VERSION ""

NS_ :

BS_:

BU_: EMS EAS

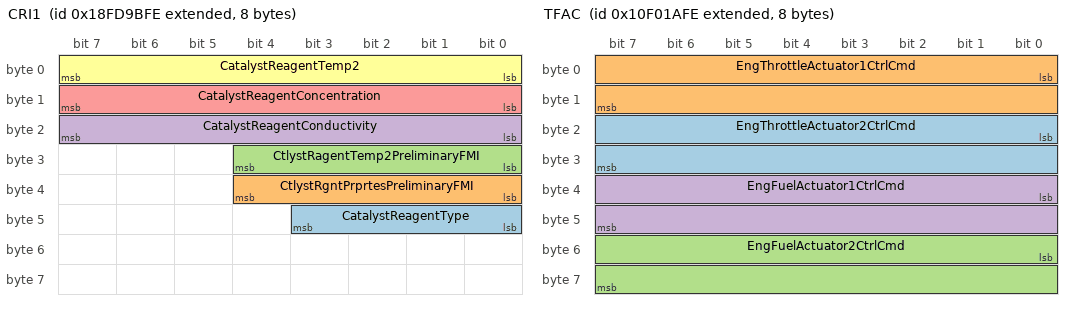
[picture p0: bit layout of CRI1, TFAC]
BO_ 2566757374 CRI1: 8 Vector__XXX
 SG_ CatalystReagentType : 40|4@1+ (1,0) [0|15] "" Vector__XXX
 SG_ CtlystRgntPrprtesPreliminaryFMI : 32|5@1+ (1,0) [0|31] "" Vector__XXX
 SG_ CtlystRagentTemp2PreliminaryFMI : 24|5@1+ (1,0) [0|31] "" Vector__XXX
 SG_ CatalystReagentConductivity : 16|8@1+ (5,0) [0|1250] "microSiemens/mm" Vector__XXX
 SG_ CatalystReagentConcentration : 8|8@1+ (0.25,0) [0|62.5] "%" Vector__XXX
 SG_ CatalystReagentTemp2 : 0|8@1+ (1,-40) [-40|210] "deg" Vector__XXX

BO_ 2566756862 AHI2: 16 Vector__XXX
 SG_ AftrTrtmnt2TtlNmbrOfActvRgnrtns : 96|32@1+ (1,0) [0|4294967295] "counts" Vector__XXX
 SG_ AftrTreatment2TotalDisabledTime : 64|32@1+ (1,0) [0|4211081215] "s" Vector__XXX
 SG_ AftrTrtmnt2TtalRegenerationTime : 32|32@1+ (1,0) [0|4211081215] "s" Vector__XXX
 SG_ AfterTreatment2TotalFuelUsed : 0|32@1+ (0.5,0) [0|2105540607.5] "L" Vector__XXX

BO_ 2566758654 AFC2: 8 Vector__XXX
 SG_ Aftrtratment2FuelEnableActuator : 54|2@1+ (1,0) [0|3] "" Vector__XXX
 SG_ Aftrtratment2RegenerationStatus : 52|2@1+ (1,0) [0|3] "" Vector__XXX
 SG_ Aftertreatment2Ignt : 50|2@1+ (1,0) [0|3] "" Vector__XXX
 SG_ Aftertreatment2FuelPressCtrl : 32|16@1+ (0.0025,0) [0|160.6375] "%" Vector__XXX
 SG_ Aftertreatment2FuelRate : 16|16@1+ (0.05,0) [0|3212.75] "L/h" Vector__XXX
 SG_ Aftertreatment2FuelPress : 0|16@1+ (0.1,0) [0|6425.5] "kPa" Vector__XXX

BO_ 2566758910 AFC1: 8 Vector__XXX
 SG_ Aftrtratment1FuelEnableActuator : 54|2@1+ (1,0) [0|3] "" Vector__XXX
 SG_ Aftrtratment1RegenerationStatus : 52|2@1+ (1,0) [0|3] "" Vector__XXX
 SG_ Aftertreatment1Ignt : 50|2@1+ (1,0) [0|3] "" Vector__XXX
 SG_ Aftertreatment1FuelPressCtrl : 32|16@1+ (0.0025,0) [0|160.6375] "%" Vector__XXX
 SG_ Aftertreatment1FuelRate : 16|16@1+ (0.05,0) [0|3212.75] "L/h" Vector__XXX
 SG_ Aftertreatment1FuelPress : 0|16@1+ (0.1,0) [0|6425.5] "kPa" Vector__XXX

BO_ 2566758142 AAC2: 8 Vector__XXX
 SG_ Aftrtreatment2AirEnableActuator : 62|2@1+ (1,0) [0|3] "" Vector__XXX
 SG_ Aftertreatment2PurgeAirActuator : 60|2@1+ (1,0) [0|3] "" Vector__XXX
 SG_ Aftrtrtmnt2AtmzationAirActuator : 58|2@1+ (1,0) [0|3] "" Vector__XXX
 SG_ Aftertreatment2AirSystemRelay : 56|2@1+ (1,0) [0|3] "" Vector__XXX
 SG_ Aftrtrtment2AirPressActuatorPos : 48|8@1+ (0.4,0) [0|100] "%" Vector__XXX
 SG_ Aftertreatment2AirPressCtrl : 32|16@1+ (0.0025,0) [0|160.6375] "%" Vector__XXX
 SG_ Aftertreatment2PurgeAirPress : 16|16@1+ (0.1,0) [0|6425.5] "kPa" Vector__XXX
 SG_ Aftertreatment2SupplyAirPress : 0|16@1+ (0.1,0) [0|6425.5] "kPa" Vector__XXX

BO_ 2566758398 AAC1: 8 Vector__XXX
 SG_ Aftrtreatment1AirEnableActuator : 62|2@1+ (1,0) [0|3] "" Vector__XXX
 SG_ Aftertreatment1PurgeAirActuator : 60|2@1+ (1,0) [0|3] "" Vector__XXX
 SG_ Aftrtrtmnt1AtmzationAirActuator : 58|2@1+ (1,0) [0|3] "" Vector__XXX
 SG_ Aftertreatment1AirSystemRelay : 56|2@1+ (1,0) [0|3] "" Vector__XXX
 SG_ Aftrtrtment1AirPressActuatorPos : 48|8@1+ (0.4,0) [0|100] "%" Vector__XXX
 SG_ Aftertreatment1AirPressCtrl : 32|16@1+ (0.0025,0) [0|160.6375] "%" Vector__XXX
 SG_ Aftertreatment1PurgeAirPress : 16|16@1+ (0.1,0) [0|6425.5] "kPa" Vector__XXX
 SG_ Aftertreatment1SupplyAirPress : 0|16@1+ (0.1,0) [0|6425.5] "kPa" Vector__XXX

BO_ 2566756606 AHI1: 16 Vector__XXX
 SG_ AftrTrtmnt1TtlNmbrOfActvRgnrtns : 96|32@1+ (1,0) [0|4294967295] "counts" Vector__XXX
 SG_ AftrTrtmnt1TtalRegenerationTime : 32|32@1+ (1,0) [0|4211081215] "s" Vector__XXX
 SG_ AftrTreatment1TotalDisabledTime : 64|32@1+ (1,0) [0|4211081215] "s" Vector__XXX
 SG_ AfterTreatment1TotalFuelUsed : 0|32@1+ (0.5,0) [0|2105540607.5] "L" Vector__XXX

BO_ 2364546302 RGAAQ: 8 Vector__XXX
 SG_ RqdGnrtrAvrgLneLineACRMSVoltage : 0|32@1+ (0.0078125,0) [0|32899071] "V" Vector__XXX

BO_ 2431654654 TFAC: 8 Vector__XXX
 SG_ EngThrottleActuator2CtrlCmd : 16|16@1+ (0.0025,0) [0|160.6375] "%" Vector__XXX
 SG_ EngThrottleActuator1CtrlCmd : 0|16@1+ (0.0025,0) [0|160.6375] "%" Vector__XXX
 SG_ EngFuelActuator2CtrlCmd : 48|16@1+ (0.0025,0) [0|160.6375] "%" Vector__XXX
 SG_ EngFuelActuator1CtrlCmd : 32|16@1+ (0.0025,0) [0|160.6375] "%" Vector__XXX

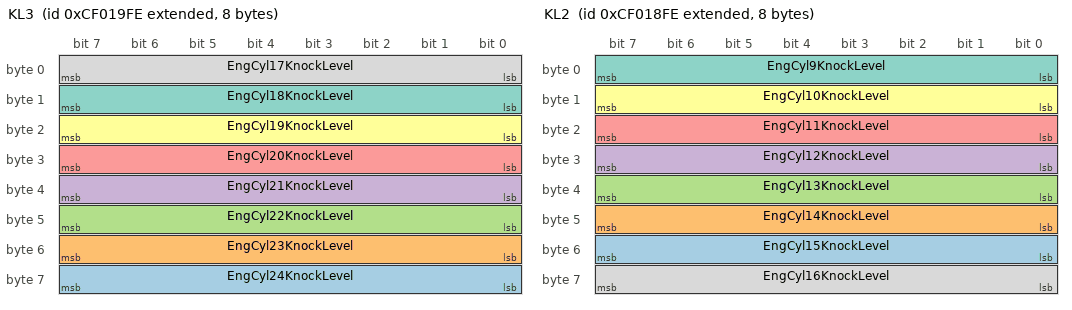
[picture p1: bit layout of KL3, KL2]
BO_ 2364545534 KL3: 8 Vector__XXX
 SG_ EngCyl24KnockLevel : 56|8@1+ (1,0) [0|250] "%" Vector__XXX
 SG_ EngCyl23KnockLevel : 48|8@1+ (1,0) [0|250] "%" Vector__XXX
 SG_ EngCyl22KnockLevel : 40|8@1+ (1,0) [0|250] "%" Vector__XXX
 SG_ EngCyl21KnockLevel : 32|8@1+ (1,0) [0|250] "%" Vector__XXX
 SG_ EngCyl20KnockLevel : 24|8@1+ (1,0) [0|250] "%" Vector__XXX
 SG_ EngCyl19KnockLevel : 16|8@1+ (1,0) [0|250] "%" Vector__XXX
 SG_ EngCyl18KnockLevel : 8|8@1+ (1,0) [0|250] "%" Vector__XXX
 SG_ EngCyl17KnockLevel : 0|8@1+ (1,0) [0|250] "%" Vector__XXX

BO_ 2364545278 KL2: 8 Vector__XXX
 SG_ EngCyl15KnockLevel : 48|8@1+ (1,0) [0|250] "%" Vector__XXX
 SG_ EngCyl14KnockLevel : 40|8@1+ (1,0) [0|250] "%" Vector__XXX
 SG_ EngCyl13KnockLevel : 32|8@1+ (1,0) [0|250] "%" Vector__XXX
 SG_ EngCyl12KnockLevel : 24|8@1+ (1,0) [0|250] "%" Vector__XXX
 SG_ EngCyl11KnockLevel : 16|8@1+ (1,0) [0|250] "%" Vector__XXX
 SG_ EngCyl10KnockLevel : 8|8@1+ (1,0) [0|250] "%" Vector__XXX
 SG_ EngCyl9KnockLevel : 0|8@1+ (1,0) [0|250] "%" Vector__XXX
 SG_ EngCyl16KnockLevel : 56|8@1+ (1,0) [0|250] "%" Vector__XXX

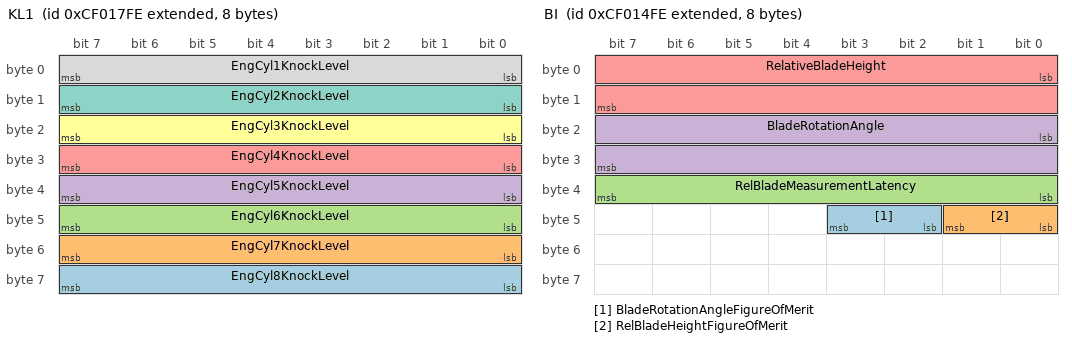
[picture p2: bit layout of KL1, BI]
BO_ 2364545022 KL1: 8 Vector__XXX
 SG_ EngCyl8KnockLevel : 56|8@1+ (1,0) [0|250] "%" Vector__XXX
 SG_ EngCyl7KnockLevel : 48|8@1+ (1,0) [0|250] "%" Vector__XXX
 SG_ EngCyl6KnockLevel : 40|8@1+ (1,0) [0|250] "%" Vector__XXX
 SG_ EngCyl5KnockLevel : 32|8@1+ (1,0) [0|250] "%" Vector__XXX
 SG_ EngCyl4KnockLevel : 24|8@1+ (1,0) [0|250] "%" Vector__XXX
 SG_ EngCyl3KnockLevel : 16|8@1+ (1,0) [0|250] "%" Vector__XXX
 SG_ EngCyl2KnockLevel : 8|8@1+ (1,0) [0|250] "%" Vector__XXX
 SG_ EngCyl1KnockLevel : 0|8@1+ (1,0) [0|250] "%" Vector__XXX

BO_ 2364544766 CCS: 8 Vector__XXX
 SG_ EngCyl9CombustionStatus : 16|2@1+ (1,0) [0|3] "" Vector__XXX
 SG_ EngCyl8CombustionStatus : 14|2@1+ (1,0) [0|3] "" Vector__XXX
 SG_ EngCyl7CombustionStatus : 12|2@1+ (1,0) [0|3] "" Vector__XXX
 SG_ EngCyl6CombustionStatus : 10|2@1+ (1,0) [0|3] "" Vector__XXX
 SG_ EngCyl5CombustionStatus : 8|2@1+ (1,0) [0|3] "" Vector__XXX
 SG_ EngCyl4CombustionStatus : 6|2@1+ (1,0) [0|3] "" Vector__XXX
 SG_ EngCyl3CombustionStatus : 4|2@1+ (1,0) [0|3] "" Vector__XXX
 SG_ EngCyl2CombustionStatus : 2|2@1+ (1,0) [0|3] "" Vector__XXX
 SG_ EngCyl24CombustionStatus : 46|2@1+ (1,0) [0|3] "" Vector__XXX
 SG_ EngCyl23CombustionStatus : 44|2@1+ (1,0) [0|3] "" Vector__XXX
 SG_ EngCyl22CombustionStatus : 42|2@1+ (1,0) [0|3] "" Vector__XXX
 SG_ EngCyl21CombustionStatus : 40|2@1+ (1,0) [0|3] "" Vector__XXX
 SG_ EngCyl20CombustionStatus : 38|2@1+ (1,0) [0|3] "" Vector__XXX
 SG_ EngCyl1CombustionStatus : 0|2@1+ (1,0) [0|3] "" Vector__XXX
 SG_ EngCyl19CombustionStatus : 36|2@1+ (1,0) [0|3] "" Vector__XXX
 SG_ EngCyl18CombustionStatus : 34|2@1+ (1,0) [0|3] "" Vector__XXX
 SG_ EngCyl17CombustionStatus : 32|2@1+ (1,0) [0|3] "" Vector__XXX
 SG_ EngCyl16CombustionStatus : 30|2@1+ (1,0) [0|3] "" Vector__XXX
 SG_ EngCyl15CombustionStatus : 28|2@1+ (1,0) [0|3] "" Vector__XXX
 SG_ EngCyl14CombustionStatus : 26|2@1+ (1,0) [0|3] "" Vector__XXX
 SG_ EngCyl13CombustionStatus : 24|2@1+ (1,0) [0|3] "" Vector__XXX
 SG_ EngCyl12CombustionStatus : 22|2@1+ (1,0) [0|3] "" Vector__XXX
 SG_ EngCyl11CombustionStatus : 20|2@1+ (1,0) [0|3] "" Vector__XXX
 SG_ EngCyl10CombustionStatus : 18|2@1+ (1,0) [0|3] "" Vector__XXX

BO_ 2364544510 RGTARP: 8 Vector__XXX
 SG_ RqGenOverallPowerFactorLagging : 48|2@1+ (1,0) [0|4] "" Vector__XXX
 SG_ RqGeneratorOverallPowerFactor : 32|16@1+ (6.103515625E-005,-1) [-1|2.921814] "" Vector__XXX
 SG_ RqGeneratorTotalACReactivePower : 0|32@1+ (1,-2000000000) [-2000000000|2000000000] "VA" Vector__XXX

BO_ 2364544254 BI: 8 Vector__XXX
 SG_ BladeRotationAngleFigureOfMerit : 42|2@1+ (1,0) [0|3] "" Vector__XXX
 SG_ RelBladeHeightFigureOfMerit : 40|2@1+ (1,0) [0|4] "" Vector__XXX
 SG_ RelBladeMeasurementLatency : 32|8@1+ (0.5,0) [0|125] "ms" Vector__XXX
 SG_ BladeRotationAngle : 16|16@1+ (0.0078125,-200) [-200|301.99] "deg" Vector__XXX
 SG_ RelativeBladeHeight : 0|16@1+ (0.1,-3200) [-3200|3225.5] "mm" Vector__XXX

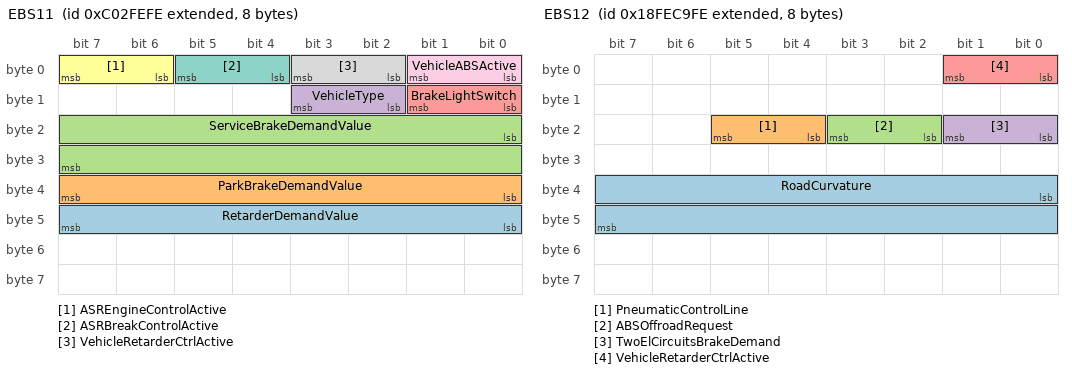
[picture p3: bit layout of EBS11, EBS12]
BO_ 2349006590 EBS11: 8 Vector__XXX
 SG_ RetarderDemandValue : 40|8@1+ (1,-125) [-125|125] "%" Vector__XXX
 SG_ ParkBrakeDemandValue : 32|8@1+ (0.4,0) [0|100] "%" Vector__XXX
 SG_ ServiceBrakeDemandValue : 16|16@1+ (0.01953125,0) [0|1255] "kPa" Vector__XXX
 SG_ VehicleType : 10|2@1+ (1,0) [0|3] "" Vector__XXX
 SG_ BrakeLightSwitch : 8|2@1+ (1,0) [0|3] "" Vector__XXX
 SG_ ASREngineControlActive : 6|2@1+ (1,0) [0|3] "" Vector__XXX
 SG_ ASRBreakControlActive : 4|2@1+ (1,0) [0|3] "" Vector__XXX
 SG_ VehicleRetarderCtrlActive : 2|2@1+ (1,0) [0|3] "" Vector__XXX
 SG_ VehicleABSActive : 0|2@1+ (1,0) [0|1] "" Vector__XXX

BO_ 2566834686 EBS12: 8 Vector__XXX
 SG_ RoadCurvature : 32|16@1+ (0.0078125,-250) [-250|251.992] "1/km" Vector__XXX
 SG_ PneumaticControlLine : 20|2@1+ (1,0) [0|1] "" Vector__XXX
 SG_ ABSOffroadRequest : 18|2@1+ (1,0) [0|1] "" Vector__XXX
 SG_ TwoElCircuitsBrakeDemand : 16|2@1+ (1,0) [0|1] "" Vector__XXX
 SG_ VehicleRetarderCtrlActive : 0|2@1+ (1,0) [0|3] "" Vector__XXX

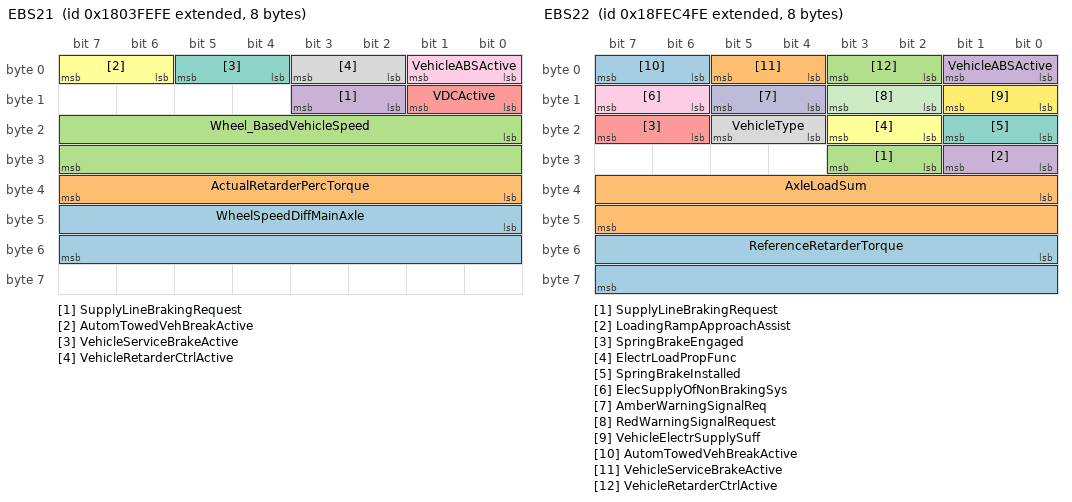
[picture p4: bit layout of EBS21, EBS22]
BO_ 2550398718 EBS21: 8 Vector__XXX
 SG_ WheelSpeedDiffMainAxle : 40|16@1+ (0.00390625,-125) [-125|125] "km/h" Vector__XXX
 SG_ ActualRetarderPercTorque : 32|8@1+ (1,-125) [-125|125] "%" Vector__XXX
 SG_ Wheel_BasedVehicleSpeed : 16|16@1+ (0.00390625,0) [0|251] "km/" Vector__XXX
 SG_ SupplyLineBrakingRequest : 10|2@1+ (1,0) [0|1] "" Vector__XXX
 SG_ VDCActive : 8|2@1+ (1,0) [0|1] "" Vector__XXX
 SG_ AutomTowedVehBreakActive : 6|2@1+ (1,0) [0|1] "" Vector__XXX
 SG_ VehicleServiceBrakeActive : 4|2@1+ (1,0) [0|1] "" Vector__XXX
 SG_ VehicleRetarderCtrlActive : 2|2@1+ (1,0) [0|3] "" Vector__XXX
 SG_ VehicleABSActive : 0|2@1+ (1,0) [0|1] "" Vector__XXX

BO_ 2566833406 EBS22: 8 Vector__XXX
 SG_ ReferenceRetarderTorque : 48|16@1+ (1,0) [0|64255] "Nm" Vector__XXX
 SG_ AxleLoadSum : 32|16@1+ (2,0) [0|128510] "kg" Vector__XXX
 SG_ SupplyLineBrakingRequest : 26|2@1+ (1,0) [0|1] "" Vector__XXX
 SG_ LoadingRampApproachAssist : 24|2@1+ (1,0) [0|1] "" Vector__XXX
 SG_ SpringBrakeEngaged : 22|2@1+ (1,0) [0|1] "" Vector__XXX
 SG_ ElectrLoadPropFunc : 18|2@1+ (1,0) [0|1] "" Vector__XXX
 SG_ SpringBrakeInstalled : 16|2@1+ (1,0) [0|1] "" Vector__XXX
 SG_ VehicleType : 20|2@1+ (1,0) [0|3] "" Vector__XXX
 SG_ ElecSupplyOfNonBrakingSys : 14|2@1+ (1,0) [0|1] "" Vector__XXX
 SG_ AmberWarningSignalReq : 12|2@1+ (1,0) [0|1] "" Vector__XXX
 SG_ RedWarningSignalRequest : 10|2@1+ (1,0) [0|1] "" Vector__XXX
 SG_ VehicleElectrSupplySuff : 8|2@1+ (1,0) [0|1] "" Vector__XXX
 SG_ AutomTowedVehBreakActive : 6|2@1+ (1,0) [0|1] "" Vector__XXX
 SG_ VehicleServiceBrakeActive : 4|2@1+ (1,0) [0|1] "" Vector__XXX
 SG_ VehicleRetarderCtrlActive : 2|2@1+ (1,0) [0|3] "" Vector__XXX
 SG_ VehicleABSActive : 0|2@1+ (1,0) [0|1] "" Vector__XXX

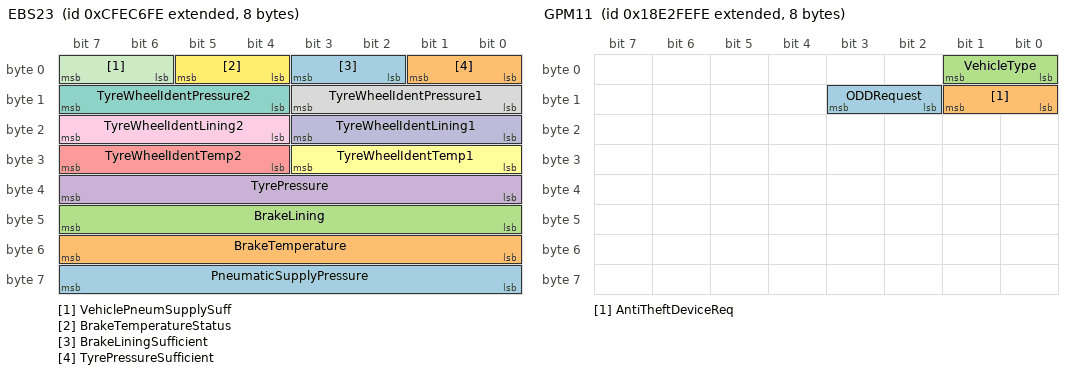
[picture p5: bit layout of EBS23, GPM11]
BO_ 2365507326 EBS23: 8 Vector__XXX
 SG_ PneumaticSupplyPressure : 56|8@1+ (5,0) [0|1250] "kPa" Vector__XXX
 SG_ BrakeTemperature : 48|8@1+ (10,0) [0|2500] "°C" Vector__XXX
 SG_ BrakeLining : 40|8@1+ (0.4,0) [0|100] "%" Vector__XXX
 SG_ TyrePressure : 32|8@1+ (10,0) [0|2500] "kPa" Vector__XXX
 SG_ TyreWheelIdentTemp2 : 28|4@1+ (1,0) [0|15] "" Vector__XXX
 SG_ TyreWheelIdentTemp1 : 24|4@1+ (1,0) [0|15] "" Vector__XXX
 SG_ TyreWheelIdentPressure2 : 12|4@1+ (1,0) [0|15] "" Vector__XXX
 SG_ TyreWheelIdentPressure1 : 8|4@1+ (1,0) [0|15] "" Vector__XXX
 SG_ TyreWheelIdentLining2 : 20|4@1+ (1,0) [0|15] "" Vector__XXX
 SG_ TyreWheelIdentLining1 : 16|4@1+ (1,0) [0|15] "" Vector__XXX
 SG_ VehiclePneumSupplySuff : 6|2@1+ (1,0) [0|1] "" Vector__XXX
 SG_ BrakeTemperatureStatus : 4|2@1+ (1,0) [0|1] "" Vector__XXX
 SG_ BrakeLiningSufficient : 2|2@1+ (1,0) [0|1] "" Vector__XXX
 SG_ TyrePressureSufficient : 0|2@1+ (1,0) [0|1] "" Vector__XXX

BO_ 2565013246 GPM11: 8 Vector__XXX
 SG_ ODDRequest : 10|2@1+ (1,0) [0|3] "" Vector__XXX
 SG_ AntiTheftDeviceReq : 8|2@1+ (1,0) [0|3] "" Vector__XXX
 SG_ VehicleType : 0|2@1+ (1,0) [0|3] "" Vector__XXX

BO_ 2566807038 GPM12: 8 Vector__XXX
 SG_ MaxVehicleSpeedLimit : 32|8@1+ (1,0) [0|250] "km/h" Vector__XXX
 SG_ EngineSpeedUpperLimit : 0|16@1+ (0.125,0) [0|8031.875] "rpm" Vector__XXX
 SG_ EngineSpeedLowerLimit : 16|16@1+ (0.125,0) [0|8191.875] "rpm" Vector__XXX

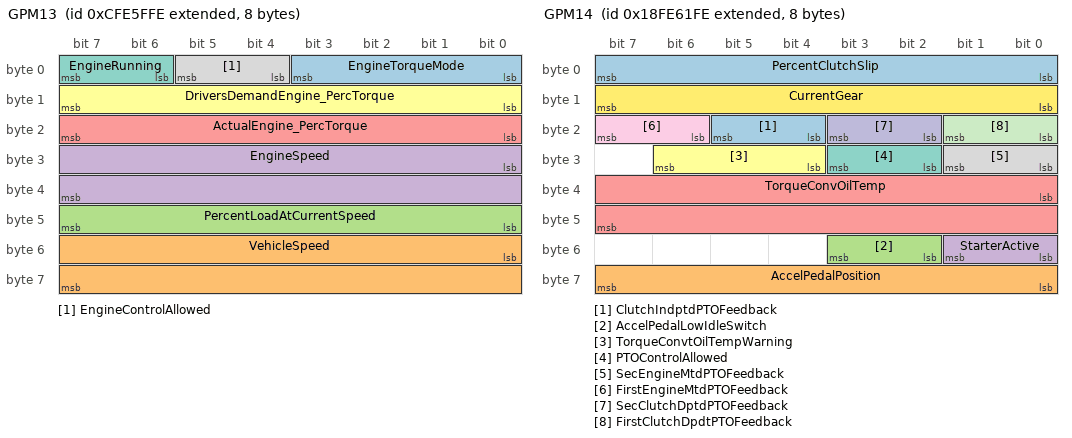
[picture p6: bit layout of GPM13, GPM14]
BO_ 2365480958 GPM13: 8 Vector__XXX
 SG_ EngineTorqueMode : 0|4@1+ (1,0) [0|15] "" Vector__XXX
 SG_ VehicleSpeed : 48|16@1+ (0.00390625,0) [0|250.996] "km/h" Vector__XXX
 SG_ PercentLoadAtCurrentSpeed : 40|8@1+ (1,0) [0|125] "%" Vector__XXX
 SG_ EngineSpeed : 24|16@1+ (0.125,0) [0|8031.88] "rpm" Vector__XXX
 SG_ ActualEngine_PercTorque : 16|8@1+ (1,-125) [-125|125] "%" Vector__XXX
 SG_ DriversDemandEngine_PercTorque : 8|8@1+ (1,-125) [-125|125] "%" Vector__XXX
 SG_ EngineRunning : 6|2@1+ (1,0) [0|1] "" Vector__XXX
 SG_ EngineControlAllowed : 4|2@1+ (1,0) [0|1] "" Vector__XXX

BO_ 2566808062 GPM14: 8 Vector__XXX
 SG_ ClutchIndptdPTOFeedback : 20|2@1+ (1,0) [0|1] "" Vector__XXX
 SG_ AccelPedalPosition : 56|8@1+ (0.4,0) [0|100] "%" Vector__XXX
 SG_ AccelPedalLowIdleSwitch : 50|2@1+ (1,0) [0|1] "" Vector__XXX
 SG_ StarterActive : 48|2@1+ (1,0) [0|1] "" Vector__XXX
 SG_ TorqueConvOilTemp : 32|16@1+ (0.03125,-273) [-273|1735] "°C" Vector__XXX
 SG_ TorqueConvtOilTempWarning : 28|3@1+ (1,0) [0|2] "" Vector__XXX
 SG_ PTOControlAllowed : 26|2@1+ (1,0) [0|1] "" Vector__XXX
 SG_ SecEngineMtdPTOFeedback : 24|2@1+ (1,0) [0|1] "" Vector__XXX
 SG_ FirstEngineMtdPTOFeedback : 22|2@1+ (1,0) [0|1] "" Vector__XXX
 SG_ SecClutchDptdPTOFeedback : 18|2@1+ (1,0) [0|1] "" Vector__XXX
 SG_ FirstClutchDpdtPTOFeedback : 16|2@1+ (1,0) [0|1] "" Vector__XXX
 SG_ CurrentGear : 8|8@1+ (1,-125) [-125|125] "" Vector__XXX
 SG_ PercentClutchSlip : 0|8@1+ (0.4,0) [0|100] "%" Vector__XXX

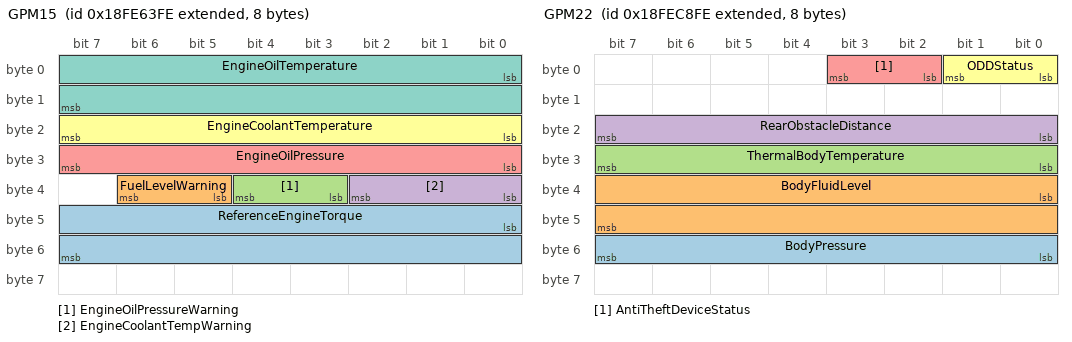
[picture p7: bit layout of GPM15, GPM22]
BO_ 2566808574 GPM15: 8 Vector__XXX
 SG_ ReferenceEngineTorque : 40|16@1+ (1,0) [0|64255] "Nm" Vector__XXX
 SG_ FuelLevelWarning : 37|2@1+ (1,0) [0|1] "" Vector__XXX
 SG_ EngineOilPressureWarning : 35|2@1+ (1,0) [0|1] "" Vector__XXX
 SG_ EngineCoolantTempWarning : 32|3@1+ (1,0) [0|2] "" Vector__XXX
 SG_ EngineOilPressure : 24|8@1+ (4,0) [0|1000] "kPa" Vector__XXX
 SG_ EngineCoolantTemperature : 16|8@1+ (1,-40) [-40|210] "°C" Vector__XXX
 SG_ EngineOilTemperature : 0|16@1+ (0.03125,-273) [-273|1735] "°C" Vector__XXX

BO_ 2566809086 GPM16: 8 Vector__XXX
 SG_ AmbientAirTemperature : 0|16@1+ (0.03125,-273) [-273|1735] "°C" Vector__XXX

BO_ 2564947710 GPM21: 8 Vector__XXX
 SG_ VehicleType : 0|2@1+ (1,0) [0|3] "" Vector__XXX

BO_ 2566834430 GPM22: 8 Vector__XXX
 SG_ BodyPressure : 48|8@1+ (0.1,0) [0|25] "bar" Vector__XXX
 SG_ BodyFluidLevel : 32|16@1+ (2,0) [0|128510] "l" Vector__XXX
 SG_ ThermalBodyTemperature : 24|8@1+ (1,-125) [-125|125] "°C" Vector__XXX
 SG_ RearObstacleDistance : 16|8@1+ (2,0) [0|500] "cm" Vector__XXX
 SG_ AntiTheftDeviceStatus : 2|2@1+ (1,0) [0|1] "" Vector__XXX
 SG_ ODDStatus : 0|2@1+ (1,0) [0|1] "" Vector__XXX

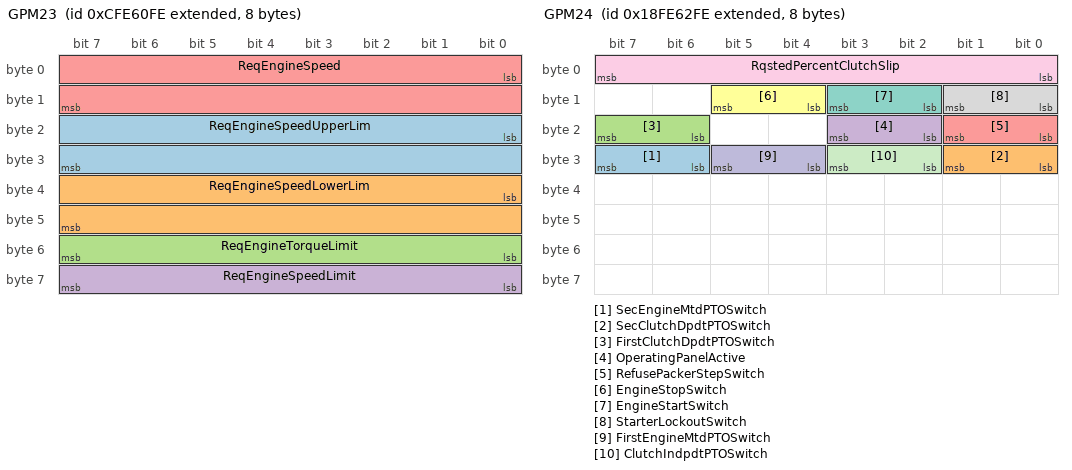
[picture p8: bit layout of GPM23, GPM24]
BO_ 2365481214 GPM23: 8 Vector__XXX
 SG_ ReqEngineSpeedUpperLim : 16|16@1+ (0.125,0) [0|8031.875] "rpm" Vector__XXX
 SG_ ReqEngineSpeedLowerLim : 32|16@1+ (0.125,0) [0|8031.875] "rpm" Vector__XXX
 SG_ ReqEngineTorqueLimit : 48|8@1+ (1,-125) [-125|125] "%" Vector__XXX
 SG_ ReqEngineSpeedLimit : 56|8@1+ (1,0) [0|250] "km/h" Vector__XXX
 SG_ ReqEngineSpeed : 0|16@1+ (0.125,0) [0|8031.875] "rpm" Vector__XXX

BO_ 2566808318 GPM24: 8 Vector__XXX
 SG_ SecEngineMtdPTOSwitch : 30|2@1+ (1,0) [0|1] "" Vector__XXX
 SG_ SecClutchDpdtPTOSwitch : 24|2@1+ (1,0) [0|1] "" Vector__XXX
 SG_ FirstClutchDpdtPTOSwitch : 22|2@1+ (1,0) [0|1] "" Vector__XXX
 SG_ OperatingPanelActive : 18|2@1+ (1,0) [0|1] "" Vector__XXX
 SG_ RefusePackerStepSwitch : 16|2@1+ (1,0) [0|1] "" Vector__XXX
 SG_ EngineStopSwitch : 12|2@1+ (1,0) [0|1] "" Vector__XXX
 SG_ EngineStartSwitch : 10|2@1+ (1,0) [0|3] "" Vector__XXX
 SG_ StarterLockoutSwitch : 8|2@1+ (1,0) [0|1] "" Vector__XXX
 SG_ RqstedPercentClutchSlip : 0|8@1+ (0.4,0) [0|100] "%" Vector__XXX
 SG_ FirstEngineMtdPTOSwitch : 28|2@1+ (1,0) [0|1] "" Vector__XXX
 SG_ ClutchIndpdtPTOSwitch : 26|2@1+ (1,0) [0|1] "" Vector__XXX

BO_ 2566808830 GPM25: 8 Vector__XXX
 SG_ TrailerLeftSideMarkerLight : 20|2@1+ (1,0) [0|3] "" Vector__XXX
 SG_ TrailerLeftReversingLight : 16|2@1+ (1,0) [0|3] "" Vector__XXX
 SG_ TrailerLeftRearWidIndLight : 24|2@1+ (1,0) [0|3] "" Vector__XXX
 SG_ TrailerLeftRearRegPltLight : 32|2@1+ (1,0) [0|3] "" Vector__XXX
 SG_ TrailerLeftRearLight : 8|2@1+ (1,0) [0|3] "" Vector__XXX
 SG_ TrailerLeftRearFogLight : 12|2@1+ (1,0) [0|3] "" Vector__XXX
 SG_ TrailerLeftDirIndLight : 4|2@1+ (1,0) [0|3] "" Vector__XXX
 SG_ TrailerLeftCrnMarkerLight : 28|2@1+ (1,0) [0|3] "" Vector__XXX
 SG_ TrailerInteriorLight : 40|2@1+ (1,0) [0|3] "" Vector__XXX
 SG_ TrailerWorkLamp : 42|2@1+ (1,0) [0|3] "" Vector__XXX
 SG_ TrailerRotatingIdentLight : 38|2@1+ (1,0) [0|3] "" Vector__XXX
 SG_ TrailerRightStopLight : 2|2@1+ (1,0) [0|3] "" Vector__XXX
 SG_ TrailerRightSideMrkLight : 22|2@1+ (1,0) [0|3] "" Vector__XXX
 SG_ TrailerRightReversingLight : 18|2@1+ (1,0) [0|3] "" Vector__XXX
 SG_ TrailRightRearWidIndLight : 26|2@1+ (1,0) [0|3] "" Vector__XXX
 SG_ TrailerRightRearRegPltLight : 34|2@1+ (1,0) [0|3] "" Vector__XXX
 SG_ TrailerRightRearLight : 10|2@1+ (1,0) [0|3] "" Vector__XXX
 SG_ TrailerRightRearFogLight : 14|2@1+ (1,0) [0|3] "" Vector__XXX
 SG_ TrailerRightDirIndLight : 6|2@1+ (1,0) [0|3] "" Vector__XXX
 SG_ TrailerRightCrnMarkerLight : 30|2@1+ (1,0) [0|3] "" Vector__XXX
 SG_ TrailerRearWarningLight : 36|2@1+ (1,0) [0|3] "" Vector__XXX
 SG_ TrailerLeftStopLight : 0|2@1+ (1,0) [0|3] "" Vector__XXX

BO_ 2564554494 ISO15765_Funct: 8 Vector__XXX
 SG_ SN m2 : 0|4@1+ (1,0) [0|15] "" Vector__XXX
 SG_ SeparationTime m3 : 16|8@1+ (1,0) [0|255] "ms" Vector__XXX
 SG_ BlockSize m3 : 8|8@1+ (1,0) [0|255] "" Vector__XXX
 SG_ FlowStatus m3 : 0|4@1+ (1,0) [0|3] "" Vector__XXX
 SG_ FirstFrameDataLength m1 : 3|12@0+ (1,0) [0|4095] "Byte" Vector__XXX
 SG_ SingleFrameDataLength m0 : 0|4@1+ (1,0) [0|7] "Byte" Vector__XXX
 SG_ ProtocolCtrlInformation M : 4|4@1+ (1,0) [0|3] "" Vector__XXX

BO_ 2564488958 ISO15765_Phys: 8 Vector__XXX
 SG_ SN m2 : 0|4@1+ (1,0) [0|15] "" Vector__XXX
 SG_ SeparationTime m3 : 16|8@1+ (1,0) [0|255] "ms" Vector__XXX
 SG_ BlockSize m3 : 8|8@1+ (1,0) [0|255] "" Vector__XXX
 SG_ FlowStatus m3 : 0|4@1+ (1,0) [0|3] "" Vector__XXX
 SG_ FirstFrameDataLength m1 : 3|12@0+ (1,0) [0|4095] "Byte" Vector__XXX
 SG_ SingleFrameDataLength m0 : 0|4@1+ (1,0) [0|7] "Byte" Vector__XXX
 SG_ ProtocolCtrlInformation M : 4|4@1+ (1,0) [0|3] "" Vector__XXX

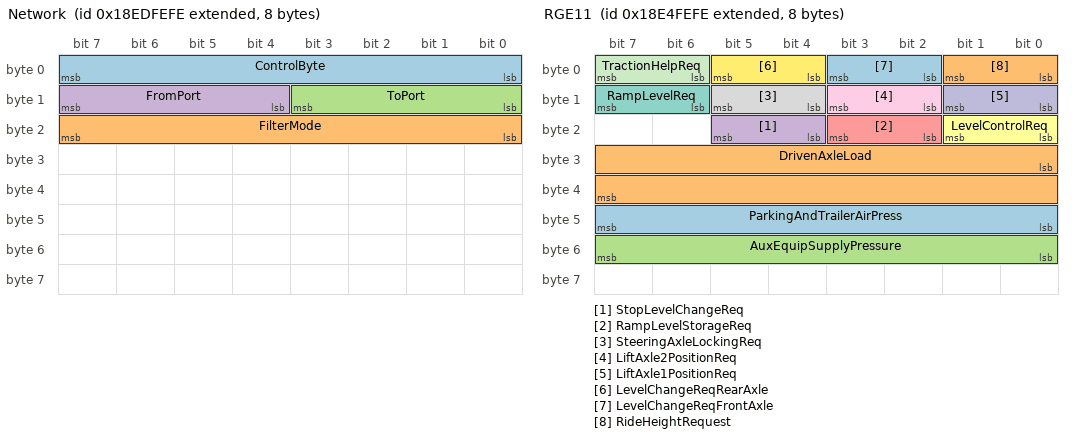
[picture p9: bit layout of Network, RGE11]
BO_ 2565734142 Network: 8 Vector__XXX
 SG_ ControlByte : 0|8@1+ (1,0) [0|255] "" Vector__XXX
 SG_ FilterMode : 16|8@1+ (1,0) [0|255] "" Vector__XXX
 SG_ ToPort : 8|4@1+ (1,0) [0|15] "" Vector__XXX
 SG_ FromPort : 12|4@1+ (1,0) [0|15] "" Vector__XXX

BO_ 2565144318 RGE11: 8 Vector__XXX
 SG_ ParkingAndTrailerAirPress : 40|8@1+ (8,0) [0|2000] "kPa" Vector__XXX
 SG_ DrivenAxleLoad : 24|16@1+ (2,0) [0|128510] "kg" Vector__XXX
 SG_ AuxEquipSupplyPressure : 48|8@1+ (8,0) [0|2000] "kPa" Vector__XXX
 SG_ StopLevelChangeReq : 20|2@1+ (1,0) [0|3] "" Vector__XXX
 SG_ RampLevelStorageReq : 18|2@1+ (1,0) [0|3] "" Vector__XXX
 SG_ LevelControlReq : 16|2@1+ (1,0) [0|3] "" Vector__XXX
 SG_ RampLevelReq : 14|2@1+ (1,0) [0|3] "" Vector__XXX
 SG_ SteeringAxleLockingReq : 12|2@1+ (1,0) [0|3] "" Vector__XXX
 SG_ LiftAxle2PositionReq : 10|2@1+ (1,0) [0|3] "" Vector__XXX
 SG_ LiftAxle1PositionReq : 8|2@1+ (1,0) [0|3] "" Vector__XXX
 SG_ TractionHelpReq : 6|2@1+ (1,0) [0|3] "" Vector__XXX
 SG_ LevelChangeReqRearAxle : 4|2@1+ (1,0) [0|3] "" Vector__XXX
 SG_ LevelChangeReqFrontAxle : 2|2@1+ (1,0) [0|3] "" Vector__XXX
 SG_ RideHeightRequest : 0|2@1+ (1,0) [0|3] "" Vector__XXX

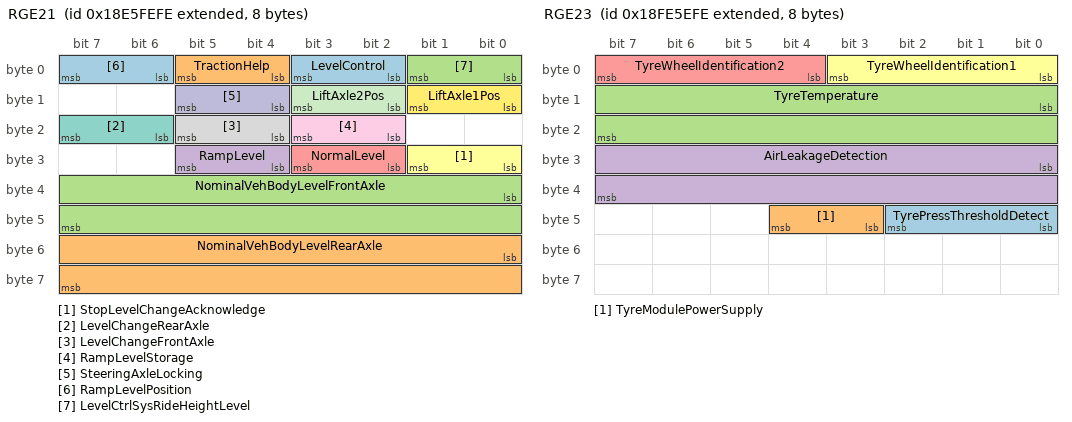
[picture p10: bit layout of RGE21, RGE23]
BO_ 2565209854 RGE21: 8 Vector__XXX
 SG_ LevelControl : 2|2@1+ (1,0) [0|1] "" Vector__XXX
 SG_ NominalVehBodyLevelRearAxle : 48|16@1+ (1,0) [0|64255] "mm" Vector__XXX
 SG_ NominalVehBodyLevelFrontAxle : 32|16@1+ (1,0) [0|64255] "mm" Vector__XXX
 SG_ RampLevel : 28|2@1+ (1,0) [0|1] "" Vector__XXX
 SG_ NormalLevel : 26|2@1+ (1,0) [0|3] "" Vector__XXX
 SG_ StopLevelChangeAcknowledge : 24|2@1+ (1,0) [0|1] "" Vector__XXX
 SG_ LevelChangeRearAxle : 22|2@1+ (1,0) [0|1] "" Vector__XXX
 SG_ LevelChangeFrontAxle : 20|2@1+ (1,0) [0|1] "" Vector__XXX
 SG_ RampLevelStorage : 18|2@1+ (1,0) [0|1] "" Vector__XXX
 SG_ SteeringAxleLocking : 12|2@1+ (1,0) [0|3] "" Vector__XXX
 SG_ LiftAxle2Pos : 10|2@1+ (1,0) [0|3] "" Vector__XXX
 SG_ LiftAxle1Pos : 8|2@1+ (1,0) [0|3] "" Vector__XXX
 SG_ RampLevelPosition : 6|2@1+ (1,0) [0|3] "" Vector__XXX
 SG_ TractionHelp : 4|2@1+ (1,0) [0|1] "" Vector__XXX
 SG_ LevelCtrlSysRideHeightLevel : 0|2@1+ (1,0) [0|1] "" Vector__XXX

BO_ 2566806782 RGE22: 8 Vector__XXX
 SG_ RelVehBodyLevelRearAxle : 16|16@1+ (1,0) [0|64255] "mm" Vector__XXX
 SG_ RelVehBodyLevelFrontAxle : 0|16@1+ (1,-32000) [-32000|32255] "mm" Vector__XXX

BO_ 2566807294 RGE23: 8 Vector__XXX
 SG_ TyrePressThresholdDetect : 40|3@1+ (1,0) [0|7] "" Vector__XXX
 SG_ TyreModulePowerSupply : 43|2@1+ (1,0) [0|1] "" Vector__XXX
 SG_ TyreTemperature : 8|16@1+ (0.03125,-273) [-273|1735] "°C" Vector__XXX
 SG_ AirLeakageDetection : 24|16@1+ (0.1,0) [0|6425.5] "Pa/s" Vector__XXX
 SG_ TyreWheelIdentification2 : 4|4@1+ (1,0) [0|15] "" Vector__XXX
 SG_ TyreWheelIdentification1 : 0|4@1+ (1,0) [0|15] "" Vector__XXX

BO_ 2566764798 DM26: 8 Vector__XXX
 SG_ MisfireMonitoringComplete : 28|1@1+ (1,0) [0|0] "" Vector__XXX
 SG_ MisfireMonitoringEnabled : 24|1@1+ (1,0) [0|0] "" Vector__XXX
 SG_ FuelSystemMonitoringEnabled : 25|1@1+ (1,0) [0|1] "" Vector__XXX
 SG_ ComprehensiveComptMonComplete : 30|1@1+ (1,0) [0|0] "" Vector__XXX
 SG_ ComprehensiveCompMonEnabled : 26|1@1+ (1,0) [0|1] "" Vector__XXX
 SG_ SecondAirSystemMonComplete : 51|1@1+ (1,0) [0|1] "" Vector__XXX
 SG_ SecondAirSystemMonEnabled : 35|1@1+ (1,0) [0|1] "" Vector__XXX
 SG_ OxygenSensorMonComplete : 53|1@1+ (1,0) [0|1] "" Vector__XXX
 SG_ OxygenSensorMonEnabled : 37|1@1+ (1,0) [0|1] "" Vector__XXX
 SG_ OxygenSensorHeaterMonComplete : 54|1@1+ (1,0) [0|1] "" Vector__XXX
 SG_ OxygenSensorHeaterMonEnabled : 38|1@1+ (1,0) [0|1] "" Vector__XXX
 SG_ HeatedCatalystMonComplete : 49|1@1+ (1,0) [0|0] "" Vector__XXX
 SG_ HeatedCatalystMonEnabled : 33|1@1+ (1,0) [0|0] "" Vector__XXX
 SG_ EvaporativeSystemMonComplete : 50|1@1+ (1,0) [0|1] "" Vector__XXX
 SG_ EvaporativeSystemMonEnabled : 34|1@1+ (1,0) [0|1] "" Vector__XXX
 SG_ EGRSystemMonitoringComplete : 55|1@1+ (1,0) [0|1] "" Vector__XXX
 SG_ EGRSystemMonitoringEnabled : 39|1@1+ (1,0) [0|1] "" Vector__XXX
 SG_ ColdStartAidSystemMonComplete : 56|1@1+ (1,0) [0|1] "" Vector__XXX
 SG_ ColdStartAidSystemMonEnabled : 40|1@1+ (1,0) [0|1] "" Vector__XXX
 SG_ CatalystMonComplete : 48|1@1+ (1,0) [0|1] "" Vector__XXX
 SG_ CatalystMonEnabled : 32|1@1+ (1,0) [0|1] "" Vector__XXX
 SG_ ACSystemRefrigerantMonComplete : 52|1@1+ (1,0) [0|1] "" Vector__XXX
 SG_ ACSystemRefrigerantMonEnabled : 36|1@1+ (1,0) [0|1] "" Vector__XXX
 SG_ FuelSystemMonitoringComplete : 29|1@1+ (1,0) [0|1] "" Vector__XXX
 SG_ NumOfWarmUpsSinceDTCsCleared : 16|8@1+ (1,0) [0|250] "" Vector__XXX
 SG_ TimeSinceEngineStart : 0|16@1+ (1,0) [0|64255] "seconds" Vector__XXX

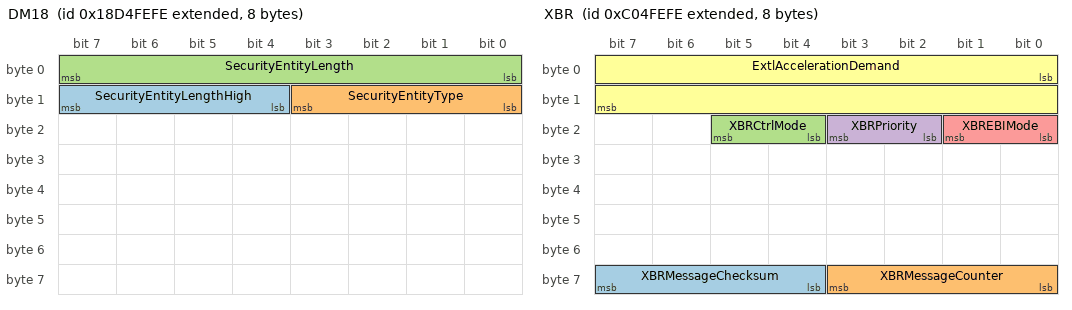
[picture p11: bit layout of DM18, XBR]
BO_ 2564095742 DM18: 8 Vector__XXX
 SG_ SecurityEntityLengthHigh : 12|4@1+ (1,0) [0|255] "Byte" Vector__XXX
 SG_ SecurityEntityType : 8|4@1+ (1,0) [0|15] "" Vector__XXX
 SG_ SecurityEntityLength : 0|8@1+ (1,0) [0|1785] "Byte" Vector__XXX

BO_ 2349137662 XBR: 8 Vector__XXX
 SG_ XBRMessageChecksum : 60|4@1+ (1,0) [0|15] "" Vector__XXX
 SG_ XBRMessageCounter : 56|4@1+ (1,0) [0|15] "" Vector__XXX
 SG_ XBRCtrlMode : 20|2@1+ (1,0) [0|3] "" Vector__XXX
 SG_ XBRPriority : 18|2@1+ (1,0) [0|3] "" Vector__XXX
 SG_ XBREBIMode : 16|2@1+ (1,0) [0|3] "" Vector__XXX
 SG_ ExtlAccelerationDemand : 0|16@1+ (0.000488281,-15.687) [-15.687|15.687] "m/s²" Vector__XXX

BO_ 2566848510 WFI: 8 Vector__XXX
 SG_ WaterInFuelIndicator : 0|2@1+ (1,0) [0|3] "" Vector__XXX

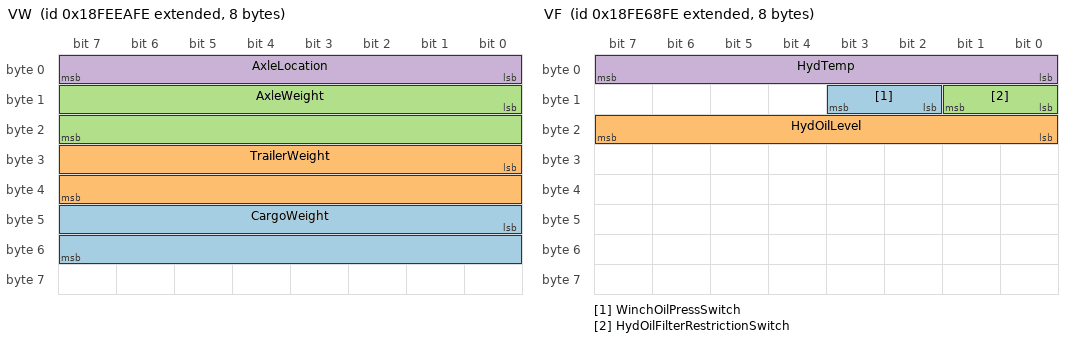
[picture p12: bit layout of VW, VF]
BO_ 2566843134 VW: 8 Vector__XXX
 SG_ CargoWeight : 40|16@1+ (2,0) [0|128510] "kg" Vector__XXX
 SG_ TrailerWeight : 24|16@1+ (2,0) [0|128510] "kg" Vector__XXX
 SG_ AxleWeight : 8|16@1+ (0.5,0) [0|32127.5] "kg" Vector__XXX
 SG_ AxleLocation : 0|8@1+ (1,0) [0|255] "" Vector__XXX

BO_ 2566804222 VP3: 8 Vector__XXX
 SG_ NetBatteryCurrentHiRes : 16|16@1+ (0.05,-1600) [-1600|1676.75] "A" Vector__XXX
 SG_ AltCurrentHiRes : 0|16@1+ (0.05,-1600) [-1600|1676.75] "A" Vector__XXX

BO_ 2633928190 VP2: 8 Vector__XXX
 SG_ Battery2Potential : 0|16@1+ (0.05,0) [0|3212.75] "V" Vector__XXX

BO_ 2566845438 VP: 8 Vector__XXX
 SG_ Longitude : 32|32@1+ (10,-210) [-210|211.1008122] "deg" Vector__XXX
 SG_ Latitude : 0|32@1+ (10,-210) [-210|211.1008122] "deg" Vector__XXX

BO_ 2566843646 VI: 8 Vector__XXX

BO_ 2566842366 VH: 8 Vector__XXX
 SG_ TotalPowerTakeoffHours : 32|32@1+ (0.05,0) [0|210554060.75] "hr" Vector__XXX
 SG_ TotalVehicleHours : 0|32@1+ (0.05,0) [0|210554060.75] "hr" Vector__XXX

BO_ 2566809854 VF: 8 Vector__XXX
 SG_ WinchOilPressSwitch : 10|2@1+ (1,0) [0|3] "" Vector__XXX
 SG_ HydOilLevel : 16|8@1+ (0.4,0) [0|100] "%" Vector__XXX
 SG_ HydOilFilterRestrictionSwitch : 8|2@1+ (1,0) [0|3] "" Vector__XXX
 SG_ HydTemp : 0|8@1+ (1,-40) [-40|210] "deg" Vector__XXX

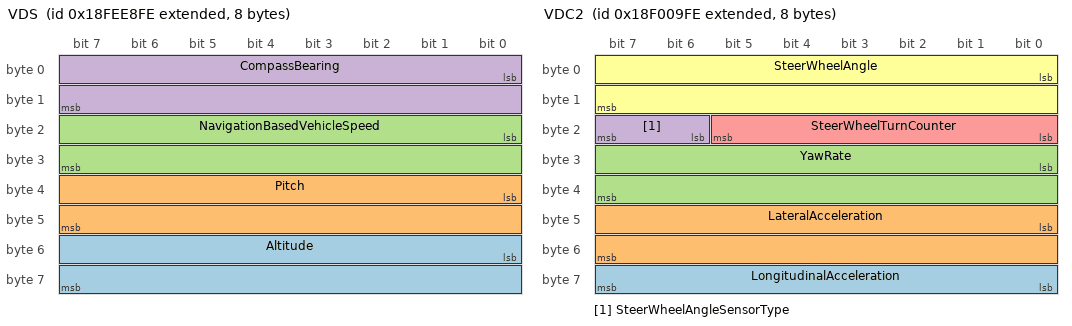
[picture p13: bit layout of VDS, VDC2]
BO_ 2566842622 VDS: 8 Vector__XXX
 SG_ Altitude : 48|16@1+ (0.125,-2500) [-2500|5531.875] "m" Vector__XXX
 SG_ Pitch : 32|16@1+ (0.0078125,-200) [-200|301.99] "deg" Vector__XXX
 SG_ NavigationBasedVehicleSpeed : 16|16@1+ (0.00390625,0) [0|250.996] "km/h" Vector__XXX
 SG_ CompassBearing : 0|16@1+ (0.0078125,0) [0|501.99] "deg" Vector__XXX

BO_ 2566832638 VDHR: 8 Vector__XXX
 SG_ HighResolutionTripDistance : 32|32@1+ (5,0) [0|21055406] "km" Vector__XXX
 SG_ HghRslutionTotalVehicleDistance : 0|32@1+ (5,0) [0|21055406] "km" Vector__XXX

BO_ 2565868030 VDC2: 8 Vector__XXX
 SG_ LongitudinalAcceleration : 56|8@1+ (0.1,-12.5) [-12.5|12.5] "m/s²" Vector__XXX
 SG_ LateralAcceleration : 40|16@1+ (0.000488281,-15.687) [-15.687|15.687] "m/s²" Vector__XXX
 SG_ YawRate : 24|16@1+ (0.00012207,-3.92) [-3.92|3.92] "rad/s" Vector__XXX
 SG_ SteerWheelAngleSensorType : 22|2@1+ (1,0) [0|3] "" Vector__XXX
 SG_ SteerWheelTurnCounter : 16|6@1+ (1,-32) [-32|29] "turns" Vector__XXX
 SG_ SteerWheelAngle : 0|16@1+ (0.000976563,-31.374) [-31.374|31.374] "rad" Vector__XXX

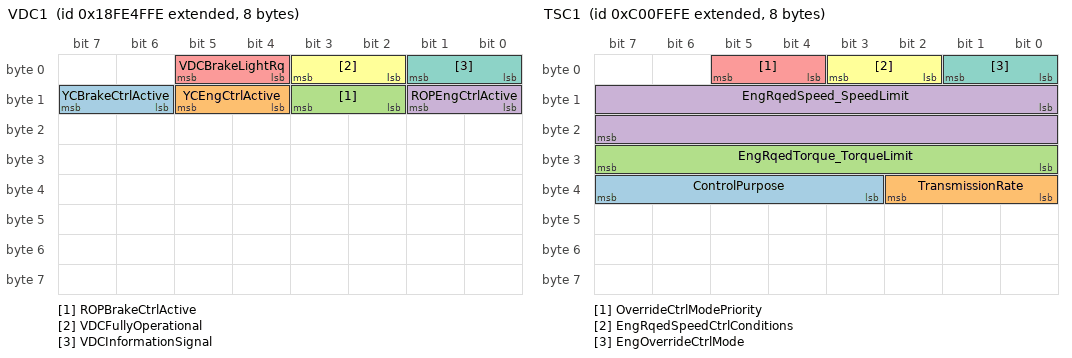
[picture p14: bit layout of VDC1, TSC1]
BO_ 2566803454 VDC1: 8 Vector__XXX
 SG_ YCBrakeCtrlActive : 14|2@1+ (1,0) [0|3] "" Vector__XXX
 SG_ YCEngCtrlActive : 12|2@1+ (1,0) [0|3] "" Vector__XXX
 SG_ ROPBrakeCtrlActive : 10|2@1+ (1,0) [0|3] "" Vector__XXX
 SG_ ROPEngCtrlActive : 8|2@1+ (1,0) [0|3] "" Vector__XXX
 SG_ VDCBrakeLightRq : 4|2@1+ (1,0) [0|3] "" Vector__XXX
 SG_ VDCFullyOperational : 2|2@1+ (1,0) [0|3] "" Vector__XXX
 SG_ VDCInformationSignal : 0|2@1+ (1,0) [0|3] "" Vector__XXX

BO_ 2566840574 VD: 8 Vector__XXX
 SG_ TotalVehicleDistance : 32|32@1+ (0.125,0) [0|526385151.9] "km" Vector__XXX
 SG_ TripDistance : 0|32@1+ (0.125,0) [0|526385151.9] "km" Vector__XXX

BO_ 2633938686 TVI: 8 Vector__XXX
 SG_ TripCruiseDistance : 16|32@1+ (0.125,0) [0|526385151.9] "km" Vector__XXX
 SG_ TripMaxVehicleSpeed : 0|16@1+ (0.00390625,0) [0|250.996] "km/h" Vector__XXX

BO_ 2633937150 TTI2: 20 Vector__XXX
 SG_ TripAirCompressorOnTime : 128|32@1+ (0.05,0) [0|210554060.75] "hr" Vector__XXX
 SG_ TripIdleTime : 96|32@1+ (0.05,0) [0|210554060.75] "hr" Vector__XXX
 SG_ TripEngRunningTime : 64|32@1+ (0.05,0) [0|210554060.75] "hr" Vector__XXX
 SG_ TripPTOTime : 32|32@1+ (0.05,0) [0|210554060.75] "hr" Vector__XXX
 SG_ TripCruiseTime : 0|32@1+ (0.05,0) [0|210554060.75] "hr" Vector__XXX

BO_ 2633938174 TTI1: 16 Vector__XXX
 SG_ TripTimeInDerateByEng : 96|32@1+ (0.05,0) [0|210554060.75] "hr" Vector__XXX
 SG_ TripTimeInGearDown : 64|32@1+ (0.05,0) [0|210554060.75] "hr" Vector__XXX
 SG_ TripTimeInTopGear : 32|32@1+ (0.05,0) [0|210554060.75] "hr" Vector__XXX
 SG_ TripTimeInVSL : 0|32@1+ (0.05,0) [0|210554060.75] "hr" Vector__XXX

BO_ 2633938430 TSI: 8 Vector__XXX
 SG_ TripSuddenDecelerations : 48|16@1+ (1,0) [0|64255] "counts" Vector__XXX
 SG_ TrpNmberOfIdleShutdownOverrides : 32|16@1+ (1,0) [0|64255] "counts" Vector__XXX
 SG_ TripNumberOfIdleShutdowns : 16|16@1+ (1,0) [0|64255] "counts" Vector__XXX
 SG_ TripNumberOfHotShutdowns : 0|16@1+ (1,0) [0|64255] "counts" Vector__XXX

BO_ 2348875518 TSC1: 8 Vector__XXX
 SG_ ControlPurpose : 35|5@1+ (1,0) [0|31] "" Vector__XXX
 SG_ TransmissionRate : 32|3@1+ (1,0) [0|7] "" Vector__XXX
 SG_ EngRqedTorque_TorqueLimit : 24|8@1+ (1,-125) [-125|125] "%" Vector__XXX
 SG_ EngRqedSpeed_SpeedLimit : 8|16@1+ (0.125,0) [0|8031.875] "rpm" Vector__XXX
 SG_ OverrideCtrlModePriority : 4|2@1+ (1,0) [0|3] "" Vector__XXX
 SG_ EngRqedSpeedCtrlConditions : 2|2@1+ (1,0) [0|3] "" Vector__XXX
 SG_ EngOverrideCtrlMode : 0|2@1+ (1,0) [0|3] "" Vector__XXX

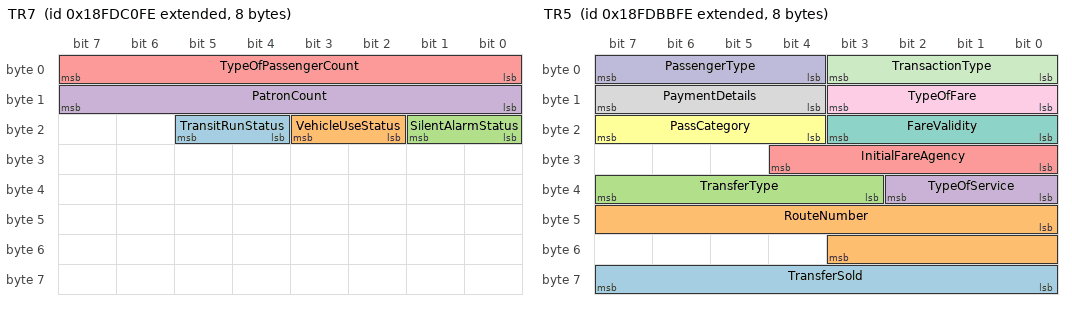
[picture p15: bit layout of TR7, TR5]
BO_ 2566766846 TR7: 8 Vector__XXX
 SG_ TransitRunStatus : 20|2@1+ (1,0) [0|3] "" Vector__XXX
 SG_ VehicleUseStatus : 18|2@1+ (1,0) [0|3] "" Vector__XXX
 SG_ SilentAlarmStatus : 16|2@1+ (1,0) [0|3] "" Vector__XXX
 SG_ PatronCount : 8|8@1+ (1,0) [0|250] "" Vector__XXX
 SG_ TypeOfPassengerCount : 0|8@1+ (1,0) [0|255] "" Vector__XXX

BO_ 2566765310 TR6: 8 Vector__XXX
 SG_ FareboxAlarmIdentifier : 8|7@1+ (1,0) [0|127] "" Vector__XXX
 SG_ FareboxEmergencyStatus : 0|2@1+ (1,0) [0|3] "" Vector__XXX

BO_ 2566765566 TR5: 8 Vector__XXX
 SG_ TransferSold : 56|8@1+ (1,0) [0|255] "" Vector__XXX
 SG_ RouteNumber : 40|12@1+ (1,0) [0|4095] "" Vector__XXX
 SG_ TransferType : 35|5@1+ (1,0) [0|31] "" Vector__XXX
 SG_ TypeOfService : 32|3@1+ (1,0) [0|7] "" Vector__XXX
 SG_ InitialFareAgency : 24|5@1+ (1,0) [0|31] "" Vector__XXX
 SG_ PassCategory : 20|4@1+ (1,0) [0|15] "" Vector__XXX
 SG_ FareValidity : 16|4@1+ (1,0) [0|15] "" Vector__XXX
 SG_ PaymentDetails : 12|4@1+ (1,0) [0|15] "" Vector__XXX
 SG_ TypeOfFare : 8|4@1+ (1,0) [0|15] "" Vector__XXX
 SG_ PassengerType : 4|4@1+ (1,0) [0|15] "" Vector__XXX
 SG_ TransactionType : 0|4@1+ (1,0) [0|15] "" Vector__XXX

BO_ 2566765822 TR4: 15 Vector__XXX
 SG_ DriversFareboxSecurityCode : 104|16@1+ (1,0) [0|65535] "counts" Vector__XXX
 SG_ AssignedBlock : 88|16@1+ (1,0) [0|65535] "counts" Vector__XXX
 SG_ AssignedRun : 72|16@1+ (1,0) [0|65535] "counts" Vector__XXX
 SG_ AssignedRoute : 56|16@1+ (1,0) [0|65535] "counts" Vector__XXX
 SG_ PatternNumber : 40|16@1+ (1,0) [0|65535] "counts" Vector__XXX
 SG_ TripNumber : 24|16@1+ (1,0) [0|65535] "counts" Vector__XXX
 SG_ FarePresets : 16|8@1+ (1,0) [0|255] "" Vector__XXX
 SG_ TripDirection : 8|4@1+ (1,0) [0|15] "" Vector__XXX
 SG_ TripStatus : 2|3@1+ (1,0) [0|7] "" Vector__XXX
 SG_ FareboxServiceStatus : 0|2@1+ (1,0) [0|3] "" Vector__XXX

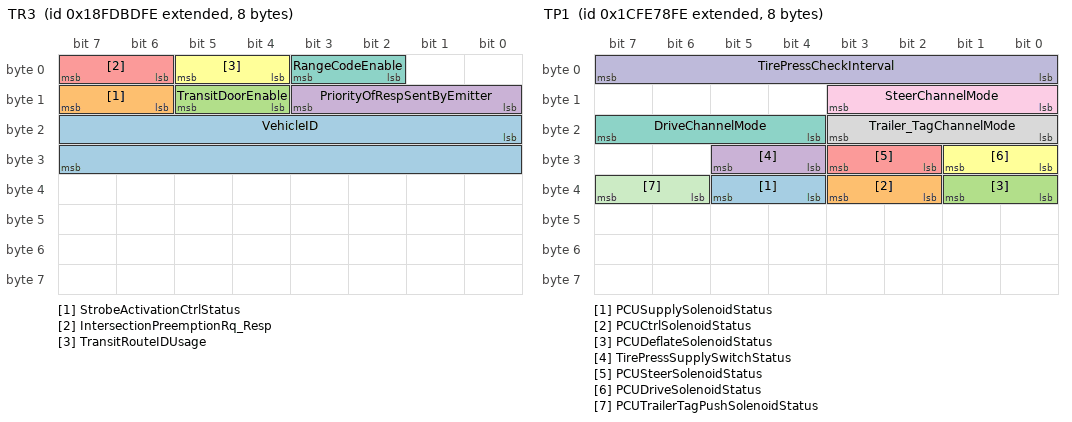
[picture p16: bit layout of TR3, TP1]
BO_ 2566766078 TR3: 8 Vector__XXX
 SG_ VehicleID : 16|16@1+ (1,0) [0|65535] "counts" Vector__XXX
 SG_ StrobeActivationCtrlStatus : 14|2@1+ (1,0) [0|3] "" Vector__XXX
 SG_ TransitDoorEnable : 12|2@1+ (1,0) [0|3] "" Vector__XXX
 SG_ PriorityOfRespSentByEmitter : 8|4@1+ (1,0) [0|15] "" Vector__XXX
 SG_ IntersectionPreemptionRq_Resp : 6|2@1+ (1,0) [0|3] "" Vector__XXX
 SG_ TransitRouteIDUsage : 4|2@1+ (1,0) [0|3] "" Vector__XXX
 SG_ RangeCodeEnable : 2|2@1+ (1,0) [0|3] "" Vector__XXX

BO_ 2566766590 TR2: 8 Vector__XXX
 SG_ NmbrOfBytsInMlpstIdentification : 0|8@1+ (1,0) [0|250] "" Vector__XXX

BO_ 2566766334 TR1: 8 Vector__XXX
 SG_ Agency : 0|8@1+ (1,0) [0|255] "" Vector__XXX
 SG_ NmbrOfBytsInTrnstAssgndBlckIdntt : 24|8@1+ (1,0) [0|250] "" Vector__XXX
 SG_ NmbrOfBytsInTrnstAssgndRnIdntty : 16|8@1+ (1,0) [0|250] "" Vector__XXX
 SG_ NmbrOfBytsInTrnstAssgndRtIdntty : 8|8@1+ (1,0) [0|250] "" Vector__XXX

BO_ 2561605374 TPRS: 8 Vector__XXX
 SG_ ReferenceTirePressSetting : 8|8@1+ (8,0) [0|2000] "kPa" Vector__XXX
 SG_ TireLocation : 0|8@1+ (1,0) [0|255] "" Vector__XXX

BO_ 2566765054 TPRI: 8 Vector__XXX
 SG_ ReferenceTirePress : 8|8@1+ (8,0) [0|2000] "kPa" Vector__XXX
 SG_ TireLocation : 0|8@1+ (1,0) [0|255] "" Vector__XXX

BO_ 2633923326 TP3: 8 Vector__XXX
 SG_ SteerChannelTirePress : 32|16@1+ (0.5,0) [0|32127.5] "kPa" Vector__XXX
 SG_ DriveChannelTirePress : 16|16@1+ (0.5,0) [0|32127.5] "kPa" Vector__XXX
 SG_ TrailerTagPushChannelTirePress : 0|16@1+ (0.5,0) [0|32127.5] "kPa" Vector__XXX

BO_ 2633923070 TP2: 8 Vector__XXX
 SG_ SteerChannelTirePressTarget : 32|16@1+ (0.5,0) [0|32127.5] "kPa" Vector__XXX
 SG_ DriveChannelTirePressTarget : 16|16@1+ (0.5,0) [0|32127.5] "kPa" Vector__XXX
 SG_ TrlrTgPshChannelTirePressTarget : 0|16@1+ (0.5,0) [0|32127.5] "kPa" Vector__XXX

BO_ 2633922814 TP1: 8 Vector__XXX
 SG_ PCUSupplySolenoidStatus : 36|2@1+ (1,0) [0|3] "" Vector__XXX
 SG_ PCUCtrlSolenoidStatus : 34|2@1+ (1,0) [0|3] "" Vector__XXX
 SG_ PCUDeflateSolenoidStatus : 32|2@1+ (1,0) [0|3] "" Vector__XXX
 SG_ TirePressSupplySwitchStatus : 28|2@1+ (1,0) [0|3] "" Vector__XXX
 SG_ PCUSteerSolenoidStatus : 26|2@1+ (1,0) [0|3] "" Vector__XXX
 SG_ PCUDriveSolenoidStatus : 24|2@1+ (1,0) [0|3] "" Vector__XXX
 SG_ DriveChannelMode : 20|4@1+ (1,0) [0|15] "" Vector__XXX
 SG_ Trailer_TagChannelMode : 16|4@1+ (1,0) [0|15] "" Vector__XXX
 SG_ SteerChannelMode : 8|4@1+ (1,0) [0|15] "" Vector__XXX
 SG_ TirePressCheckInterval : 0|8@1+ (1,0) [0|250] "mins" Vector__XXX
 SG_ PCUTrailerTagPushSolenoidStatus : 38|2@1+ (1,0) [0|3] "" Vector__XXX

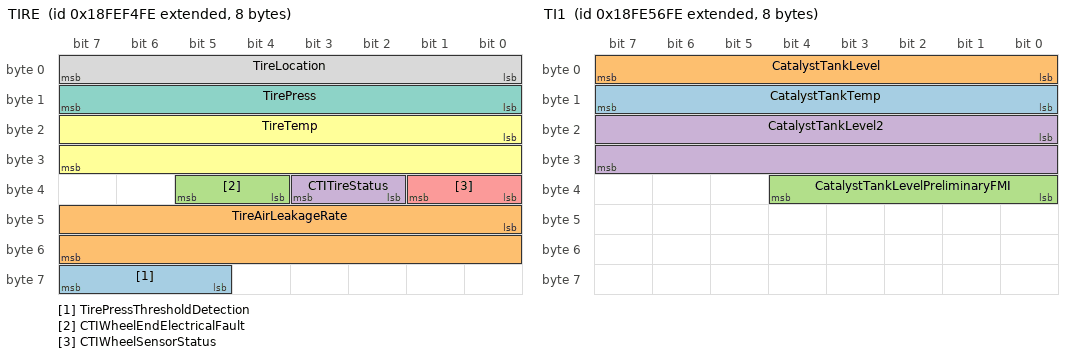
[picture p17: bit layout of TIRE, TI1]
BO_ 2566845694 TIRE: 8 Vector__XXX
 SG_ TirePressThresholdDetection : 61|3@1+ (1,0) [0|7] "" Vector__XXX
 SG_ TireAirLeakageRate : 40|16@1+ (0.1,0) [0|6425.5] "Pa/s" Vector__XXX
 SG_ CTIWheelEndElectricalFault : 36|2@1+ (1,0) [0|3] "" Vector__XXX
 SG_ CTITireStatus : 34|2@1+ (1,0) [0|3] "" Vector__XXX
 SG_ CTIWheelSensorStatus : 32|2@1+ (1,0) [0|3] "" Vector__XXX
 SG_ TireTemp : 16|16@1+ (0.03125,-273) [-273|1735] "deg" Vector__XXX
 SG_ TirePress : 8|8@1+ (4,0) [0|1000] "kPa" Vector__XXX
 SG_ TireLocation : 0|8@1+ (1,0) [0|255] "" Vector__XXX

BO_ 2566805246 TI1: 8 Vector__XXX
 SG_ CatalystTankTemp : 8|8@1+ (1,-40) [-40|210] "deg" Vector__XXX
 SG_ CatalystTankLevel : 0|8@1+ (0.4,0) [0|100] "%" Vector__XXX
 SG_ CatalystTankLevelPreliminaryFMI : 32|5@1+ (1,0) [0|31] "" Vector__XXX
 SG_ CatalystTankLevel2 : 16|16@1+ (0.1,0) [0|6425.5] "mm" Vector__XXX

BO_ 2633939966 TFI: 16 Vector__XXX
 SG_ TripFanOnTimeDueToAManualSwitch : 64|32@1+ (0.05,0) [0|210554060.75] "hr" Vector__XXX
 SG_ TripFanOnTime : 0|32@1+ (0.05,0) [0|210554060.75] "hr" Vector__XXX
 SG_ TripFanOnTimeDueToA_CSystem : 96|32@1+ (0.05,0) [0|210554060.75] "hr" Vector__XXX
 SG_ TripFanOnTimeDueToEngSystem : 32|32@1+ (0.05,0) [0|210554060.75] "hr" Vector__XXX

BO_ 2633939710 TDI: 12 Vector__XXX
 SG_ TripDistanceInTopGear : 64|32@1+ (0.125,0) [0|526385151.9] "km" Vector__XXX
 SG_ TripGearDownDistance : 32|32@1+ (0.125,0) [0|526385151.9] "km" Vector__XXX
 SG_ TripDistanceOnVSL : 0|32@1+ (0.125,0) [0|526385151.9] "km" Vector__XXX

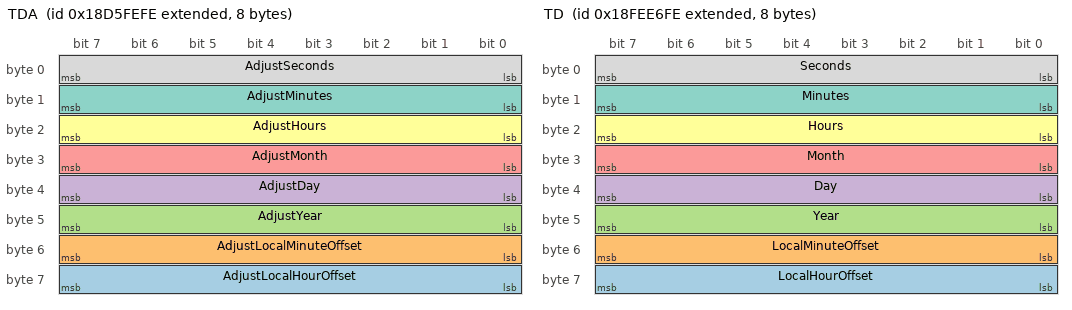
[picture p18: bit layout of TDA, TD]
BO_ 2564161278 TDA: 8 Vector__XXX
 SG_ AdjustLocalHourOffset : 56|8@1+ (1,-125) [-125|125] "hr" Vector__XXX
 SG_ AdjustLocalMinuteOffset : 48|8@1+ (1,-125) [-125|125] "mins" Vector__XXX
 SG_ AdjustYear : 40|8@1+ (1,1985) [1985|2235] "years" Vector__XXX
 SG_ AdjustDay : 32|8@1+ (0.25,0) [0|62.5] "days" Vector__XXX
 SG_ AdjustMonth : 24|8@1+ (1,0) [0|250] "months" Vector__XXX
 SG_ AdjustHours : 16|8@1+ (1,0) [0|250] "hr" Vector__XXX
 SG_ AdjustMinutes : 8|8@1+ (1,0) [0|250] "mins" Vector__XXX
 SG_ AdjustSeconds : 0|8@1+ (0.25,0) [0|62.5] "s" Vector__XXX

BO_ 2566842110 TD: 8 Vector__XXX
 SG_ LocalHourOffset : 56|8@1+ (1,-125) [-125|125] "hr" Vector__XXX
 SG_ LocalMinuteOffset : 48|8@1+ (1,-125) [-125|125] "mins" Vector__XXX
 SG_ Year : 40|8@1+ (1,1985) [1985|2235] "years" Vector__XXX
 SG_ Day : 32|8@1+ (0.25,0) [0|62.5] "days" Vector__XXX
 SG_ Month : 24|8@1+ (1,0) [0|250] "months" Vector__XXX
 SG_ Hours : 16|8@1+ (1,0) [0|250] "hr" Vector__XXX
 SG_ Minutes : 8|8@1+ (1,0) [0|250] "mins" Vector__XXX
 SG_ Seconds : 0|8@1+ (0.25,0) [0|62.5] "s" Vector__XXX

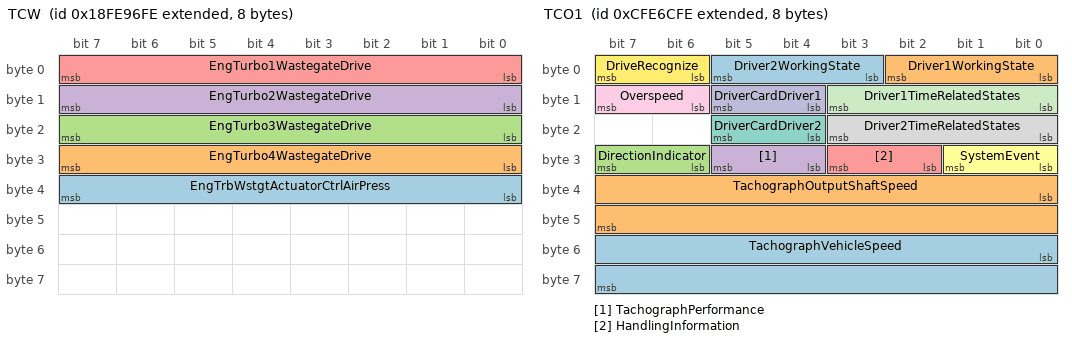
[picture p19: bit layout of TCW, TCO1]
BO_ 2566821630 TCW: 8 Vector__XXX
 SG_ EngTrbWstgtActuatorCtrlAirPress : 32|8@1+ (4,0) [0|1000] "kPa" Vector__XXX
 SG_ EngTurbo4WastegateDrive : 24|8@1+ (0.4,0) [0|100] "%" Vector__XXX
 SG_ EngTurbo3WastegateDrive : 16|8@1+ (0.4,0) [0|100] "%" Vector__XXX
 SG_ EngTurbo2WastegateDrive : 8|8@1+ (0.4,0) [0|100] "%" Vector__XXX
 SG_ EngTurbo1WastegateDrive : 0|8@1+ (0.4,0) [0|100] "%" Vector__XXX

BO_ 2365484286 TCO1: 8 Vector__XXX
 SG_ TachographVehicleSpeed : 48|16@1+ (0.00390625,0) [0|250.996] "km/h" Vector__XXX
 SG_ TachographOutputShaftSpeed : 32|16@1+ (0.125,0) [0|8031.875] "rpm" Vector__XXX
 SG_ DirectionIndicator : 30|2@1+ (1,0) [0|3] "" Vector__XXX
 SG_ TachographPerformance : 28|2@1+ (1,0) [0|3] "" Vector__XXX
 SG_ HandlingInformation : 26|2@1+ (1,0) [0|3] "" Vector__XXX
 SG_ SystemEvent : 24|2@1+ (1,0) [0|3] "" Vector__XXX
 SG_ DriverCardDriver2 : 20|2@1+ (1,0) [0|3] "" Vector__XXX
 SG_ Driver2TimeRelatedStates : 16|4@1+ (1,0) [0|15] "" Vector__XXX
 SG_ Overspeed : 14|2@1+ (1,0) [0|3] "" Vector__XXX
 SG_ DriverCardDriver1 : 12|2@1+ (1,0) [0|3] "" Vector__XXX
 SG_ Driver1TimeRelatedStates : 8|4@1+ (1,0) [0|15] "" Vector__XXX
 SG_ DriveRecognize : 6|2@1+ (1,0) [0|3] "" Vector__XXX
 SG_ Driver2WorkingState : 3|3@1+ (1,0) [0|7] "" Vector__XXX
 SG_ Driver1WorkingState : 0|3@1+ (1,0) [0|7] "" Vector__XXX

BO_ 2566771710 TCI6: 8 Vector__XXX
 SG_ EngTurbo4CompressorOutletTemp : 48|16@1+ (0.03125,-273) [-273|1735] "deg" Vector__XXX
 SG_ EngTurbo3CompressorOutletTemp : 32|16@1+ (0.03125,-273) [-273|1735] "deg" Vector__XXX
 SG_ EngTurbo2CompressorOutletTemp : 16|16@1+ (0.03125,-273) [-273|1735] "deg" Vector__XXX
 SG_ EngTurbo1CompressorOutletTemp : 0|16@1+ (0.03125,-273) [-273|1735] "deg" Vector__XXX

BO_ 2566821886 TCI5: 8 Vector__XXX
 SG_ EngTurbo4TurbineOutletTemp : 48|16@1+ (0.03125,-273) [-273|1735] "deg" Vector__XXX
 SG_ EngTurbo3TurbineOutletTemp : 32|16@1+ (0.03125,-273) [-273|1735] "deg" Vector__XXX
 SG_ EngTurbo2TurbineOutletTemp : 16|16@1+ (0.03125,-273) [-273|1735] "deg" Vector__XXX
 SG_ EngTurbo1TurbineOutletTemp : 0|16@1+ (0.03125,-273) [-273|1735] "deg" Vector__XXX

BO_ 2566822142 TCI4: 8 Vector__XXX
 SG_ EngTurbo4TurbineInletTemp : 48|16@1+ (0.03125,-273) [-273|1735] "deg" Vector__XXX
 SG_ EngTurbo3TurbineInletTemp : 32|16@1+ (0.03125,-273) [-273|1735] "deg" Vector__XXX
 SG_ EngTurbo2TurbineInletTemp : 16|16@1+ (0.03125,-273) [-273|1735] "deg" Vector__XXX
 SG_ EngTurbo1TurbineInletTemp : 0|16@1+ (0.03125,-273) [-273|1735] "deg" Vector__XXX

BO_ 2566822398 TCI3: 8 Vector__XXX
 SG_ EngTurbo4CompressorInletPress : 48|16@1+ (0.0078125,-250) [-250|251.99] "kPa" Vector__XXX
 SG_ EngTurbo3CompressorInletPress : 32|16@1+ (0.0078125,-250) [-250|251.99] "kPa" Vector__XXX
 SG_ EngTurbo2CompressorInletPress : 16|16@1+ (0.0078125,-250) [-250|251.99] "kPa" Vector__XXX
 SG_ EngTurbo1CompressorInletPress : 0|16@1+ (0.0078125,-250) [-250|251.99] "kPa" Vector__XXX

BO_ 2566822654 TCI2: 8 Vector__XXX
 SG_ EngTurbo4CompressorInletTemp : 48|16@1+ (0.03125,-273) [-273|1735] "deg" Vector__XXX
 SG_ EngTurbo3CompressorInletTemp : 32|16@1+ (0.03125,-273) [-273|1735] "deg" Vector__XXX
 SG_ EngTurbo2CompressorInletTemp : 16|16@1+ (0.03125,-273) [-273|1735] "deg" Vector__XXX
 SG_ EngTurbo1CompressorInletTemp : 0|16@1+ (0.03125,-273) [-273|1735] "deg" Vector__XXX

BO_ 2633931774 TCI1: 8 Vector__XXX
 SG_ EngTurbo4Speed : 40|16@1+ (4,0) [0|257020] "rpm" Vector__XXX
 SG_ EngTurbo3Speed : 24|16@1+ (4,0) [0|257020] "rpm" Vector__XXX
 SG_ EngTurbo2Speed : 8|16@1+ (4,0) [0|257020] "rpm" Vector__XXX
 SG_ EngTurboLubeOilPress2 : 0|8@1+ (4,0) [0|1000] "kPa" Vector__XXX

BO_ 2566802430 TCFG2: 8 Vector__XXX
 SG_ TransTorqueLimit : 0|16@1+ (1,0) [0|64255] "Nm" Vector__XXX

BO_ 2566841086 TCFG: 8 Vector__XXX
 SG_ TransGearRatio : 16|16@1+ (0.001,0) [0|64.255] "" Vector__XXX
 SG_ NumberOfForwardGearRatios : 8|8@1+ (1,0) [0|250] "" Vector__XXX
 SG_ NumberOfReverseGearRatios : 0|8@1+ (1,0) [0|250] "" Vector__XXX

CM_ BO_ 2566757374 "Catalyst Reagent Information";
CM_ SG_ 2566757374 CatalystReagentType "This parameter indicates what reagent is in the tank.";
CM_ SG_ 2566757374 CtlystRgntPrprtesPreliminaryFMI "Used to identify the applicable J1939-73 FMI that applies to the most significant failure of the catalyst reagent properties sensor.";
CM_ SG_ 2566757374 CtlystRagentTemp2PreliminaryFMI "Used to identify the applicable J1939-73 FMI that applies to the most significant failure of the catalyst temperature sensor.";
CM_ SG_ 2566757374 CatalystReagentConductivity "A measure of the conductivity of the reagent or fluid at the sensor.";
CM_ SG_ 2566757374 CatalystReagentConcentration "A measure of the concentration of urea in water.";
CM_ BO_ 2566756862 "After Treatment Historical Information #2";
CM_ SG_ 2566756862 AftrTrtmnt2TtlNmbrOfActvRgnrtns "Total number of active regenerations by after treatment device 2 over the lifetime of the device.";
CM_ SG_ 2566756862 AftrTreatment2TotalDisabledTime "Total amount of time that after treatment 2 regeneration has been manually disabled.";
CM_ SG_ 2566756862 AftrTrtmnt2TtalRegenerationTime "Total amount of time that after treatment device 2 has been regenerating over the lifetime of the device.";
CM_ SG_ 2566756862 AfterTreatment2TotalFuelUsed "Total amount of fuel used by after treatment device 2 over the lifetime of the device.";
CM_ BO_ 2566758654 "After Treatment Fuel Control #2";
CM_ SG_ 2566758654 Aftertreatment2Ignt "Indicates whether aftertreatment #2 ignition circuit is energized by the ECM.";
CM_ SG_ 2566758654 Aftertreatment2FuelPressCtrl "Position that the controller is commanding the aftertreatment #2 fuel pressure control to maintain.";
CM_ SG_ 2566758654 Aftertreatment2FuelPress "Pressure of the fuel for Aftertreatment #2.";
CM_ BO_ 2566758910 "After Treatment Fuel Control #1";
CM_ SG_ 2566758910 Aftertreatment1Ignt "Indicates whether aftertreatment #1 ignition circuit is energized by the ECM.";
CM_ SG_ 2566758910 Aftertreatment1FuelPressCtrl "Position that the controller is commanding the aftertreatment #1 fuel pressure control to maintain.";
CM_ SG_ 2566758910 Aftertreatment1FuelPress "Pressure of the fuel for Aftertreatment #1.";
CM_ BO_ 2566758142 "After Treatment Air Control #2";
CM_ SG_ 2566758142 Aftrtrtment2AirPressActuatorPos "Position of the #2 aftertreatment air pressure actuator as measured by a position feedback sensor.";
CM_ SG_ 2566758142 Aftertreatment2AirPressCtrl "Position that the controller is commanding the aftertreatment #2 air pressure control to maintain.";
CM_ BO_ 2566758398 "After Treatment Air Control #1";
CM_ SG_ 2566758398 Aftrtrtment1AirPressActuatorPos "Position of the #1 aftertreatment air pressure actuator as measured by a position feedback sensor.";
CM_ SG_ 2566758398 Aftertreatment1AirPressCtrl "Position that the controller is commanding the aftertreatment #1 air pressure control to maintain.";
CM_ BO_ 2566756606 "After Treatment Historical Information #1";
CM_ SG_ 2566756606 AftrTrtmnt1TtlNmbrOfActvRgnrtns "Total number of active regenerations by after treatment device 1 over the lifetime of the device.";
CM_ SG_ 2566756606 AftrTrtmnt1TtalRegenerationTime "Total amount of time that after treatment device 1 has been regenerating over the lifetime of the device.";
CM_ SG_ 2566756606 AftrTreatment1TotalDisabledTime "Total amount of time that after treatment 1 regeneration has been manually disabled.";
CM_ SG_ 2566756606 AfterTreatment1TotalFuelUsed "Total amount of fuel used by after treatment device 1 over the lifetime of the device.";
CM_ BO_ 2364546302 "Requested Generator Average Basic AC Quantities";
CM_ SG_ 2364546302 RqdGnrtrAvrgLneLineACRMSVoltage "The requested average AC RMS voltage to be delivered by the generator.";
CM_ BO_ 2431654654 "Engine Throttle / Fuel Actuator Control Command";
CM_ BO_ 2364545534 "Engine Knock Level #3";
CM_ SG_ 2364545534 EngCyl24KnockLevel "Used to indicate the level of knock for engine cylinder 24.";
CM_ SG_ 2364545534 EngCyl23KnockLevel "Used to indicate the level of knock for engine cylinder 23.";
CM_ SG_ 2364545534 EngCyl22KnockLevel "Used to indicate the level of knock for engine cylinder 22.";
CM_ SG_ 2364545534 EngCyl21KnockLevel "Used to indicate the level of knock for engine cylinder 21.";
CM_ SG_ 2364545534 EngCyl20KnockLevel "Used to indicate the level of knock for engine cylinder 20.";
CM_ SG_ 2364545534 EngCyl19KnockLevel "Used to indicate the level of knock for engine cylinder 19.";
CM_ SG_ 2364545534 EngCyl18KnockLevel "Used to indicate the level of knock for engine cylinder 18.";
CM_ SG_ 2364545534 EngCyl17KnockLevel "Used to indicate the level of knock for engine cylinder 17.";
CM_ BO_ 2364545278 "Engine Knock Level #2";
CM_ SG_ 2364545278 EngCyl15KnockLevel "Used to indicate the level of knock for engine cylinder 15.";
CM_ SG_ 2364545278 EngCyl14KnockLevel "Used to indicate the level of knock for engine cylinder 14.";
CM_ SG_ 2364545278 EngCyl13KnockLevel "Used to indicate the level of knock for engine cylinder 13.";
CM_ SG_ 2364545278 EngCyl12KnockLevel "Used to indicate the level of knock for engine cylinder 12.";
CM_ SG_ 2364545278 EngCyl11KnockLevel "Used to indicate the level of knock for engine cylinder 11.";
CM_ SG_ 2364545278 EngCyl10KnockLevel "Used to indicate the level of knock for engine cylinder 10.";
CM_ SG_ 2364545278 EngCyl9KnockLevel "Used to indicate the level of knock for engine cylinder 9.";
CM_ SG_ 2364545278 EngCyl16KnockLevel "Used to indicate the level of knock for engine cylinder 16.";
CM_ BO_ 2364545022 "Engine Knock Level #1";
CM_ SG_ 2364545022 EngCyl8KnockLevel "Used to indicate the level of knock for engine cylinder 8.";
CM_ SG_ 2364545022 EngCyl7KnockLevel "Used to indicate the level of knock for engine cylinder 7.";
CM_ SG_ 2364545022 EngCyl6KnockLevel "Used to indicate the level of knock for engine cylinder 6.";
CM_ SG_ 2364545022 EngCyl5KnockLevel "Used to indicate the level of knock for engine cylinder 5.";
CM_ SG_ 2364545022 EngCyl4KnockLevel "Used to indicate the level of knock for engine cylinder 4.";
CM_ SG_ 2364545022 EngCyl3KnockLevel "Used to indicate the level of knock for engine cylinder 3.";
CM_ SG_ 2364545022 EngCyl2KnockLevel "Used to indicate the level of knock for engine cylinder 2.";
CM_ SG_ 2364545022 EngCyl1KnockLevel "Used to indicate the level of knock for engine cylinder 1.";
CM_ BO_ 2364544766 "Cylinder Combustion Status";
CM_ BO_ 2364544510 "Requested Generator Total AC Reactive Power";
CM_ SG_ 2364544510 RqGenOverallPowerFactorLagging "The requested lead/lag status for the generator average AC power factor";
CM_ SG_ 2364544510 RqGeneratorOverallPowerFactor "The requested average power factor of the generator.";
CM_ SG_ 2364544510 RqGeneratorTotalACReactivePower "The total reactive power requested to be delivered by the generator";
CM_ BO_ 2364544254 "Blade Information";
CM_ SG_ 2364544254 BladeRotationAngleFigureOfMerit "Figure of merit for blade rotation measurement.";
CM_ SG_ 2364544254 RelBladeHeightFigureOfMerit "Figure of merit for blade height measurement.";
CM_ SG_ 2364544254 RelBladeMeasurementLatency "The estimated measurement latency of the measurement.";
CM_ SG_ 2364544254 BladeRotationAngle "The blade rotation angle measurement around the yaw (z-axis).";
CM_ SG_ 2364544254 RelativeBladeHeight "The measured vertical distance from a fixed location on the machine blade to a ground-based reference.";
CM_ BO_ 2349006590 "ISO 11992: Towing vehicle message, electronic brake system #1/1";
CM_ SG_ 2349006590 RetarderDemandValue "The demanded value of the retarder on the towed vehicle(s) as a percentage of the absolute peak torque of retarder.";
CM_ SG_ 2349006590 ParkBrakeDemandValue "The requested brake pressure value of the parking brake as a percentage of maximum.";
CM_ SG_ 2349006590 ServiceBrakeDemandValue "The requested brake pressure value of the service brake demanded by the driver.";
CM_ SG_ 2349006590 VehicleType "Information to identify a dolly axle within the road train.";
CM_ SG_ 2349006590 BrakeLightSwitch "Signal which indicates that the brake pedal is being pressed.";
CM_ SG_ 2349006590 ASREngineControlActive "Signal which indicates that ASR engine control is active/passive.";
CM_ SG_ 2349006590 ASRBreakControlActive "Signal which indicates that ASR brake control is active/passive.";
CM_ SG_ 2349006590 VehicleRetarderCtrlActive "This signal indicates the active/passive state in all cases when the installed retarder is applied by the driver’s demand or by other systems (brakes).";
CM_ SG_ 2349006590 VehicleABSActive "Signal indicating the ABS is active/passive.";
CM_ BO_ 2566834686 "ISO 11992: Towing vehicle message, electronic brake system #1/2";
CM_ SG_ 2566834686 RoadCurvature "Estimated value of the current road curvature for use by the adaptive cruise control system.";
CM_ SG_ 2566834686 PneumaticControlLine "Signal which indicates that the towing vehicle has a pneumatic control line for the towed vehicle service braking system";
CM_ SG_ 2566834686 ABSOffroadRequest "Request to activate the ABS off-road function. The switch signal is independent of an actual ABS control situation.";
CM_ SG_ 2566834686 TwoElCircuitsBrakeDemand "Signal which indicates that the service brake demand value sent by the towing vehicle can be generated by one or two independent electrical braking circuit(s).";
CM_ SG_ 2566834686 VehicleRetarderCtrlActive "This signal indicates the active/passive state in all cases when the installed retarder is applied by the driver’s demand or by other systems (brakes).";
CM_ BO_ 2550398718 "ISO 11992: Towed vehicle message, electronic brake system #2/1";
CM_ SG_ 2550398718 WheelSpeedDiffMainAxle "Difference between the wheel speed at the right side and and the left side of the main axle.";
CM_ SG_ 2550398718 ActualRetarderPercTorque "Actual torque of the retarder as negative percentage of maximum.";
CM_ SG_ 2550398718 Wheel_BasedVehicleSpeed "Actual speed of the vehicle (positive value for forward and backward speed) calculated as the average of the wheel speeds of one axle influenced by slip and filtered by a frequency range of 5 Hz to 20 Hz.";
CM_ SG_ 2550398718 SupplyLineBrakingRequest "Signal indicating the trailer is requesting to be braked by the commercial vehicle by means of bleeding the pneumatic supply line.";
CM_ SG_ 2550398718 VDCActive "Signal which indicates that Vehicle Dynamic Control (VDC) is active/passive.";
CM_ SG_ 2550398718 AutomTowedVehBreakActive "Signal indicating the automatic towed vehicle braking is active/passive.";
CM_ SG_ 2550398718 VehicleServiceBrakeActive "Signal indicating the service brake of the towed vehicle is active/passive, by observing the brake pressure.";
CM_ SG_ 2550398718 VehicleRetarderCtrlActive "This signal indicates the active/passive state in all cases when the installed retarder is applied by the driver’s demand or by other systems (brakes).";
CM_ SG_ 2550398718 VehicleABSActive "Signal indicating the ABS is active/passive.";
CM_ BO_ 2566833406 "ISO 11992: Towed vehicle message, electronic brake system #2/2";
CM_ SG_ 2566833406 ReferenceRetarderTorque "This parameter is the 100% reference value for all defined indicated retarder torque parameters.";
CM_ SG_ 2566833406 AxleLoadSum "Sum of the static vertical loads of the vehicle axles.";
CM_ SG_ 2566833406 SupplyLineBrakingRequest "Signal indicating the trailer is requesting to be braked by the commercial vehicle by means of bleeding the pneumatic supply line.";
CM_ SG_ 2566833406 LoadingRampApproachAssist "The parameter indicates whether the loading ramp approach assistance is activated.";
CM_ SG_ 2566833406 SpringBrakeEngaged "Signal indicating the vehicle spring brake is engaged.";
CM_ SG_ 2566833406 ElectrLoadPropFunc "Signal indicating the vehicle is equipped with an electrical load proportional function.";
CM_ SG_ 2566833406 SpringBrakeInstalled "Signal indicating the vehicle has one or more axle(s) fitted with spring brakes.";
CM_ SG_ 2566833406 VehicleType "Information to identify a dolly axle within the road train.";
CM_ SG_ 2566833406 ElecSupplyOfNonBrakingSys "Signal which indicates the status of the supply of non-braking systems.";
CM_ SG_ 2566833406 AmberWarningSignalReq "Request from the towed vehicle to the commercial vehicle to activate the amber warning signal on the commercial vehicle.";
CM_ SG_ 2566833406 RedWarningSignalRequest "Request from the towed vehicle to the commercial vehicle to activate the red warning signal on the commercial vehicle, which indicates certain specified failures within the braking equipment of the towed vehicles.";
CM_ SG_ 2566833406 VehicleElectrSupplySuff "Signal indicating the actual supply voltage is sufficient/insufficient for proper brake function (including over voltage).";
CM_ SG_ 2566833406 AutomTowedVehBreakActive "Signal indicating the automatic towed vehicle braking is active/passive.";
CM_ SG_ 2566833406 VehicleServiceBrakeActive "Signal indicating the service brake of the towed vehicle is active/passive, by observing the brake pressure.";
CM_ SG_ 2566833406 VehicleRetarderCtrlActive "This signal indicates the active/passive state in all cases when the installed retarder is applied by the driver’s demand or by other systems (brakes).";
CM_ SG_ 2566833406 VehicleABSActive "Signal indicating the ABS is active/passive.";
CM_ BO_ 2365507326 "ISO 11992: Towed vehicle message, electronic brake system #2/3";
CM_ SG_ 2365507326 PneumaticSupplyPressure "Actual supply pressure of the reservoir of the braking system.";
CM_ SG_ 2365507326 BrakeTemperature "Actual brake temperature.";
CM_ SG_ 2365507326 BrakeLining "Actual relative value of brake lining of a specific brake.";
CM_ SG_ 2365507326 TyrePressure "Actual tyre pressure without corrections.";
CM_ SG_ 2365507326 TyreWheelIdentTemp2 "Second part of identification number of the tyre or wheel (the number of axles).";
CM_ SG_ 2365507326 TyreWheelIdentTemp1 "First part of identification number of the tyre or wheel (position on each axle).";
CM_ SG_ 2365507326 TyreWheelIdentPressure2 "Second part of identification number of the tyre or wheel (the number of axles).";
CM_ SG_ 2365507326 TyreWheelIdentPressure1 "First part of identification number of the tyre or wheel (position on each axle).";
CM_ SG_ 2365507326 TyreWheelIdentLining2 "Second part of identification number of the tyre or wheel (the number of axles).";
CM_ SG_ 2365507326 TyreWheelIdentLining1 "First part of identification number of the tyre or wheel (position on each axle).";
CM_ SG_ 2365507326 VehiclePneumSupplySuff "Signal indicating the actual supply pressure of the reservoir of the braking system is insufficient or sufficient.";
CM_ SG_ 2365507326 BrakeTemperatureStatus "Signal which indicates that the brake temperature is higher than a specific level.";
CM_ SG_ 2365507326 BrakeLiningSufficient "Signal which indicates that the brake lining is sufficient/insufficient.";
CM_ SG_ 2365507326 TyrePressureSufficient "Signal which indicates that the tyre pressure is insufficient";
CM_ BO_ 2565013246 "ISO 11992: Towing vehicle message, general purpose message #1/1

GPM 11 replaces GFM 11 in ISO 11992:1998 part 3";
CM_ SG_ 2565013246 ODDRequest "Command signal to switch on or off the obstacle detection device (ODD).";
CM_ SG_ 2565013246 AntiTheftDeviceReq "Command signal to activate the anti-theft device.";
CM_ SG_ 2565013246 VehicleType "Information to identify a dolly axle within the road train.";
CM_ BO_ 2566807038 "ISO 11992: Towing vehicle message, general purpose message #1/2";
CM_ SG_ 2566807038 MaxVehicleSpeedLimit "Maximum vehicle velocity allowed.";
CM_ SG_ 2566807038 EngineSpeedUpperLimit "The engine speed which cannot be exceeded.";
CM_ SG_ 2566807038 EngineSpeedLowerLimit "The minimum engine speed which the engine is allowed to reach.";
CM_ BO_ 2365480958 "ISO 11992: Towing vehicle message, general purpose message #1/3";
CM_ SG_ 2365480958 EngineTorqueMode "State signal which indicates which engine torque mode is currently generating, limiting, or controlling the torque";
CM_ SG_ 2365480958 PercentLoadAtCurrentSpeed "The ratio of actual engine percent torque to maximum indicated torque available at the current engine speed, clipped to zero torque during engine braking.";
CM_ SG_ 2365480958 EngineSpeed "Actual engine speed which is calculated over a minimum crankshaft angle of 720 degrees divided by
the number of cylinders.";
CM_ SG_ 2365480958 ActualEngine_PercTorque "The calculated output torque of the engine.";
CM_ SG_ 2365480958 DriversDemandEngine_PercTorque "The torque output of the engine requested by the driver.";
CM_ SG_ 2365480958 EngineRunning "Signal which indicates whether the engine is running.";
CM_ SG_ 2365480958 EngineControlAllowed "Switch signal which indicates that engine control is allowed.";
CM_ BO_ 2566808062 "ISO 11992: Towing vehicle message, general purpose message #1/4";
CM_ SG_ 2566808062 ClutchIndptdPTOFeedback "Signal which indicates the current state of the clutch independent power take off.";
CM_ SG_ 2566808062 AccelPedalPosition "The ratio of actual accelerator pedal position to maximum pedal position.";
CM_ SG_ 2566808062 AccelPedalLowIdleSwitch "Switch signal which indicates whether the accelerator pedal low idle switch is opened or closed.";
CM_ SG_ 2566808062 StarterActive "Signal which indicates whether the starter is in use.";
CM_ SG_ 2566808062 TorqueConvOilTemp "Temperature of the torque converter lubricant.";
CM_ SG_ 2566808062 TorqueConvtOilTempWarning "Signal which indicates that the torque converter oil temperature has reached its warning level.";
CM_ SG_ 2566808062 PTOControlAllowed "Switch signal which indicates that PTO control is allowed.";
CM_ SG_ 2566808062 SecEngineMtdPTOFeedback "Signal which indicates the current state of the second engine mounted power take off.";
CM_ SG_ 2566808062 FirstEngineMtdPTOFeedback "Signal which indicates the current state of the first engine mounted power take off.";
CM_ SG_ 2566808062 SecClutchDptdPTOFeedback "Signal which indicates the current state of the second clutch dependent power take off.";
CM_ SG_ 2566808062 FirstClutchDpdtPTOFeedback "Signal which indicates the current state of the first clutch dependent power take off.";
CM_ SG_ 2566808062 CurrentGear "The gear currently engaged in the transmission or the last gear engaged while the transmission is in process of shifting to the new or selected gear.";
CM_ SG_ 2566808062 PercentClutchSlip "Parameter which represents the ratio of input shaft speed to current engine speed (in percent).";
CM_ BO_ 2566808574 "ISO 11992: Towing vehicle message, general purpose message #1/5";
CM_ SG_ 2566808574 ReferenceEngineTorque "The 100 % reference value for all defined indicated engine torque parameters.";
CM_ SG_ 2566808574 FuelLevelWarning "This signal indicates the decrease of the fuel level to a certain minimum.";
CM_ SG_ 2566808574 EngineOilPressureWarning "Signal which indicates that the engine oil pressure has reached its warning level.";
CM_ SG_ 2566808574 EngineCoolantTempWarning "Signal which indicates that the engine coolant temperature has reached its warning level.";
CM_ SG_ 2566808574 EngineOilPressure "Gauge pressure of the oil in the engine lubrication system as provided by the oil pump.";
CM_ SG_ 2566808574 EngineOilTemperature "Temperature of the engine lubricant.";
CM_ BO_ 2566809086 "ISO 11992: Towing vehicle message, general purpose message #1/6";
CM_ SG_ 2566809086 AmbientAirTemperature "Temperature of air surrounding vehicle.";
CM_ BO_ 2564947710 "ISO 11992: Towed vehicle message, general purpose message #2/1

GPM 21 replaces GFM 21 in ISO 11992:1998 part 3";
CM_ SG_ 2564947710 VehicleType "Information to identify a dolly axle within the road train.";
CM_ BO_ 2566834430 "ISO 11992: Towed vehicle message, general purpose message #2/2

GPM22 replaces GFM 24 in ISO 11992:1998 part 3";
CM_ SG_ 2566834430 BodyPressure "The actual pressure in a body on the towed vehicle.";
CM_ SG_ 2566834430 BodyFluidLevel "The actual fluid level in a body on the towed vehicle.";
CM_ SG_ 2566834430 ThermalBodyTemperature "The actual temperature in a thermal body on the towed vehicle.";
CM_ SG_ 2566834430 RearObstacleDistance "The actual distance between the back of the towed vehicle and any obstacle.";
CM_ SG_ 2566834430 AntiTheftDeviceStatus "Signal which indicates that the anti-theft device is switched on or off.";
CM_ SG_ 2566834430 ODDStatus "Signal which indicates that an obstacle detection device (ODD) is active/inactive.";
CM_ BO_ 2365481214 "ISO 11992: Towed vehicle message, general purpose message #2/3";
CM_ SG_ 2365481214 ReqEngineSpeedUpperLim "The requested engine speed which is not to be exceeded.";
CM_ SG_ 2365481214 ReqEngineSpeedLowerLim "The requested minimum engine speed which the engine is to allow.";
CM_ SG_ 2365481214 ReqEngineTorqueLimit "The requested engine torque that the engine is not allowed to exceed, indicated as a ratio of the reference engine torque.";
CM_ SG_ 2365481214 ReqEngineSpeedLimit "The requested vehicle speed which the vehicle is not allowed to exceed.";
CM_ SG_ 2365481214 ReqEngineSpeed "This is the engine speed which the engine is expected to operate at.";
CM_ BO_ 2566808318 "ISO 11992: Towed vehicle message, general purpose message #2/4";
CM_ SG_ 2566808318 SecEngineMtdPTOSwitch "Signal which indicates the state of the second engine mounted power take off switch.";
CM_ SG_ 2566808318 SecClutchDpdtPTOSwitch "Signal which indicates the state of the second clutch dependent power take off switch.";
CM_ SG_ 2566808318 FirstClutchDpdtPTOSwitch "Signal which indicates the state of the first clutch dependent power take off switch.";
CM_ SG_ 2566808318 OperatingPanelActive "Signal which indicates that the operating panel is active.";
CM_ SG_ 2566808318 RefusePackerStepSwitch "Signal which indicates the state of the refuse packer step switch.";
CM_ SG_ 2566808318 EngineStopSwitch "Signal which indicates the state of the engine stop switch.";
CM_ SG_ 2566808318 EngineStartSwitch "Signal which indicates the state of the engine start switch.";
CM_ SG_ 2566808318 StarterLockoutSwitch "Signal which indicates the state of the starter lockout switch.";
CM_ SG_ 2566808318 RqstedPercentClutchSlip "Command signal to influence the clutch.";
CM_ SG_ 2566808318 FirstEngineMtdPTOSwitch "Signal which indicates the state of the first engine mounted power take off switch.";
CM_ SG_ 2566808318 ClutchIndpdtPTOSwitch "Signal which indicates the state of the clutch independent power take off switch.";
CM_ BO_ 2566808830 "ISO 11992: Towed vehicle message, general purpose message #2/5";
CM_ SG_ 2566808830 TrailerLeftSideMarkerLight "This signal indicates the state of the trailer left-hand side marker light(s).";
CM_ SG_ 2566808830 TrailerLeftReversingLight "This signal indicates the state of the trailer left-hand reversing light(s).";
CM_ SG_ 2566808830 TrailerLeftRearWidIndLight "This signal indicates the state of the trailer left-hand rear width indicator light(s).";
CM_ SG_ 2566808830 TrailerLeftRearRegPltLight "This signal indicates the state of the trailer left-hand rear registration-plate light(s).";
CM_ SG_ 2566808830 TrailerLeftRearLight "This signal indicates the state of the trailer left-hand rear light(s).";
CM_ SG_ 2566808830 TrailerLeftRearFogLight "This signal indicates the state of the trailer left-hand rear fog light(s).";
CM_ SG_ 2566808830 TrailerLeftDirIndLight "This signal indicates the state of the trailer left-hand direction indicator light(s).";
CM_ SG_ 2566808830 TrailerLeftCrnMarkerLight "This signal indicates the state of the trailer left-hand corner marker light(s).";
CM_ SG_ 2566808830 TrailerInteriorLight "This signal indicates the state of the trailer interior light(s).";
CM_ SG_ 2566808830 TrailerWorkLamp "This signal indicates the state of the trailer work lamp(s).";
CM_ SG_ 2566808830 TrailerRotatingIdentLight "This signal indicates the state of the trailer rotating identification light(s).";
CM_ SG_ 2566808830 TrailerRightStopLight "This signal indicates the state of the trailer right-hand stop light(s).";
CM_ SG_ 2566808830 TrailerRightSideMrkLight "This signal indicates the state of the trailer right-hand side marker light(s).";
CM_ SG_ 2566808830 TrailerRightReversingLight "This signal indicates the state of the trailer right-hand reversing light(s).";
CM_ SG_ 2566808830 TrailRightRearWidIndLight "This signal indicates the state of the trailer right-hand rear width indicator light(s).";
CM_ SG_ 2566808830 TrailerRightRearRegPltLight "This signal indicates the state of the trailer right-hand rear registration-plate light(s).";
CM_ SG_ 2566808830 TrailerRightRearLight "This signal indicates the state of the trailer right-hand rear light(s).";
CM_ SG_ 2566808830 TrailerRightRearFogLight "This signal indicates the state of the trailer right-hand rear fog light(s).";
CM_ SG_ 2566808830 TrailerRightDirIndLight "This signal indicates the state of the trailer right-hand direction indicator light(s).";
CM_ SG_ 2566808830 TrailerRightCrnMarkerLight "This signal indicates the state of the trailer right-hand corner marker light(s).";
CM_ SG_ 2566808830 TrailerRearWarningLight "This signal indicates the state of the trailer rear warning light(s).";
CM_ SG_ 2566808830 TrailerLeftStopLight "This signal indicates the state of the trailer left-hand stop light(s).";
CM_ BO_ 2564554494 "Reserved for ISO 15765";
CM_ SG_ 2564554494 ProtocolCtrlInformation "Part of Network Protocol Control Information (N_PCI) of a ISO 15765 message.";
CM_ BO_ 2564488958 "Reserved for ISO 15765";
CM_ SG_ 2564488958 ProtocolCtrlInformation "Part of Network Protocol Control Information (N_PCI) of a ISO 15765 message.";
CM_ BO_ 2565734142 "Used to access network interconnection ECU parametrics and database";
CM_ SG_ 2565734142 FilterMode "Filter mode for Network PG";
CM_ SG_ 2565734142 ToPort "Destination port for network PG";
CM_ SG_ 2565734142 FromPort "Source port for Network PG";
CM_ BO_ 2565144318 "ISO 11992: Towing vehicle message, running gear equipment #1/1

RGE11 replaces GFM 12 in ISO 11992:1998 part 3";
CM_ SG_ 2565144318 ParkingAndTrailerAirPress "The pneumatic pressure in the circuit or reservoir for the parking brake and the trailer supply.";
CM_ SG_ 2565144318 DrivenAxleLoad "Actual static vertical load on driven axle of the commercial vehicle. In case of more than one driven axle the value of the axle with the highest vertical load is transmitted.";
CM_ SG_ 2565144318 AuxEquipSupplyPressure "The pneumatic pressure in the auxiliary circuit.";
CM_ SG_ 2565144318 StopLevelChangeReq "Command signal to stop immediately any change of the actual body height level.";
CM_ SG_ 2565144318 RampLevelStorageReq "Command signal to store the actual body height level as new programmed and memorised ramp levels 1 or 2 in the ECU";
CM_ SG_ 2565144318 LevelControlReq "Command signal to enable or disable the automatic level control.";
CM_ SG_ 2565144318 RampLevelReq "Command signal to control the body height to a level programmed and memorised in the ECU.";
CM_ SG_ 2565144318 SteeringAxleLockingReq "Command signal to lock the steering axle.";
CM_ SG_ 2565144318 LiftAxle2PositionReq "Command signal to control the lift axle position / tag axle load condition.";
CM_ SG_ 2565144318 LiftAxle1PositionReq "Command signal to control the lift axle position / tag axle load condition.";
CM_ SG_ 2565144318 TractionHelpReq "Command signal to control the lift axle position / tag axle load condition to transfer more load on the driven axle of the commercial vehicle.";
CM_ SG_ 2565144318 LevelChangeReqRearAxle "Command signal to control the body height [up (lifting)/down (lowering)] for the rear axle.";
CM_ SG_ 2565144318 LevelChangeReqFrontAxle "Command signal to control the body height [up (lifting)/down (lowering)] for the front axle.";
CM_ SG_ 2565144318 RideHeightRequest "Command signal to activate a normal ride body height. The normal levels 1 and 2 are trailer specific body heights.";
CM_ BO_ 2565209854 "ISO 11992: Towed vehicle message, running gear equipment #2/1

RGE21 replaces GFM 22 in ISO 11992:1998 part 3";
CM_ SG_ 2565209854 LevelControl "Signal which indicates that the automatic level control is enabled or disabled.";
CM_ SG_ 2565209854 NominalVehBodyLevelRearAxle "Actual nominal vehicle body height.";
CM_ SG_ 2565209854 NominalVehBodyLevelFrontAxle "Actual nominal vehicle body height.";
CM_ SG_ 2565209854 RampLevel "Signal which indicates the level of the body height as an anser to 'ramp level request'.";
CM_ SG_ 2565209854 NormalLevel "Signal which indicates the normal levels of the vehicle independently of a specific request.";
CM_ SG_ 2565209854 StopLevelChangeAcknowledge "Signal which indicates the stop of any level change due to a 'stop request'.";
CM_ SG_ 2565209854 LevelChangeRearAxle "Signal which indicates the level change of the body height at the rear axle due to any external requests.";
CM_ SG_ 2565209854 LevelChangeFrontAxle "Signal which indicates the level change of the body height at the front axle due to any external requests.";
CM_ SG_ 2565209854 RampLevelStorage "Signal which indicates the storage of a new ramp level in the ECU.";
CM_ SG_ 2565209854 SteeringAxleLocking "Signal which indicates the actual steering axle locking status.";
CM_ SG_ 2565209854 LiftAxle2Pos "Signal which indicates the position / load condition of lift axle / tag axle #2.";
CM_ SG_ 2565209854 LiftAxle1Pos "Signal which indicates the position / load condition of lift axle / tag axle #1.";
CM_ SG_ 2565209854 RampLevelPosition "Signal which indicates the ramp level positions of the vehicle independently of a specific request.";
CM_ SG_ 2565209854 TractionHelp "Signal which indicates that a load transfer is active.";
CM_ SG_ 2565209854 LevelCtrlSysRideHeightLevel "Signal which indicates the body height position of the vehicle as an answer to 'ride height request'.";
CM_ BO_ 2566806782 "ISO 11992: Towed vehicle message, running gear equipment #2/2";
CM_ SG_ 2566806782 RelVehBodyLevelRearAxle "Actual relative vehicle body height.";
CM_ SG_ 2566806782 RelVehBodyLevelFrontAxle "Actual relative vehicle body height.";
CM_ BO_ 2566807294 "ISO 11992: Towed vehicle message, running gear equipment #2/3";
CM_ SG_ 2566807294 TyrePressThresholdDetect "Signal indicating the pressure level of the tyre.";
CM_ SG_ 2566807294 TyreModulePowerSupply "Signal indicating the power supply of the tyre module is sufficient to achieve the specified performance of the module.";
CM_ SG_ 2566807294 TyreTemperature "The temperature measured by the tyre module.";
CM_ SG_ 2566807294 AirLeakageDetection "The pressure loss of a tyre.";
CM_ SG_ 2566807294 TyreWheelIdentification2 "First part of the identification number of the tyre or whee (number of axles).";
CM_ SG_ 2566807294 TyreWheelIdentification1 "First part of the identification number of the tyre or whee (position on each axle).";
CM_ BO_ 2566764798 "Diagnostic readiness 3";
CM_ BO_ 2564095742 "Data security";
CM_ BO_ 2349137662 "External Brake Request";
CM_ SG_ 2349137662 XBRPriority "The XBR Priority is used as an input to the brake system to manage the priority of overlapping external and internal requests.";
CM_ SG_ 2349137662 ExtlAccelerationDemand "Parameter provided to the brake system from external sources.";
CM_ BO_ 2566848510 "Water in Fuel Indicator";
CM_ SG_ 2566848510 WaterInFuelIndicator "Signal which indicates the presence of water in the fuel.";
CM_ BO_ 2566843134 "Vehicle Weight";
CM_ SG_ 2566843134 CargoWeight "The mass of freight carried.";
CM_ SG_ 2566843134 TrailerWeight "Total mass of freight-carrying vehicle designed to be pulled by truck, including the weight of the contents.";
CM_ SG_ 2566843134 AxleWeight "Total mass imposed by the tires on the road surface at the specified axle.";
CM_ SG_ 2566843134 AxleLocation "To identify to which of several similar devices (such as tires or fuel tanks) the information applies.";
CM_ BO_ 2566804222 "Vehicle Electrical Power 3";
CM_ SG_ 2566804222 NetBatteryCurrentHiRes "Net flow of electrical current into/out-of the battery or batteries.";
CM_ SG_ 2566804222 AltCurrentHiRes "This parameter indicates the amount of electrical current output from the alternator of the main vehicle.";
CM_ BO_ 2633928190 "Vehicle Electrical Power 2";
CM_ SG_ 2633928190 Battery2Potential "The voltage for isolated battery #2.";
CM_ BO_ 2566845438 "Vehicle Position";
CM_ SG_ 2566845438 Longitude "Longitude position of the vehicle.";
CM_ SG_ 2566845438 Latitude "Latitude position of the vehicle.";
CM_ BO_ 2566843646 "Vehicle Identification";
CM_ BO_ 2566842366 "Vehicle Hours";
CM_ SG_ 2566842366 TotalPowerTakeoffHours "Accumulated time of operation of power takeoff device.";
CM_ SG_ 2566842366 TotalVehicleHours "Accumulated time of operation of vehicle.";
CM_ BO_ 2566809854 "Vehicle Fluids";
CM_ SG_ 2566809854 HydOilLevel "This parameter indicates the level of the hydraulic fluid in tank as a ratio of current volume to total tank volume.";
CM_ SG_ 2566809854 HydOilFilterRestrictionSwitch "This switch indicates whether hydraulic oil filter is clogged.";
CM_ SG_ 2566809854 HydTemp "Temperature of hydraulic fluid.";
CM_ BO_ 2566842622 "Vehicle Direction/Speed";
CM_ SG_ 2566842622 Altitude "Altitude of the vehicle referenced to sea level at standard atmospheric pressure and temperature.";
CM_ SG_ 2566842622 Pitch "Pitch of the vehicle as calculated by the navigation device(s).";
CM_ SG_ 2566842622 NavigationBasedVehicleSpeed "Speed of the vehicle as calculated from a device such as a Global Positioning System (GPS).";
CM_ SG_ 2566842622 CompassBearing "Present compass bearing of vehicle.";
CM_ BO_ 2566832638 "High Resolution Vehicle Distance";
CM_ SG_ 2566832638 HighResolutionTripDistance "Distance traveled during all or part of a journey.";
CM_ SG_ 2566832638 HghRslutionTotalVehicleDistance "Accumulated distance traveled by the vehicle during its operation.";
CM_ BO_ 2565868030 "Vehicle Dynamic Stability Control 2";
CM_ SG_ 2565868030 LongitudinalAcceleration "Indicates the longitudinal acceleration of the vehicle.";
CM_ SG_ 2565868030 LateralAcceleration "Indicates a lateral acceleration of the vehicle.";
CM_ SG_ 2565868030 YawRate "Indicates the rotation about the vertical axis.";
CM_ SG_ 2565868030 SteerWheelTurnCounter "Indicates number of steering wheel turns, absolute position or relative position at ignition on.";
CM_ SG_ 2565868030 SteerWheelAngle "The main operator`s steering wheel angle (on the steering column, not the actual wheel angle).";
CM_ BO_ 2566803454 "Vehicle Dynamic Stability Control 1";
CM_ SG_ 2566803454 YCBrakeCtrlActive "State signal which indicates that Yaw Control (YC) has activated brake control.";
CM_ SG_ 2566803454 YCEngCtrlActive "State Signal which indicates that the Yaw Control (YC) has commanded engine control to be active.";
CM_ SG_ 2566803454 ROPBrakeCtrlActive "State signal which indicates that Roll over Prevention (ROP) has activated brake control.";
CM_ SG_ 2566803454 ROPEngCtrlActive "State Signal which indicates that the Roll Over Prevention (ROP) has commanded engine control to be active.";
CM_ SG_ 2566803454 VDCFullyOperational "Signal that indicates whether VDC is fully operational or whether its functionality is reduced by a permanent or temporary (e.";
CM_ SG_ 2566803454 VDCInformationSignal "This parameter commands the VDC information signal, for example a dash lamp.";
CM_ BO_ 2566840574 "Vehicle Distance";
CM_ SG_ 2566840574 TotalVehicleDistance "Accumulated distance traveled by vehicle during its operation.";
CM_ SG_ 2566840574 TripDistance "Distance traveled during all or part of a journey.";
CM_ BO_ 2633938686 "Trip Vehicle Speed/Cruise Distance Information";
CM_ BO_ 2633937150 "Trip Time Information 2";
CM_ SG_ 2633937150 TripAirCompressorOnTime "Total time that the air compressor is on and compressing air since the last trip reset.";
CM_ SG_ 2633937150 TripEngRunningTime "Total time accumulated while the engine speed is greater than zero since the last trip reset.";
CM_ SG_ 2633937150 TripPTOTime "Total time accumulated while the engine is in the PTO or remote PTO hold state since the last trip reset.";
CM_ SG_ 2633937150 TripCruiseTime "Total time accumulated while the engine is in the cruise hold state, excluding time in accelerator override, since the last trip reset.";
CM_ BO_ 2633938174 "Trip Time Information 1";
CM_ SG_ 2633938174 TripTimeInDerateByEng "Total time accumulated when the engine final fueling has been derated due to an engine protection algorithm, since the last reset.";
CM_ SG_ 2633938174 TripTimeInTopGear "Total time accumulated when the vehicle has operated in top gear for a calibrated minimum time, since the last trip reset.";
CM_ BO_ 2633938430 "Trip Shutdown Information";
CM_ SG_ 2633938430 TrpNmberOfIdleShutdownOverrides "Total number of times an operator disables idle shutdown to prevent an engine shutdown, since the last trip reset.";
CM_ SG_ 2633938430 TripNumberOfIdleShutdowns "Total number of times the engine has been shutdown due to idling too long (at normal idle or fast idle) since the last trip reset.";
CM_ SG_ 2633938430 TripNumberOfHotShutdowns "Total number of hot shutdowns since the last trip reset.";
CM_ BO_ 2348875518 "Torque/Speed Control 1";
CM_ SG_ 2348875518 ControlPurpose "State signal which indicates which control mode the sending device is using to generate the TSC1 command.";
CM_ SG_ 2348875518 TransmissionRate "This parameter indicates the transmission rate at which the sending device will transmit the TSC1 message.";
CM_ SG_ 2348875518 EngRqedTorque_TorqueLimit "Parameter provided to the engine or retarder in the torque/speed control message for controlling or limiting the output torque.";
CM_ SG_ 2348875518 EngRqedSpeed_SpeedLimit "Parameter provided to the engine from external sources in the torque/speed control message.";
CM_ SG_ 2348875518 EngRqedSpeedCtrlConditions "This mode tells the engine control system the governor characteristics that are desired during speed control.";
CM_ BO_ 2566766846 "Passenger Counter";
CM_ SG_ 2566766846 TransitRunStatus "Status of the run switch for the vehicle.";
CM_ SG_ 2566766846 VehicleUseStatus "Used to indicate the proper or unauthorized use of the vehicle.";
CM_ SG_ 2566766846 SilentAlarmStatus "Used to report silent alarm push button status.";
CM_ SG_ 2566766846 PatronCount "Count of the number of passengers on a transit vehicle.";
CM_ SG_ 2566766846 TypeOfPassengerCount "Used to notify transit link devices of the type of passenger counting system used in the vehicle.";
CM_ BO_ 2566765310 "Farebox Status";
CM_ SG_ 2566765310 FareboxAlarmIdentifier "Indicates the nature of the farebox alarm condition.";
CM_ SG_ 2566765310 FareboxEmergencyStatus "Indicates if a farebox emergency condition exists.";
CM_ BO_ 2566765566 "Farebox Point of Sale";
CM_ SG_ 2566765566 TransferSold "Indicates that a transfer was sold or issued on this transaction including its type and/or restrictions.";
CM_ SG_ 2566765566 RouteNumber "The route number issuing the transfer.";
CM_ SG_ 2566765566 PaymentDetails "Payment details.";
CM_ SG_ 2566765566 PassengerType "Enumerated value representing the type/class of passenger, as defined by the agency.";
CM_ BO_ 2566765822 "Farebox Service Detail";
CM_ SG_ 2566765822 DriversFareboxSecurityCode "Security code for the farebox, numerical only.";
CM_ SG_ 2566765822 AssignedRoute "The identity number assigned to this route.";
CM_ SG_ 2566765822 TripNumber "The identity number assigned to this trip.";
CM_ SG_ 2566765822 TripDirection "The general direction of travel for this trip.";
CM_ SG_ 2566765822 FareboxServiceStatus "Indicates if the farebox is in or out of service.";
CM_ BO_ 2566766078 "Signal Preemption";
CM_ SG_ 2566766078 VehicleID "Numerical designation of the vehicle.";
CM_ BO_ 2566766590 "Transit Milepost";
CM_ BO_ 2566766334 "Transit Route";
CM_ BO_ 2561605374 "Tire Pressure Reference Setting";
CM_ SG_ 2561605374 TireLocation "Identifies which tire is associated with the parametric data in this PGN.";
CM_ BO_ 2566765054 "Tire Pressure Reference Information";
CM_ SG_ 2566765054 TireLocation "Identifies which tire is associated with the parametric data in this PGN.";
CM_ BO_ 2633923326 "Tire Pressure Control Unit Current Pressures";
CM_ SG_ 2633923326 SteerChannelTirePress "The latest gage pressure reading of the steer group of tires, as opposed to the pressure in each tire.";
CM_ SG_ 2633923326 DriveChannelTirePress "The latest gage pressure reading of the drive group of tires, as opposed to the pressure in each tire.";
CM_ SG_ 2633923326 TrailerTagPushChannelTirePress "The latest gage pressure reading of the trailer, tag, or push group of tires, as opposed to the pressure in each tire.";
CM_ BO_ 2633923070 "Tire Pressure Control Unit Target Pressures";
CM_ SG_ 2633923070 SteerChannelTirePressTarget "The tire pressure control system’s target gage pressure for the steer group of tires.";
CM_ SG_ 2633923070 DriveChannelTirePressTarget "The tire pressure control system’s target gage pressure for the drive group of tires.";
CM_ SG_ 2633923070 TrlrTgPshChannelTirePressTarget "The tire pressure control system’s target gage pressure for the trailer, tag, or push group of tires.";
CM_ BO_ 2633922814 "Tire Pressure Control Unit Mode and Status";
CM_ SG_ 2633922814 PCUSupplySolenoidStatus "Current state of the supply solenoid used to implement a tire pressure control system in its pneumatic control unit (PCU).";
CM_ SG_ 2633922814 PCUCtrlSolenoidStatus "Current state of the control solenoid used to implement a tire pressure control system in its pneumatic control unit (PCU).";
CM_ SG_ 2633922814 PCUDeflateSolenoidStatus "Current state of the deflate solenoid used to implement a tire pressure control system in its pneumatic control unit (PCU).";
CM_ SG_ 2633922814 TirePressSupplySwitchStatus "Current state of an open/closed type switch used to determine if adequate pressure exists for system implementation.";
CM_ SG_ 2633922814 PCUSteerSolenoidStatus "Current state of the steer solenoid used to implement a tire pressure control system in its pneumatic control unit (PCU).";
CM_ SG_ 2633922814 PCUDriveSolenoidStatus "Current state of the drive solenoid used to implement a tire pressure control system in its pneumatic control unit (PCU).";
CM_ SG_ 2633922814 DriveChannelMode "Indicates the functional mode of trailer/tag channel of the tire pressure control system.";
CM_ SG_ 2633922814 Trailer_TagChannelMode "Indicates the functional mode of trailer/tag channel of the tire pressure control system.";
CM_ SG_ 2633922814 SteerChannelMode "Indicates the functional mode of steer channel of the tire pressure control system.";
CM_ SG_ 2633922814 TirePressCheckInterval "The interval at which the system will check the tire pressures (e.";
CM_ BO_ 2566845694 "Tire Condition";
CM_ SG_ 2566845694 TirePressThresholdDetection "Signal indicating the pressure level of the tire.";
CM_ SG_ 2566845694 TireAirLeakageRate "The pressure loss rate of a tire.";
CM_ SG_ 2566845694 CTIWheelEndElectricalFault "Indicates the status of electrical fault on CTI wheel interface.";
CM_ SG_ 2566845694 CTITireStatus "Indicates the status of the tire.";
CM_ SG_ 2566845694 CTIWheelSensorStatus "Indicates whether the wheel is being monitored by the CTI controller.";
CM_ SG_ 2566845694 TireTemp "Temperature at the surface of the tire sidewall.";
CM_ SG_ 2566845694 TirePress "Pressure at which air is contained in cavity formed by tire and rim.";
CM_ SG_ 2566845694 TireLocation "Identifies which tire is associated with the parametric data in this PGN.";
CM_ BO_ 2566805246 "Tank Information 1";
CM_ SG_ 2566805246 CatalystTankTemp "Temperature of the reagent in the storage tank.";
CM_ SG_ 2566805246 CatalystTankLevel "A special catalyst uses chemical substance to reach legal requirement for NOX emissions.";
CM_ SG_ 2566805246 CatalystTankLevelPreliminaryFMI "Used to identify the applicable J1939-73 FMI that applies to the most significant failure of the catalyst tank level sensor.";
CM_ SG_ 2566805246 CatalystTankLevel2 "The measure of the reagent level in the catalyst tank.";
CM_ BO_ 2633939966 "Trip Fan Information";
CM_ SG_ 2633939966 TripFanOnTimeDueToAManualSwitch "Total time the fan has been on due to manual activation by the operator (i.";
CM_ SG_ 2633939966 TripFanOnTime "Total time the fan has been on (due to an automatic trigger or manual trigger) since the last trip reset.";
CM_ SG_ 2633939966 TripFanOnTimeDueToA_CSystem "Total time the fan has been on due to the A/C system since the last trip reset.";
CM_ SG_ 2633939966 TripFanOnTimeDueToEngSystem "Total time the fan has been on due to engine triggers (i.";
CM_ BO_ 2633939710 "Trip Distance Information";
CM_ SG_ 2633939710 TripDistanceInTopGear "Total distance accumulated while the vehicle has operated in top gear for a calibrated minimum time since the last trip reset.";
CM_ SG_ 2633939710 TripDistanceOnVSL "Total distance accumulated while the engine torque mode is road speed governing since the last trip reset.";
CM_ BO_ 2564161278 "Time/Date Adjust";
CM_ SG_ 2564161278 AdjustLocalMinuteOffset "Used to set the local offset in minutes from a reference time.";
CM_ SG_ 2564161278 AdjustYear "Part of a parameter used to set a calendar date.";
CM_ SG_ 2564161278 AdjustDay "Part of a parameter used to set a calendar date.";
CM_ SG_ 2564161278 AdjustMonth "Part of a parameter used to set a calendar date.";
CM_ SG_ 2564161278 AdjustHours "Part of the parameter used to set the time.";
CM_ SG_ 2564161278 AdjustMinutes "Part of the parameter used to set the time.";
CM_ SG_ 2564161278 AdjustSeconds "Part of the parameter used to set the time.";
CM_ BO_ 2566842110 "Time/Date";
CM_ SG_ 2566842110 LocalMinuteOffset "Local offset in minutes from a reference time.";
CM_ SG_ 2566842110 Year "Part of a parameter used to represent a calendar date.";
CM_ SG_ 2566842110 Day "Part of a parameter used to represent a calendar date.";
CM_ SG_ 2566842110 Month "Part of a parameter used to represent a calendar date.";
CM_ SG_ 2566842110 Hours "Part of a parameter used to represent time.";
CM_ SG_ 2566842110 Minutes "Part of a parameter used to represent time.";
CM_ SG_ 2566842110 Seconds "Part of a parameter used to represent time.";
CM_ BO_ 2566821630 "Turbocharger Wastegate";
CM_ SG_ 2566821630 EngTrbWstgtActuatorCtrlAirPress "Gage pressure of the air used to control the actuator which opens and closes the wastegate valve.";
CM_ SG_ 2566821630 EngTurbo4WastegateDrive "Position of the wastegate drive.";
CM_ SG_ 2566821630 EngTurbo3WastegateDrive "Position of the wastegate drive.";
CM_ SG_ 2566821630 EngTurbo2WastegateDrive "Position of the wastegate drive.";
CM_ SG_ 2566821630 EngTurbo1WastegateDrive "Position of the wastegate drive.";
CM_ BO_ 2365484286 "Tachograph";
CM_ SG_ 2365484286 TachographVehicleSpeed "Speed of the vehicle registered by the tachograph.";
CM_ SG_ 2365484286 TachographOutputShaftSpeed "Calculated speed of the transmission output shaft.";
CM_ SG_ 2365484286 DirectionIndicator "Indicates the direction of the vehicle.";
CM_ SG_ 2365484286 HandlingInformation "Indicates that handling information is present.";
CM_ SG_ 2365484286 SystemEvent "Indicates that a tachograph event has occurred.";
CM_ SG_ 2365484286 Driver2TimeRelatedStates "Indicates if the driver approaches or exceeds working time limits (or other limits).";
CM_ SG_ 2365484286 Overspeed "Indicates whether the vehicle is exceeding the legal speed limit set in the tachograph.";
CM_ SG_ 2365484286 Driver1TimeRelatedStates "Indicates if the driver approaches or exceeds working time limits (or other limits).";
CM_ SG_ 2365484286 DriveRecognize "Indicates whether motion of the vehicle is detected or not.";
CM_ SG_ 2365484286 Driver2WorkingState "State of work of the driver.";
CM_ SG_ 2365484286 Driver1WorkingState "State of work of the driver.";
CM_ BO_ 2566771710 "Turbocharger Information 6";
CM_ BO_ 2566821886 "Turbocharger Information 5";
CM_ SG_ 2566821886 EngTurbo4TurbineOutletTemp "Temperature of the combustion by-products exiting the turbine side of the turbocharger.";
CM_ SG_ 2566821886 EngTurbo3TurbineOutletTemp "Temperature of the combustion by-products exiting the turbine side of the turbocharger.";
CM_ SG_ 2566821886 EngTurbo2TurbineOutletTemp "Temperature of the combustion by-products exiting the turbine side of the turbocharger.";
CM_ SG_ 2566821886 EngTurbo1TurbineOutletTemp "Temperature of the combustion by-products exiting the turbine side of the turbocharger.";
CM_ BO_ 2566822142 "Turbocharger Information 4";
CM_ SG_ 2566822142 EngTurbo4TurbineInletTemp "Temperature of the combustion by-products entering the turbine side of the turbocharger.";
CM_ SG_ 2566822142 EngTurbo3TurbineInletTemp "Temperature of the combustion by-products entering the turbine side of the turbocharger.";
CM_ SG_ 2566822142 EngTurbo2TurbineInletTemp "Temperature of the combustion by-products entering the turbine side of the turbocharger.";
CM_ SG_ 2566822142 EngTurbo1TurbineInletTemp "Temperature of the combustion by-products entering the turbine side of the turbocharger.";
CM_ BO_ 2566822398 "Turbocharger Information 3";
CM_ SG_ 2566822398 EngTurbo4CompressorInletPress "Gage pressure of the air entering the compressor side of the turbocharger.";
CM_ SG_ 2566822398 EngTurbo3CompressorInletPress "Gage pressure of the air entering the compressor side of the turbocharger.";
CM_ SG_ 2566822398 EngTurbo2CompressorInletPress "Gage pressure of the air entering the compressor side of the turbocharger.";
CM_ SG_ 2566822398 EngTurbo1CompressorInletPress "Gage pressure of the air entering the compressor side of the turbocharger.";
CM_ BO_ 2566822654 "Turbocharger Information 2";
CM_ SG_ 2566822654 EngTurbo4CompressorInletTemp "Temperature of the air entering the compressor side of the turbocharger.";
CM_ SG_ 2566822654 EngTurbo3CompressorInletTemp "Temperature of the air entering the compressor side of the turbocharger.";
CM_ SG_ 2566822654 EngTurbo2CompressorInletTemp "Temperature of the air entering the compressor side of the turbocharger.";
CM_ SG_ 2566822654 EngTurbo1CompressorInletTemp "Temperature of the air entering the compressor side of the turbocharger.";
CM_ BO_ 2633931774 "Turbocharger Information 1";
CM_ SG_ 2633931774 EngTurbo4Speed "Rotational velocity of rotor in the turbocharger.";
CM_ SG_ 2633931774 EngTurbo3Speed "Rotational velocity of rotor in the turbocharger.";
CM_ SG_ 2633931774 EngTurbo2Speed "Rotational velocity of rotor in the turbocharger.";
CM_ SG_ 2633931774 EngTurboLubeOilPress2 "Gage pressure of oil in turbocharger lubrication system.";
CM_ BO_ 2566802430 "Transmission Configuration 2";
CM_ BO_ 2566841086 "Transmission Configuration";
CM_ SG_ 2566841086 NumberOfForwardGearRatios "Number of forward gear ratios in the transmission, provided as part of the configuration.";
CM_ SG_ 2566841086 NumberOfReverseGearRatios "Number of reverse gear ratios in the transmission, provided as part of the transmission configuration.";
BA_DEF_ BO_  "FrameFormat" ENUM  "StandardCAN","ExtendedCAN","reserved","J1939PG";
BA_DEF_ SG_  "SigType" STRING ;
BA_DEF_ SG_  "SPN" INT 0 524287;
BA_DEF_ BO_  "GenMsgRequestable" INT 0 1;
BA_DEF_ BO_  "GenMsgSendType" ENUM  "cyclic","spontan","cyclicIfActive","spontanWithDelay","cyclicAndSpontan","cyclicAndSpontanWithDelay","spontanWithRepetition","cyclicIfActiveAndSpontanWD","noMsgSendType";
BA_DEF_ BO_  "VFrameFormat" ENUM  "StandardCAN","ExtendedCAN","reserved","J1939PG";
BA_DEF_ BO_  "GenMsgCycleTime" INT 0 3600000;
BA_DEF_DEF_  "FrameFormat" "J1939PG";
BA_DEF_DEF_  "SigType" "";
BA_DEF_DEF_  "SPN" 0;
BA_DEF_DEF_  "GenMsgRequestable" 1;
BA_DEF_DEF_  "GenMsgSendType" "noMsgSendType";
BA_DEF_DEF_  "VFrameFormat" "J1939PG";
BA_DEF_DEF_  "GenMsgCycleTime" 0;
BA_ "GenMsgSendType" BO_ 2566757374 0;
BA_ "GenMsgCycleTime" BO_ 2566757374 1000;
BA_ "GenMsgSendType" BO_ 2566758654 0;
BA_ "GenMsgCycleTime" BO_ 2566758654 500;
BA_ "GenMsgSendType" BO_ 2566758910 0;
BA_ "GenMsgCycleTime" BO_ 2566758910 500;
BA_ "GenMsgSendType" BO_ 2566758142 0;
BA_ "GenMsgCycleTime" BO_ 2566758142 500;
BA_ "GenMsgSendType" BO_ 2566758398 0;
BA_ "GenMsgCycleTime" BO_ 2566758398 500;
BA_ "GenMsgSendType" BO_ 2364546302 0;
BA_ "GenMsgCycleTime" BO_ 2364546302 100;
BA_ "GenMsgSendType" BO_ 2431654654 0;
BA_ "GenMsgCycleTime" BO_ 2431654654 50;
BA_ "GenMsgSendType" BO_ 2364545534 0;
BA_ "GenMsgCycleTime" BO_ 2364545534 5000;
BA_ "GenMsgSendType" BO_ 2364545278 0;
BA_ "GenMsgCycleTime" BO_ 2364545278 5000;
BA_ "GenMsgSendType" BO_ 2364545022 0;
BA_ "GenMsgCycleTime" BO_ 2364545022 5000;
BA_ "GenMsgSendType" BO_ 2364544766 0;
BA_ "GenMsgCycleTime" BO_ 2364544766 5000;
BA_ "GenMsgSendType" BO_ 2364544510 0;
BA_ "GenMsgCycleTime" BO_ 2364544510 100;
BA_ "GenMsgSendType" BO_ 2364544254 0;
BA_ "GenMsgCycleTime" BO_ 2364544254 50;
BA_ "GenMsgSendType" BO_ 2349006590 0;
BA_ "GenMsgCycleTime" BO_ 2349006590 10;
BA_ "GenMsgSendType" BO_ 2566834686 0;
BA_ "GenMsgCycleTime" BO_ 2566834686 100;
BA_ "GenMsgSendType" BO_ 2550398718 0;
BA_ "GenMsgCycleTime" BO_ 2550398718 10;
BA_ "GenMsgSendType" BO_ 2566833406 0;
BA_ "GenMsgCycleTime" BO_ 2566833406 100;
BA_ "GenMsgSendType" BO_ 2365507326 0;
BA_ "GenMsgCycleTime" BO_ 2365507326 100;
BA_ "GenMsgSendType" BO_ 2565013246 0;
BA_ "GenMsgCycleTime" BO_ 2565013246 100;
BA_ "GenMsgSendType" BO_ 2566807038 0;
BA_ "GenMsgCycleTime" BO_ 2566807038 500;
BA_ "GenMsgSendType" BO_ 2365480958 0;
BA_ "GenMsgCycleTime" BO_ 2365480958 50;
BA_ "GenMsgSendType" BO_ 2566808062 0;
BA_ "GenMsgCycleTime" BO_ 2566808062 100;
BA_ "GenMsgSendType" BO_ 2566808574 0;
BA_ "GenMsgCycleTime" BO_ 2566808574 1000;
BA_ "GenMsgSendType" BO_ 2566809086 0;
BA_ "GenMsgCycleTime" BO_ 2566809086 100;
BA_ "GenMsgSendType" BO_ 2564947710 0;
BA_ "GenMsgCycleTime" BO_ 2564947710 100;
BA_ "GenMsgSendType" BO_ 2566834430 0;
BA_ "GenMsgCycleTime" BO_ 2566834430 100;
BA_ "GenMsgSendType" BO_ 2365481214 0;
BA_ "GenMsgCycleTime" BO_ 2365481214 100;
BA_ "GenMsgSendType" BO_ 2566808318 0;
BA_ "GenMsgCycleTime" BO_ 2566808318 100;
BA_ "GenMsgSendType" BO_ 2566808830 0;
BA_ "GenMsgCycleTime" BO_ 2566808830 100;
BA_ "GenMsgSendType" BO_ 2565144318 0;
BA_ "GenMsgCycleTime" BO_ 2565144318 100;
BA_ "GenMsgSendType" BO_ 2565209854 0;
BA_ "GenMsgCycleTime" BO_ 2565209854 100;
BA_ "GenMsgSendType" BO_ 2566806782 0;
BA_ "GenMsgCycleTime" BO_ 2566806782 100;
BA_ "GenMsgSendType" BO_ 2566807294 0;
BA_ "GenMsgCycleTime" BO_ 2566807294 1000;
BA_ "GenMsgSendType" BO_ 2349137662 2;
BA_ "GenMsgCycleTime" BO_ 2349137662 20;
BA_ "GenMsgSendType" BO_ 2566848510 0;
BA_ "GenMsgCycleTime" BO_ 2566848510 10000;
BA_ "GenMsgSendType" BO_ 2566804222 0;
BA_ "GenMsgCycleTime" BO_ 2566804222 1000;
BA_ "GenMsgSendType" BO_ 2566845438 0;
BA_ "GenMsgCycleTime" BO_ 2566845438 5000;
BA_ "GenMsgSendType" BO_ 2566809854 0;
BA_ "GenMsgCycleTime" BO_ 2566809854 1000;
BA_ "GenMsgSendType" BO_ 2566832638 0;
BA_ "GenMsgCycleTime" BO_ 2566832638 1000;
BA_ "GenMsgSendType" BO_ 2565868030 0;
BA_ "GenMsgCycleTime" BO_ 2565868030 10;
BA_ "GenMsgSendType" BO_ 2566803454 0;
BA_ "GenMsgCycleTime" BO_ 2566803454 100;
BA_ "GenMsgSendType" BO_ 2566840574 0;
BA_ "GenMsgCycleTime" BO_ 2566840574 100;
BA_ "GenMsgSendType" BO_ 2566845694 0;
BA_ "GenMsgCycleTime" BO_ 2566845694 10000;
BA_ "GenMsgSendType" BO_ 2566805246 0;
BA_ "GenMsgCycleTime" BO_ 2566805246 1000;
BA_ "GenMsgSendType" BO_ 2566821630 0;
BA_ "GenMsgCycleTime" BO_ 2566821630 100;
BA_ "GenMsgSendType" BO_ 2365484286 0;
BA_ "GenMsgCycleTime" BO_ 2365484286 50;
BA_ "GenMsgSendType" BO_ 2566771710 0;
BA_ "GenMsgCycleTime" BO_ 2566771710 1000;
BA_ "GenMsgSendType" BO_ 2566821886 0;
BA_ "GenMsgCycleTime" BO_ 2566821886 1000;
BA_ "GenMsgSendType" BO_ 2566822142 0;
BA_ "GenMsgCycleTime" BO_ 2566822142 1000;
BA_ "GenMsgSendType" BO_ 2566822398 0;
BA_ "GenMsgCycleTime" BO_ 2566822398 1000;
BA_ "GenMsgSendType" BO_ 2566822654 0;
BA_ "GenMsgCycleTime" BO_ 2566822654 1000;
BA_ "GenMsgSendType" BO_ 2633931774 0;
BA_ "GenMsgCycleTime" BO_ 2633931774 1000;
BA_ "SigType" SG_ 2566757374 CatalystReagentType "DISCRETE";
BA_ "SPN" SG_ 2566757374 CatalystReagentType 3521;
BA_ "SigType" SG_ 2566757374 CtlystRgntPrprtesPreliminaryFMI "DISCRETE";
BA_ "SPN" SG_ 2566757374 CtlystRgntPrprtesPreliminaryFMI 3520;
BA_ "SigType" SG_ 2566757374 CtlystRagentTemp2PreliminaryFMI "DISCRETE";
BA_ "SPN" SG_ 2566757374 CtlystRagentTemp2PreliminaryFMI 3519;
BA_ "SigType" SG_ 2566757374 CatalystReagentConductivity "RANGE";
BA_ "SPN" SG_ 2566757374 CatalystReagentConductivity 3518;
BA_ "SigType" SG_ 2566757374 CatalystReagentConcentration "RANGE";
BA_ "SPN" SG_ 2566757374 CatalystReagentConcentration 3516;
BA_ "SigType" SG_ 2566757374 CatalystReagentTemp2 "RANGE";
BA_ "SPN" SG_ 2566757374 CatalystReagentTemp2 3515;
BA_ "SigType" SG_ 2566756862 AftrTrtmnt2TtlNmbrOfActvRgnrtns "RANGE";
BA_ "SPN" SG_ 2566756862 AftrTrtmnt2TtlNmbrOfActvRgnrtns 3529;
BA_ "SigType" SG_ 2566756862 AftrTreatment2TotalDisabledTime "RANGE";
BA_ "SPN" SG_ 2566756862 AftrTreatment2TotalDisabledTime 3528;
BA_ "SigType" SG_ 2566756862 AftrTrtmnt2TtalRegenerationTime "RANGE";
BA_ "SPN" SG_ 2566756862 AftrTrtmnt2TtalRegenerationTime 3527;
BA_ "SigType" SG_ 2566756862 AfterTreatment2TotalFuelUsed "RANGE";
BA_ "SPN" SG_ 2566756862 AfterTreatment2TotalFuelUsed 3526;
BA_ "SigType" SG_ 2566758654 Aftrtratment2FuelEnableActuator "DISCRETE";
BA_ "SPN" SG_ 2566758654 Aftrtratment2FuelEnableActuator 3496;
BA_ "SigType" SG_ 2566758654 Aftrtratment2RegenerationStatus "DISCRETE";
BA_ "SPN" SG_ 2566758654 Aftrtratment2RegenerationStatus 3497;
BA_ "SigType" SG_ 2566758654 Aftertreatment2Ignt "DISCRETE";
BA_ "SPN" SG_ 2566758654 Aftertreatment2Ignt 3498;
BA_ "SigType" SG_ 2566758654 Aftertreatment2FuelPressCtrl "RANGE";
BA_ "SPN" SG_ 2566758654 Aftertreatment2FuelPressCtrl 3493;
BA_ "SigType" SG_ 2566758654 Aftertreatment2FuelRate "RANGE";
BA_ "SPN" SG_ 2566758654 Aftertreatment2FuelRate 3495;
BA_ "SigType" SG_ 2566758654 Aftertreatment2FuelPress "RANGE";
BA_ "SPN" SG_ 2566758654 Aftertreatment2FuelPress 3494;
BA_ "SigType" SG_ 2566758910 Aftrtratment1FuelEnableActuator "DISCRETE";
BA_ "SPN" SG_ 2566758910 Aftrtratment1FuelEnableActuator 3482;
BA_ "SigType" SG_ 2566758910 Aftrtratment1RegenerationStatus "DISCRETE";
BA_ "SPN" SG_ 2566758910 Aftrtratment1RegenerationStatus 3483;
BA_ "SigType" SG_ 2566758910 Aftertreatment1Ignt "DISCRETE";
BA_ "SPN" SG_ 2566758910 Aftertreatment1Ignt 3484;
BA_ "SigType" SG_ 2566758910 Aftertreatment1FuelPressCtrl "RANGE";
BA_ "SPN" SG_ 2566758910 Aftertreatment1FuelPressCtrl 3479;
BA_ "SigType" SG_ 2566758910 Aftertreatment1FuelRate "RANGE";
BA_ "SPN" SG_ 2566758910 Aftertreatment1FuelRate 3481;
BA_ "SigType" SG_ 2566758910 Aftertreatment1FuelPress "RANGE";
BA_ "SPN" SG_ 2566758910 Aftertreatment1FuelPress 3480;
BA_ "SigType" SG_ 2566758142 Aftrtreatment2AirEnableActuator "DISCRETE";
BA_ "SPN" SG_ 2566758142 Aftrtreatment2AirEnableActuator 3503;
BA_ "SigType" SG_ 2566758142 Aftertreatment2PurgeAirActuator "DISCRETE";
BA_ "SPN" SG_ 2566758142 Aftertreatment2PurgeAirActuator 3504;
BA_ "SigType" SG_ 2566758142 Aftrtrtmnt2AtmzationAirActuator "DISCRETE";
BA_ "SPN" SG_ 2566758142 Aftrtrtmnt2AtmzationAirActuator 3505;
BA_ "SigType" SG_ 2566758142 Aftertreatment2AirSystemRelay "DISCRETE";
BA_ "SPN" SG_ 2566758142 Aftertreatment2AirSystemRelay 3506;
BA_ "SigType" SG_ 2566758142 Aftrtrtment2AirPressActuatorPos "RANGE";
BA_ "SPN" SG_ 2566758142 Aftrtrtment2AirPressActuatorPos 3502;
BA_ "SigType" SG_ 2566758142 Aftertreatment2AirPressCtrl "RANGE";
BA_ "SPN" SG_ 2566758142 Aftertreatment2AirPressCtrl 3501;
BA_ "SigType" SG_ 2566758142 Aftertreatment2PurgeAirPress "RANGE";
BA_ "SPN" SG_ 2566758142 Aftertreatment2PurgeAirPress 3500;
BA_ "SigType" SG_ 2566758142 Aftertreatment2SupplyAirPress "RANGE";
BA_ "SPN" SG_ 2566758142 Aftertreatment2SupplyAirPress 3499;
BA_ "SigType" SG_ 2566758398 Aftrtreatment1AirEnableActuator "DISCRETE";
BA_ "SPN" SG_ 2566758398 Aftrtreatment1AirEnableActuator 3489;
BA_ "SigType" SG_ 2566758398 Aftertreatment1PurgeAirActuator "DISCRETE";
BA_ "SPN" SG_ 2566758398 Aftertreatment1PurgeAirActuator 3490;
BA_ "SigType" SG_ 2566758398 Aftrtrtmnt1AtmzationAirActuator "DISCRETE";
BA_ "SPN" SG_ 2566758398 Aftrtrtmnt1AtmzationAirActuator 3491;
BA_ "SigType" SG_ 2566758398 Aftertreatment1AirSystemRelay "DISCRETE";
BA_ "SPN" SG_ 2566758398 Aftertreatment1AirSystemRelay 3492;
BA_ "SigType" SG_ 2566758398 Aftrtrtment1AirPressActuatorPos "RANGE";
BA_ "SPN" SG_ 2566758398 Aftrtrtment1AirPressActuatorPos 3488;
BA_ "SigType" SG_ 2566758398 Aftertreatment1AirPressCtrl "RANGE";
BA_ "SPN" SG_ 2566758398 Aftertreatment1AirPressCtrl 3487;
BA_ "SigType" SG_ 2566758398 Aftertreatment1PurgeAirPress "RANGE";
BA_ "SPN" SG_ 2566758398 Aftertreatment1PurgeAirPress 3486;
BA_ "SigType" SG_ 2566758398 Aftertreatment1SupplyAirPress "RANGE";
BA_ "SPN" SG_ 2566758398 Aftertreatment1SupplyAirPress 3485;
BA_ "SigType" SG_ 2566756606 AftrTrtmnt1TtlNmbrOfActvRgnrtns "RANGE";
BA_ "SPN" SG_ 2566756606 AftrTrtmnt1TtlNmbrOfActvRgnrtns 3525;
BA_ "SigType" SG_ 2566756606 AftrTrtmnt1TtalRegenerationTime "RANGE";
BA_ "SPN" SG_ 2566756606 AftrTrtmnt1TtalRegenerationTime 3523;
BA_ "SigType" SG_ 2566756606 AftrTreatment1TotalDisabledTime "RANGE";
BA_ "SPN" SG_ 2566756606 AftrTreatment1TotalDisabledTime 3524;
BA_ "SigType" SG_ 2566756606 AfterTreatment1TotalFuelUsed "RANGE";
BA_ "SPN" SG_ 2566756606 AfterTreatment1TotalFuelUsed 3522;
BA_ "SigType" SG_ 2364546302 RqdGnrtrAvrgLneLineACRMSVoltage "RANGE";
BA_ "SPN" SG_ 2364546302 RqdGnrtrAvrgLneLineACRMSVoltage 3386;
BA_ "SigType" SG_ 2431654654 EngThrottleActuator2CtrlCmd "RANGE";
BA_ "SPN" SG_ 2431654654 EngThrottleActuator2CtrlCmd 3465;
BA_ "SigType" SG_ 2431654654 EngThrottleActuator1CtrlCmd "RANGE";
BA_ "SPN" SG_ 2431654654 EngThrottleActuator1CtrlCmd 3464;
BA_ "SigType" SG_ 2431654654 EngFuelActuator2CtrlCmd "RANGE";
BA_ "SPN" SG_ 2431654654 EngFuelActuator2CtrlCmd 1244;
BA_ "SigType" SG_ 2431654654 EngFuelActuator1CtrlCmd "RANGE";
BA_ "SPN" SG_ 2431654654 EngFuelActuator1CtrlCmd 633;
BA_ "SigType" SG_ 2364545534 EngCyl24KnockLevel "RANGE";
BA_ "SPN" SG_ 2364545534 EngCyl24KnockLevel 1375;
BA_ "SigType" SG_ 2364545534 EngCyl23KnockLevel "RANGE";
BA_ "SPN" SG_ 2364545534 EngCyl23KnockLevel 1374;
BA_ "SigType" SG_ 2364545534 EngCyl22KnockLevel "RANGE";
BA_ "SPN" SG_ 2364545534 EngCyl22KnockLevel 1373;
BA_ "SigType" SG_ 2364545534 EngCyl21KnockLevel "RANGE";
BA_ "SPN" SG_ 2364545534 EngCyl21KnockLevel 1372;
BA_ "SigType" SG_ 2364545534 EngCyl20KnockLevel "RANGE";
BA_ "SPN" SG_ 2364545534 EngCyl20KnockLevel 1371;
BA_ "SigType" SG_ 2364545534 EngCyl19KnockLevel "RANGE";
BA_ "SPN" SG_ 2364545534 EngCyl19KnockLevel 1370;
BA_ "SigType" SG_ 2364545534 EngCyl18KnockLevel "RANGE";
BA_ "SPN" SG_ 2364545534 EngCyl18KnockLevel 1369;
BA_ "SigType" SG_ 2364545534 EngCyl17KnockLevel "RANGE";
BA_ "SPN" SG_ 2364545534 EngCyl17KnockLevel 1368;
BA_ "SigType" SG_ 2364545278 EngCyl15KnockLevel "RANGE";
BA_ "SPN" SG_ 2364545278 EngCyl15KnockLevel 1366;
BA_ "SigType" SG_ 2364545278 EngCyl14KnockLevel "RANGE";
BA_ "SPN" SG_ 2364545278 EngCyl14KnockLevel 1365;
BA_ "SigType" SG_ 2364545278 EngCyl13KnockLevel "RANGE";
BA_ "SPN" SG_ 2364545278 EngCyl13KnockLevel 1364;
BA_ "SigType" SG_ 2364545278 EngCyl12KnockLevel "RANGE";
BA_ "SPN" SG_ 2364545278 EngCyl12KnockLevel 1363;
BA_ "SigType" SG_ 2364545278 EngCyl11KnockLevel "RANGE";
BA_ "SPN" SG_ 2364545278 EngCyl11KnockLevel 1362;
BA_ "SigType" SG_ 2364545278 EngCyl10KnockLevel "RANGE";
BA_ "SPN" SG_ 2364545278 EngCyl10KnockLevel 1361;
BA_ "SigType" SG_ 2364545278 EngCyl9KnockLevel "RANGE";
BA_ "SPN" SG_ 2364545278 EngCyl9KnockLevel 1360;
BA_ "SigType" SG_ 2364545278 EngCyl16KnockLevel "RANGE";
BA_ "SPN" SG_ 2364545278 EngCyl16KnockLevel 1367;
BA_ "SigType" SG_ 2364545022 EngCyl8KnockLevel "RANGE";
BA_ "SPN" SG_ 2364545022 EngCyl8KnockLevel 1359;
BA_ "SigType" SG_ 2364545022 EngCyl7KnockLevel "RANGE";
BA_ "SPN" SG_ 2364545022 EngCyl7KnockLevel 1358;
BA_ "SigType" SG_ 2364545022 EngCyl6KnockLevel "RANGE";
BA_ "SPN" SG_ 2364545022 EngCyl6KnockLevel 1357;
BA_ "SigType" SG_ 2364545022 EngCyl5KnockLevel "RANGE";
BA_ "SPN" SG_ 2364545022 EngCyl5KnockLevel 1356;
BA_ "SigType" SG_ 2364545022 EngCyl4KnockLevel "RANGE";
BA_ "SPN" SG_ 2364545022 EngCyl4KnockLevel 1355;
BA_ "SigType" SG_ 2364545022 EngCyl3KnockLevel "RANGE";
BA_ "SPN" SG_ 2364545022 EngCyl3KnockLevel 1354;
BA_ "SigType" SG_ 2364545022 EngCyl2KnockLevel "RANGE";
BA_ "SPN" SG_ 2364545022 EngCyl2KnockLevel 1353;
BA_ "SigType" SG_ 2364545022 EngCyl1KnockLevel "RANGE";
BA_ "SPN" SG_ 2364545022 EngCyl1KnockLevel 1352;
BA_ "SigType" SG_ 2364544766 EngCyl9CombustionStatus "DISCRETE";
BA_ "SPN" SG_ 2364544766 EngCyl9CombustionStatus 3395;
BA_ "SigType" SG_ 2364544766 EngCyl8CombustionStatus "DISCRETE";
BA_ "SPN" SG_ 2364544766 EngCyl8CombustionStatus 3394;
BA_ "SigType" SG_ 2364544766 EngCyl7CombustionStatus "DISCRETE";
BA_ "SPN" SG_ 2364544766 EngCyl7CombustionStatus 3393;
BA_ "SigType" SG_ 2364544766 EngCyl6CombustionStatus "DISCRETE";
BA_ "SPN" SG_ 2364544766 EngCyl6CombustionStatus 3392;
BA_ "SigType" SG_ 2364544766 EngCyl5CombustionStatus "DISCRETE";
BA_ "SPN" SG_ 2364544766 EngCyl5CombustionStatus 3391;
BA_ "SigType" SG_ 2364544766 EngCyl4CombustionStatus "DISCRETE";
BA_ "SPN" SG_ 2364544766 EngCyl4CombustionStatus 3390;
BA_ "SigType" SG_ 2364544766 EngCyl3CombustionStatus "DISCRETE";
BA_ "SPN" SG_ 2364544766 EngCyl3CombustionStatus 3389;
BA_ "SigType" SG_ 2364544766 EngCyl2CombustionStatus "DISCRETE";
BA_ "SPN" SG_ 2364544766 EngCyl2CombustionStatus 3388;
BA_ "SigType" SG_ 2364544766 EngCyl24CombustionStatus "DISCRETE";
BA_ "SPN" SG_ 2364544766 EngCyl24CombustionStatus 3410;
BA_ "SigType" SG_ 2364544766 EngCyl23CombustionStatus "DISCRETE";
BA_ "SPN" SG_ 2364544766 EngCyl23CombustionStatus 3409;
BA_ "SigType" SG_ 2364544766 EngCyl22CombustionStatus "DISCRETE";
BA_ "SPN" SG_ 2364544766 EngCyl22CombustionStatus 3408;
BA_ "SigType" SG_ 2364544766 EngCyl21CombustionStatus "DISCRETE";
BA_ "SPN" SG_ 2364544766 EngCyl21CombustionStatus 3407;
BA_ "SigType" SG_ 2364544766 EngCyl20CombustionStatus "DISCRETE";
BA_ "SPN" SG_ 2364544766 EngCyl20CombustionStatus 3406;
BA_ "SigType" SG_ 2364544766 EngCyl1CombustionStatus "DISCRETE";
BA_ "SPN" SG_ 2364544766 EngCyl1CombustionStatus 3387;
BA_ "SigType" SG_ 2364544766 EngCyl19CombustionStatus "DISCRETE";
BA_ "SPN" SG_ 2364544766 EngCyl19CombustionStatus 3405;
BA_ "SigType" SG_ 2364544766 EngCyl18CombustionStatus "DISCRETE";
BA_ "SPN" SG_ 2364544766 EngCyl18CombustionStatus 3404;
BA_ "SigType" SG_ 2364544766 EngCyl17CombustionStatus "DISCRETE";
BA_ "SPN" SG_ 2364544766 EngCyl17CombustionStatus 3403;
BA_ "SigType" SG_ 2364544766 EngCyl16CombustionStatus "DISCRETE";
BA_ "SPN" SG_ 2364544766 EngCyl16CombustionStatus 3402;
BA_ "SigType" SG_ 2364544766 EngCyl15CombustionStatus "DISCRETE";
BA_ "SPN" SG_ 2364544766 EngCyl15CombustionStatus 3401;
BA_ "SigType" SG_ 2364544766 EngCyl14CombustionStatus "DISCRETE";
BA_ "SPN" SG_ 2364544766 EngCyl14CombustionStatus 3400;
BA_ "SigType" SG_ 2364544766 EngCyl13CombustionStatus "DISCRETE";
BA_ "SPN" SG_ 2364544766 EngCyl13CombustionStatus 3399;
BA_ "SigType" SG_ 2364544766 EngCyl12CombustionStatus "DISCRETE";
BA_ "SPN" SG_ 2364544766 EngCyl12CombustionStatus 3398;
BA_ "SigType" SG_ 2364544766 EngCyl11CombustionStatus "DISCRETE";
BA_ "SPN" SG_ 2364544766 EngCyl11CombustionStatus 3397;
BA_ "SigType" SG_ 2364544766 EngCyl10CombustionStatus "DISCRETE";
BA_ "SPN" SG_ 2364544766 EngCyl10CombustionStatus 3396;
BA_ "SigType" SG_ 2364544510 RqGenOverallPowerFactorLagging "DISCRETE";
BA_ "SPN" SG_ 2364544510 RqGenOverallPowerFactorLagging 3385;
BA_ "SigType" SG_ 2364544510 RqGeneratorOverallPowerFactor "RANGE";
BA_ "SPN" SG_ 2364544510 RqGeneratorOverallPowerFactor 3384;
BA_ "SigType" SG_ 2364544510 RqGeneratorTotalACReactivePower "RANGE";
BA_ "SPN" SG_ 2364544510 RqGeneratorTotalACReactivePower 3383;
BA_ "SigType" SG_ 2364544254 BladeRotationAngleFigureOfMerit "DISCRETE";
BA_ "SPN" SG_ 2364544254 BladeRotationAngleFigureOfMerit 3332;
BA_ "SigType" SG_ 2364544254 RelBladeHeightFigureOfMerit "DISCRETE";
BA_ "SPN" SG_ 2364544254 RelBladeHeightFigureOfMerit 3367;
BA_ "SigType" SG_ 2364544254 RelBladeMeasurementLatency "RANGE";
BA_ "SPN" SG_ 2364544254 RelBladeMeasurementLatency 3366;
BA_ "SigType" SG_ 2364544254 BladeRotationAngle "RANGE";
BA_ "SPN" SG_ 2364544254 BladeRotationAngle 3331;
BA_ "SigType" SG_ 2364544254 RelativeBladeHeight "RANGE";
BA_ "SPN" SG_ 2364544254 RelativeBladeHeight 3365;
BA_ "SigType" SG_ 2566834686 RoadCurvature "RANGE";
BA_ "SPN" SG_ 2566834686 RoadCurvature 1591;
BA_ "SigType" SG_ 2550398718 ActualRetarderPercTorque "RANGE";
BA_ "SigType" SG_ 2550398718 Wheel_BasedVehicleSpeed "RANGE";
BA_ "SigType" SG_ 2566833406 ReferenceRetarderTorque "RANGE";
BA_ "SPN" SG_ 2566833406 ReferenceRetarderTorque 556;
BA_ "SigType" SG_ 2566807038 MaxVehicleSpeedLimit "RANGE";
BA_ "SPN" SG_ 2566807038 MaxVehicleSpeedLimit 74;
BA_ "SigType" SG_ 2365480958 EngineTorqueMode "DISCRETE";
BA_ "SigType" SG_ 2365480958 VehicleSpeed "RANGE";
BA_ "SigType" SG_ 2365480958 PercentLoadAtCurrentSpeed "RANGE";
BA_ "SigType" SG_ 2365480958 EngineSpeed "RANGE";
BA_ "SigType" SG_ 2365480958 ActualEngine_PercTorque "RANGE";
BA_ "SigType" SG_ 2365480958 DriversDemandEngine_PercTorque "RANGE";
BA_ "SigType" SG_ 2566808062 AccelPedalPosition "RANGE";
BA_ "SigType" SG_ 2566808062 CurrentGear "RANGE";
BA_ "SigType" SG_ 2566808062 PercentClutchSlip "RANGE";
BA_ "SPN" SG_ 2566808062 PercentClutchSlip 522;
BA_ "SigType" SG_ 2566808574 ReferenceEngineTorque "RANGE";
BA_ "SigType" SG_ 2566808574 EngineOilPressure "RANGE";
BA_ "SigType" SG_ 2566808574 EngineCoolantTemperature "RANGE";
BA_ "SPN" SG_ 2566808574 EngineCoolantTemperature 110;
BA_ "SigType" SG_ 2566808574 EngineOilTemperature "RANGE";
BA_ "SigType" SG_ 2566809086 AmbientAirTemperature "RANGE";
BA_ "SigType" SG_ 2566808318 RqstedPercentClutchSlip "RANGE";
BA_ "SigType" SG_ 2565734142 ControlByte "RANGE";
BA_ "SigType" SG_ 2565734142 FilterMode "RANGE";
BA_ "SigType" SG_ 2565734142 ToPort "DISCRETE";
BA_ "SigType" SG_ 2565734142 FromPort "DISCRETE";
BA_ "SigType" SG_ 2565144318 ParkingAndTrailerAirPress "RANGE";
BA_ "SigType" SG_ 2565144318 AuxEquipSupplyPressure "RANGE";
BA_ "SigType" SG_ 2565144318 LiftAxle1PositionReq "DISCRETE";
BA_ "SigType" SG_ 2565209854 LiftAxle2Pos "DISCRETE";
BA_ "SPN" SG_ 2565209854 LiftAxle2Pos 1822;
BA_ "SigType" SG_ 2565209854 LiftAxle1Pos "DISCRETE";
BA_ "SPN" SG_ 2565209854 LiftAxle1Pos 1743;
BA_ "SPN" SG_ 2566764798 MisfireMonitoringComplete 3152;
BA_ "SPN" SG_ 2566764798 MisfireMonitoringEnabled 3152;
BA_ "SPN" SG_ 2566764798 FuelSystemMonitoringEnabled 3152;
BA_ "SPN" SG_ 2566764798 ComprehensiveComptMonComplete 3152;
BA_ "SPN" SG_ 2566764798 ComprehensiveCompMonEnabled 3152;
BA_ "SPN" SG_ 2566764798 SecondAirSystemMonComplete 3153;
BA_ "SPN" SG_ 2566764798 SecondAirSystemMonEnabled 3153;
BA_ "SPN" SG_ 2566764798 OxygenSensorMonComplete 3154;
BA_ "SPN" SG_ 2566764798 OxygenSensorMonEnabled 3153;
BA_ "SPN" SG_ 2566764798 OxygenSensorHeaterMonComplete 3154;
BA_ "SPN" SG_ 2566764798 OxygenSensorHeaterMonEnabled 3153;
BA_ "SPN" SG_ 2566764798 HeatedCatalystMonComplete 3154;
BA_ "SPN" SG_ 2566764798 HeatedCatalystMonEnabled 3153;
BA_ "SPN" SG_ 2566764798 EvaporativeSystemMonComplete 3154;
BA_ "SPN" SG_ 2566764798 EvaporativeSystemMonEnabled 3153;
BA_ "SPN" SG_ 2566764798 EGRSystemMonitoringComplete 3154;
BA_ "SPN" SG_ 2566764798 EGRSystemMonitoringEnabled 3153;
BA_ "SPN" SG_ 2566764798 ColdStartAidSystemMonComplete 3154;
BA_ "SPN" SG_ 2566764798 ColdStartAidSystemMonEnabled 3153;
BA_ "SPN" SG_ 2566764798 CatalystMonComplete 3153;
BA_ "SPN" SG_ 2566764798 CatalystMonEnabled 3153;
BA_ "SPN" SG_ 2566764798 ACSystemRefrigerantMonComplete 3153;
BA_ "SPN" SG_ 2566764798 ACSystemRefrigerantMonEnabled 3153;
BA_ "SPN" SG_ 2566764798 FuelSystemMonitoringComplete 3152;
BA_ "SPN" SG_ 2566764798 NumOfWarmUpsSinceDTCsCleared 3151;
BA_ "SPN" SG_ 2566764798 TimeSinceEngineStart 3150;
BA_ "SPN" SG_ 2564095742 SecurityEntityLengthHigh 1596;
BA_ "SPN" SG_ 2564095742 SecurityEntityType 1479;
BA_ "SPN" SG_ 2564095742 SecurityEntityLength 1596;
BA_ "SigType" SG_ 2349137662 XBRMessageChecksum "DISCRETE";
BA_ "SPN" SG_ 2349137662 XBRMessageChecksum 3188;
BA_ "SigType" SG_ 2349137662 XBRMessageCounter "DISCRETE";
BA_ "SPN" SG_ 2349137662 XBRMessageCounter 3189;
BA_ "SigType" SG_ 2349137662 XBRCtrlMode "DISCRETE";
BA_ "SPN" SG_ 2349137662 XBRCtrlMode 2916;
BA_ "SigType" SG_ 2349137662 XBRPriority "DISCRETE";
BA_ "SPN" SG_ 2349137662 XBRPriority 2915;
BA_ "SigType" SG_ 2349137662 XBREBIMode "DISCRETE";
BA_ "SPN" SG_ 2349137662 XBREBIMode 2914;
BA_ "SigType" SG_ 2349137662 ExtlAccelerationDemand "RANGE";
BA_ "SPN" SG_ 2349137662 ExtlAccelerationDemand 2920;
BA_ "SigType" SG_ 2566848510 WaterInFuelIndicator "DISCRETE";
BA_ "SPN" SG_ 2566848510 WaterInFuelIndicator 97;
BA_ "SigType" SG_ 2566843134 CargoWeight "RANGE";
BA_ "SPN" SG_ 2566843134 CargoWeight 181;
BA_ "SigType" SG_ 2566843134 TrailerWeight "RANGE";
BA_ "SPN" SG_ 2566843134 TrailerWeight 180;
BA_ "SigType" SG_ 2566843134 AxleWeight "RANGE";
BA_ "SPN" SG_ 2566843134 AxleWeight 582;
BA_ "SigType" SG_ 2566843134 AxleLocation "RANGE";
BA_ "SPN" SG_ 2566843134 AxleLocation 2928;
BA_ "SigType" SG_ 2566804222 NetBatteryCurrentHiRes "RANGE";
BA_ "SPN" SG_ 2566804222 NetBatteryCurrentHiRes 2579;
BA_ "SigType" SG_ 2566804222 AltCurrentHiRes "RANGE";
BA_ "SPN" SG_ 2566804222 AltCurrentHiRes 1795;
BA_ "SigType" SG_ 2633928190 Battery2Potential "RANGE";
BA_ "SPN" SG_ 2633928190 Battery2Potential 444;
BA_ "SigType" SG_ 2566845438 Longitude "RANGE";
BA_ "SPN" SG_ 2566845438 Longitude 585;
BA_ "SigType" SG_ 2566845438 Latitude "RANGE";
BA_ "SPN" SG_ 2566845438 Latitude 584;
BA_ "SigType" SG_ 2566842366 TotalPowerTakeoffHours "RANGE";
BA_ "SPN" SG_ 2566842366 TotalPowerTakeoffHours 248;
BA_ "SigType" SG_ 2566842366 TotalVehicleHours "RANGE";
BA_ "SPN" SG_ 2566842366 TotalVehicleHours 246;
BA_ "SigType" SG_ 2566809854 WinchOilPressSwitch "DISCRETE";
BA_ "SPN" SG_ 2566809854 WinchOilPressSwitch 1857;
BA_ "SigType" SG_ 2566809854 HydOilLevel "RANGE";
BA_ "SPN" SG_ 2566809854 HydOilLevel 2602;
BA_ "SigType" SG_ 2566809854 HydOilFilterRestrictionSwitch "DISCRETE";
BA_ "SPN" SG_ 2566809854 HydOilFilterRestrictionSwitch 1713;
BA_ "SigType" SG_ 2566809854 HydTemp "RANGE";
BA_ "SPN" SG_ 2566809854 HydTemp 1638;
BA_ "SigType" SG_ 2566842622 Altitude "RANGE";
BA_ "SPN" SG_ 2566842622 Altitude 580;
BA_ "SigType" SG_ 2566842622 Pitch "RANGE";
BA_ "SPN" SG_ 2566842622 Pitch 583;
BA_ "SigType" SG_ 2566842622 NavigationBasedVehicleSpeed "RANGE";
BA_ "SPN" SG_ 2566842622 NavigationBasedVehicleSpeed 517;
BA_ "SigType" SG_ 2566842622 CompassBearing "RANGE";
BA_ "SPN" SG_ 2566842622 CompassBearing 165;
BA_ "SigType" SG_ 2566832638 HighResolutionTripDistance "RANGE";
BA_ "SPN" SG_ 2566832638 HighResolutionTripDistance 918;
BA_ "SigType" SG_ 2566832638 HghRslutionTotalVehicleDistance "RANGE";
BA_ "SPN" SG_ 2566832638 HghRslutionTotalVehicleDistance 917;
BA_ "SigType" SG_ 2565868030 LongitudinalAcceleration "RANGE";
BA_ "SPN" SG_ 2565868030 LongitudinalAcceleration 1810;
BA_ "SigType" SG_ 2565868030 LateralAcceleration "RANGE";
BA_ "SPN" SG_ 2565868030 LateralAcceleration 1809;
BA_ "SigType" SG_ 2565868030 YawRate "RANGE";
BA_ "SPN" SG_ 2565868030 YawRate 1808;
BA_ "SigType" SG_ 2565868030 SteerWheelAngleSensorType "DISCRETE";
BA_ "SPN" SG_ 2565868030 SteerWheelAngleSensorType 1812;
BA_ "SigType" SG_ 2565868030 SteerWheelTurnCounter "DISCRETE";
BA_ "SPN" SG_ 2565868030 SteerWheelTurnCounter 1811;
BA_ "SigType" SG_ 2565868030 SteerWheelAngle "RANGE";
BA_ "SPN" SG_ 2565868030 SteerWheelAngle 1807;
BA_ "SigType" SG_ 2566803454 YCBrakeCtrlActive "DISCRETE";
BA_ "SPN" SG_ 2566803454 YCBrakeCtrlActive 1819;
BA_ "SigType" SG_ 2566803454 YCEngCtrlActive "DISCRETE";
BA_ "SPN" SG_ 2566803454 YCEngCtrlActive 1817;
BA_ "SigType" SG_ 2566803454 ROPBrakeCtrlActive "DISCRETE";
BA_ "SPN" SG_ 2566803454 ROPBrakeCtrlActive 1818;
BA_ "SigType" SG_ 2566803454 ROPEngCtrlActive "DISCRETE";
BA_ "SPN" SG_ 2566803454 ROPEngCtrlActive 1816;
BA_ "SigType" SG_ 2566803454 VDCBrakeLightRq "DISCRETE";
BA_ "SPN" SG_ 2566803454 VDCBrakeLightRq 1815;
BA_ "SigType" SG_ 2566803454 VDCFullyOperational "DISCRETE";
BA_ "SPN" SG_ 2566803454 VDCFullyOperational 1814;
BA_ "SigType" SG_ 2566803454 VDCInformationSignal "DISCRETE";
BA_ "SPN" SG_ 2566803454 VDCInformationSignal 1813;
BA_ "SigType" SG_ 2566840574 TotalVehicleDistance "RANGE";
BA_ "SPN" SG_ 2566840574 TotalVehicleDistance 245;
BA_ "SigType" SG_ 2566840574 TripDistance "RANGE";
BA_ "SPN" SG_ 2566840574 TripDistance 244;
BA_ "SigType" SG_ 2633938686 TripCruiseDistance "RANGE";
BA_ "SPN" SG_ 2633938686 TripCruiseDistance 1019;
BA_ "SigType" SG_ 2633938686 TripMaxVehicleSpeed "RANGE";
BA_ "SPN" SG_ 2633938686 TripMaxVehicleSpeed 1018;
BA_ "SigType" SG_ 2633937150 TripAirCompressorOnTime "RANGE";
BA_ "SPN" SG_ 2633937150 TripAirCompressorOnTime 1038;
BA_ "SigType" SG_ 2633937150 TripIdleTime "RANGE";
BA_ "SPN" SG_ 2633937150 TripIdleTime 1037;
BA_ "SigType" SG_ 2633937150 TripEngRunningTime "RANGE";
BA_ "SPN" SG_ 2633937150 TripEngRunningTime 1036;
BA_ "SigType" SG_ 2633937150 TripPTOTime "RANGE";
BA_ "SPN" SG_ 2633937150 TripPTOTime 1035;
BA_ "SigType" SG_ 2633937150 TripCruiseTime "RANGE";
BA_ "SPN" SG_ 2633937150 TripCruiseTime 1034;
BA_ "SigType" SG_ 2633938174 TripTimeInDerateByEng "RANGE";
BA_ "SPN" SG_ 2633938174 TripTimeInDerateByEng 1027;
BA_ "SigType" SG_ 2633938174 TripTimeInGearDown "RANGE";
BA_ "SPN" SG_ 2633938174 TripTimeInGearDown 1026;
BA_ "SigType" SG_ 2633938174 TripTimeInTopGear "RANGE";
BA_ "SPN" SG_ 2633938174 TripTimeInTopGear 1025;
BA_ "SigType" SG_ 2633938174 TripTimeInVSL "RANGE";
BA_ "SPN" SG_ 2633938174 TripTimeInVSL 1024;
BA_ "SigType" SG_ 2633938430 TripSuddenDecelerations "RANGE";
BA_ "SPN" SG_ 2633938430 TripSuddenDecelerations 1023;
BA_ "SigType" SG_ 2633938430 TrpNmberOfIdleShutdownOverrides "RANGE";
BA_ "SPN" SG_ 2633938430 TrpNmberOfIdleShutdownOverrides 1022;
BA_ "SigType" SG_ 2633938430 TripNumberOfIdleShutdowns "RANGE";
BA_ "SPN" SG_ 2633938430 TripNumberOfIdleShutdowns 1021;
BA_ "SigType" SG_ 2633938430 TripNumberOfHotShutdowns "RANGE";
BA_ "SPN" SG_ 2633938430 TripNumberOfHotShutdowns 1020;
BA_ "SigType" SG_ 2348875518 ControlPurpose "DISCRETE";
BA_ "SPN" SG_ 2348875518 ControlPurpose 3350;
BA_ "SigType" SG_ 2348875518 TransmissionRate "DISCRETE";
BA_ "SPN" SG_ 2348875518 TransmissionRate 3349;
BA_ "SigType" SG_ 2348875518 EngRqedTorque_TorqueLimit "RANGE";
BA_ "SPN" SG_ 2348875518 EngRqedTorque_TorqueLimit 518;
BA_ "SigType" SG_ 2348875518 EngRqedSpeed_SpeedLimit "RANGE";
BA_ "SPN" SG_ 2348875518 EngRqedSpeed_SpeedLimit 898;
BA_ "SigType" SG_ 2348875518 OverrideCtrlModePriority "DISCRETE";
BA_ "SPN" SG_ 2348875518 OverrideCtrlModePriority 897;
BA_ "SigType" SG_ 2348875518 EngRqedSpeedCtrlConditions "DISCRETE";
BA_ "SPN" SG_ 2348875518 EngRqedSpeedCtrlConditions 696;
BA_ "SigType" SG_ 2348875518 EngOverrideCtrlMode "DISCRETE";
BA_ "SPN" SG_ 2348875518 EngOverrideCtrlMode 695;
BA_ "SigType" SG_ 2566766846 TransitRunStatus "DISCRETE";
BA_ "SPN" SG_ 2566766846 TransitRunStatus 3046;
BA_ "SigType" SG_ 2566766846 VehicleUseStatus "DISCRETE";
BA_ "SPN" SG_ 2566766846 VehicleUseStatus 3045;
BA_ "SigType" SG_ 2566766846 SilentAlarmStatus "DISCRETE";
BA_ "SPN" SG_ 2566766846 SilentAlarmStatus 3044;
BA_ "SigType" SG_ 2566766846 PatronCount "RANGE";
BA_ "SPN" SG_ 2566766846 PatronCount 3047;
BA_ "SigType" SG_ 2566766846 TypeOfPassengerCount "RANGE";
BA_ "SPN" SG_ 2566766846 TypeOfPassengerCount 3043;
BA_ "SigType" SG_ 2566765310 FareboxAlarmIdentifier "DISCRETE";
BA_ "SPN" SG_ 2566765310 FareboxAlarmIdentifier 3181;
BA_ "SigType" SG_ 2566765310 FareboxEmergencyStatus "DISCRETE";
BA_ "SPN" SG_ 2566765310 FareboxEmergencyStatus 3179;
BA_ "SigType" SG_ 2566765566 TransferSold "RANGE";
BA_ "SPN" SG_ 2566765566 TransferSold 3168;
BA_ "SigType" SG_ 2566765566 RouteNumber "RANGE";
BA_ "SPN" SG_ 2566765566 RouteNumber 3169;
BA_ "SigType" SG_ 2566765566 TransferType "DISCRETE";
BA_ "SPN" SG_ 2566765566 TransferType 3173;
BA_ "SigType" SG_ 2566765566 TypeOfService "DISCRETE";
BA_ "SPN" SG_ 2566765566 TypeOfService 3172;
BA_ "SigType" SG_ 2566765566 InitialFareAgency "DISCRETE";
BA_ "SPN" SG_ 2566765566 InitialFareAgency 3167;
BA_ "SigType" SG_ 2566765566 PassCategory "DISCRETE";
BA_ "SPN" SG_ 2566765566 PassCategory 3166;
BA_ "SigType" SG_ 2566765566 FareValidity "DISCRETE";
BA_ "SPN" SG_ 2566765566 FareValidity 3165;
BA_ "SigType" SG_ 2566765566 PaymentDetails "DISCRETE";
BA_ "SPN" SG_ 2566765566 PaymentDetails 3177;
BA_ "SigType" SG_ 2566765566 TypeOfFare "DISCRETE";
BA_ "SPN" SG_ 2566765566 TypeOfFare 3176;
BA_ "SigType" SG_ 2566765566 PassengerType "DISCRETE";
BA_ "SPN" SG_ 2566765566 PassengerType 3171;
BA_ "SigType" SG_ 2566765566 TransactionType "DISCRETE";
BA_ "SPN" SG_ 2566765566 TransactionType 3170;
BA_ "SigType" SG_ 2566765822 DriversFareboxSecurityCode "RANGE";
BA_ "SPN" SG_ 2566765822 DriversFareboxSecurityCode 3164;
BA_ "SigType" SG_ 2566765822 AssignedBlock "RANGE";
BA_ "SPN" SG_ 2566765822 AssignedBlock 3163;
BA_ "SigType" SG_ 2566765822 AssignedRun "RANGE";
BA_ "SPN" SG_ 2566765822 AssignedRun 3162;
BA_ "SigType" SG_ 2566765822 AssignedRoute "RANGE";
BA_ "SPN" SG_ 2566765822 AssignedRoute 3160;
BA_ "SigType" SG_ 2566765822 PatternNumber "RANGE";
BA_ "SPN" SG_ 2566765822 PatternNumber 3161;
BA_ "SigType" SG_ 2566765822 TripNumber "RANGE";
BA_ "SPN" SG_ 2566765822 TripNumber 3159;
BA_ "SigType" SG_ 2566765822 FarePresets "RANGE";
BA_ "SPN" SG_ 2566765822 FarePresets 3175;
BA_ "SigType" SG_ 2566765822 TripDirection "DISCRETE";
BA_ "SPN" SG_ 2566765822 TripDirection 3174;
BA_ "SigType" SG_ 2566765822 TripStatus "DISCRETE";
BA_ "SPN" SG_ 2566765822 TripStatus 3180;
BA_ "SigType" SG_ 2566765822 FareboxServiceStatus "DISCRETE";
BA_ "SPN" SG_ 2566765822 FareboxServiceStatus 3178;
BA_ "SigType" SG_ 2566766078 VehicleID "RANGE";
BA_ "SPN" SG_ 2566766078 VehicleID 3085;
BA_ "SigType" SG_ 2566766078 StrobeActivationCtrlStatus "DISCRETE";
BA_ "SPN" SG_ 2566766078 StrobeActivationCtrlStatus 3082;
BA_ "SigType" SG_ 2566766078 TransitDoorEnable "DISCRETE";
BA_ "SPN" SG_ 2566766078 TransitDoorEnable 3083;
BA_ "SigType" SG_ 2566766078 PriorityOfRespSentByEmitter "DISCRETE";
BA_ "SPN" SG_ 2566766078 PriorityOfRespSentByEmitter 3084;
BA_ "SigType" SG_ 2566766078 IntersectionPreemptionRq_Resp "DISCRETE";
BA_ "SPN" SG_ 2566766078 IntersectionPreemptionRq_Resp 3079;
BA_ "SigType" SG_ 2566766078 TransitRouteIDUsage "DISCRETE";
BA_ "SPN" SG_ 2566766078 TransitRouteIDUsage 3080;
BA_ "SigType" SG_ 2566766078 RangeCodeEnable "DISCRETE";
BA_ "SPN" SG_ 2566766078 RangeCodeEnable 3081;
BA_ "SigType" SG_ 2566766590 NmbrOfBytsInMlpstIdentification "RANGE";
BA_ "SPN" SG_ 2566766590 NmbrOfBytsInMlpstIdentification 3070;
BA_ "SigType" SG_ 2566766334 Agency "RANGE";
BA_ "SPN" SG_ 2566766334 Agency 3078;
BA_ "SigType" SG_ 2566766334 NmbrOfBytsInTrnstAssgndBlckIdntt "RANGE";
BA_ "SPN" SG_ 2566766334 NmbrOfBytsInTrnstAssgndBlckIdntt 3073;
BA_ "SigType" SG_ 2566766334 NmbrOfBytsInTrnstAssgndRnIdntty "RANGE";
BA_ "SPN" SG_ 2566766334 NmbrOfBytsInTrnstAssgndRnIdntty 3072;
BA_ "SigType" SG_ 2566766334 NmbrOfBytsInTrnstAssgndRtIdntty "RANGE";
BA_ "SPN" SG_ 2566766334 NmbrOfBytsInTrnstAssgndRtIdntty 3071;
BA_ "SigType" SG_ 2561605374 ReferenceTirePressSetting "RANGE";
BA_ "SPN" SG_ 2561605374 ReferenceTirePressSetting 3193;
BA_ "SigType" SG_ 2561605374 TireLocation "RANGE";
BA_ "SPN" SG_ 2561605374 TireLocation 929;
BA_ "SigType" SG_ 2566765054 ReferenceTirePress "RANGE";
BA_ "SPN" SG_ 2566765054 ReferenceTirePress 3191;
BA_ "SigType" SG_ 2566765054 TireLocation "RANGE";
BA_ "SPN" SG_ 2566765054 TireLocation 929;
BA_ "SigType" SG_ 2633923326 SteerChannelTirePress "RANGE";
BA_ "SPN" SG_ 2633923326 SteerChannelTirePress 146;
BA_ "SigType" SG_ 2633923326 DriveChannelTirePress "RANGE";
BA_ "SPN" SG_ 2633923326 DriveChannelTirePress 145;
BA_ "SigType" SG_ 2633923326 TrailerTagPushChannelTirePress "RANGE";
BA_ "SPN" SG_ 2633923326 TrailerTagPushChannelTirePress 144;
BA_ "SigType" SG_ 2633923070 SteerChannelTirePressTarget "RANGE";
BA_ "SPN" SG_ 2633923070 SteerChannelTirePressTarget 143;
BA_ "SigType" SG_ 2633923070 DriveChannelTirePressTarget "RANGE";
BA_ "SPN" SG_ 2633923070 DriveChannelTirePressTarget 142;
BA_ "SigType" SG_ 2633923070 TrlrTgPshChannelTirePressTarget "RANGE";
BA_ "SPN" SG_ 2633923070 TrlrTgPshChannelTirePressTarget 141;
BA_ "SigType" SG_ 2633922814 PCUSupplySolenoidStatus "DISCRETE";
BA_ "SPN" SG_ 2633922814 PCUSupplySolenoidStatus 1474;
BA_ "SigType" SG_ 2633922814 PCUCtrlSolenoidStatus "DISCRETE";
BA_ "SPN" SG_ 2633922814 PCUCtrlSolenoidStatus 1473;
BA_ "SigType" SG_ 2633922814 PCUDeflateSolenoidStatus "DISCRETE";
BA_ "SPN" SG_ 2633922814 PCUDeflateSolenoidStatus 1472;
BA_ "SigType" SG_ 2633922814 TirePressSupplySwitchStatus "DISCRETE";
BA_ "SPN" SG_ 2633922814 TirePressSupplySwitchStatus 1471;
BA_ "SigType" SG_ 2633922814 PCUSteerSolenoidStatus "DISCRETE";
BA_ "SPN" SG_ 2633922814 PCUSteerSolenoidStatus 1470;
BA_ "SigType" SG_ 2633922814 PCUDriveSolenoidStatus "DISCRETE";
BA_ "SPN" SG_ 2633922814 PCUDriveSolenoidStatus 1469;
BA_ "SigType" SG_ 2633922814 DriveChannelMode "DISCRETE";
BA_ "SPN" SG_ 2633922814 DriveChannelMode 1468;
BA_ "SigType" SG_ 2633922814 Trailer_TagChannelMode "DISCRETE";
BA_ "SPN" SG_ 2633922814 Trailer_TagChannelMode 1467;
BA_ "SigType" SG_ 2633922814 SteerChannelMode "DISCRETE";
BA_ "SPN" SG_ 2633922814 SteerChannelMode 1466;
BA_ "SigType" SG_ 2633922814 TirePressCheckInterval "RANGE";
BA_ "SPN" SG_ 2633922814 TirePressCheckInterval 39;
BA_ "SigType" SG_ 2633922814 PCUTrailerTagPushSolenoidStatus "DISCRETE";
BA_ "SPN" SG_ 2633922814 PCUTrailerTagPushSolenoidStatus 1475;
BA_ "SigType" SG_ 2566845694 TirePressThresholdDetection "DISCRETE";
BA_ "SPN" SG_ 2566845694 TirePressThresholdDetection 2587;
BA_ "SigType" SG_ 2566845694 TireAirLeakageRate "RANGE";
BA_ "SPN" SG_ 2566845694 TireAirLeakageRate 2586;
BA_ "SigType" SG_ 2566845694 CTIWheelEndElectricalFault "DISCRETE";
BA_ "SPN" SG_ 2566845694 CTIWheelEndElectricalFault 1697;
BA_ "SigType" SG_ 2566845694 CTITireStatus "DISCRETE";
BA_ "SPN" SG_ 2566845694 CTITireStatus 1698;
BA_ "SigType" SG_ 2566845694 CTIWheelSensorStatus "DISCRETE";
BA_ "SPN" SG_ 2566845694 CTIWheelSensorStatus 1699;
BA_ "SigType" SG_ 2566845694 TireTemp "RANGE";
BA_ "SPN" SG_ 2566845694 TireTemp 242;
BA_ "SigType" SG_ 2566845694 TirePress "RANGE";
BA_ "SPN" SG_ 2566845694 TirePress 241;
BA_ "SigType" SG_ 2566845694 TireLocation "RANGE";
BA_ "SPN" SG_ 2566845694 TireLocation 929;
BA_ "SigType" SG_ 2566805246 CatalystTankTemp "RANGE";
BA_ "SPN" SG_ 2566805246 CatalystTankTemp 3031;
BA_ "SigType" SG_ 2566805246 CatalystTankLevel "RANGE";
BA_ "SPN" SG_ 2566805246 CatalystTankLevel 1761;
BA_ "SigType" SG_ 2566805246 CatalystTankLevelPreliminaryFMI "DISCRETE";
BA_ "SPN" SG_ 2566805246 CatalystTankLevelPreliminaryFMI 3532;
BA_ "SigType" SG_ 2566805246 CatalystTankLevel2 "RANGE";
BA_ "SPN" SG_ 2566805246 CatalystTankLevel2 3517;
BA_ "SigType" SG_ 2633939966 TripFanOnTimeDueToAManualSwitch "RANGE";
BA_ "SPN" SG_ 2633939966 TripFanOnTimeDueToAManualSwitch 996;
BA_ "SigType" SG_ 2633939966 TripFanOnTime "RANGE";
BA_ "SPN" SG_ 2633939966 TripFanOnTime 994;
BA_ "SigType" SG_ 2633939966 TripFanOnTimeDueToA_CSystem "RANGE";
BA_ "SPN" SG_ 2633939966 TripFanOnTimeDueToA_CSystem 997;
BA_ "SigType" SG_ 2633939966 TripFanOnTimeDueToEngSystem "RANGE";
BA_ "SPN" SG_ 2633939966 TripFanOnTimeDueToEngSystem 995;
BA_ "SigType" SG_ 2633939710 TripDistanceInTopGear "RANGE";
BA_ "SPN" SG_ 2633939710 TripDistanceInTopGear 1000;
BA_ "SigType" SG_ 2633939710 TripGearDownDistance "RANGE";
BA_ "SPN" SG_ 2633939710 TripGearDownDistance 999;
BA_ "SigType" SG_ 2633939710 TripDistanceOnVSL "RANGE";
BA_ "SPN" SG_ 2633939710 TripDistanceOnVSL 998;
BA_ "SigType" SG_ 2564161278 AdjustLocalHourOffset "RANGE";
BA_ "SPN" SG_ 2564161278 AdjustLocalHourOffset 1610;
BA_ "SigType" SG_ 2564161278 AdjustLocalMinuteOffset "RANGE";
BA_ "SPN" SG_ 2564161278 AdjustLocalMinuteOffset 1609;
BA_ "SigType" SG_ 2564161278 AdjustYear "RANGE";
BA_ "SPN" SG_ 2564161278 AdjustYear 1608;
BA_ "SigType" SG_ 2564161278 AdjustDay "RANGE";
BA_ "SPN" SG_ 2564161278 AdjustDay 1607;
BA_ "SigType" SG_ 2564161278 AdjustMonth "RANGE";
BA_ "SPN" SG_ 2564161278 AdjustMonth 1606;
BA_ "SigType" SG_ 2564161278 AdjustHours "RANGE";
BA_ "SPN" SG_ 2564161278 AdjustHours 1605;
BA_ "SigType" SG_ 2564161278 AdjustMinutes "RANGE";
BA_ "SPN" SG_ 2564161278 AdjustMinutes 1604;
BA_ "SigType" SG_ 2564161278 AdjustSeconds "RANGE";
BA_ "SPN" SG_ 2564161278 AdjustSeconds 1603;
BA_ "SigType" SG_ 2566842110 LocalHourOffset "RANGE";
BA_ "SPN" SG_ 2566842110 LocalHourOffset 1602;
BA_ "SigType" SG_ 2566842110 LocalMinuteOffset "RANGE";
BA_ "SPN" SG_ 2566842110 LocalMinuteOffset 1601;
BA_ "SigType" SG_ 2566842110 Year "RANGE";
BA_ "SPN" SG_ 2566842110 Year 964;
BA_ "SigType" SG_ 2566842110 Day "RANGE";
BA_ "SPN" SG_ 2566842110 Day 962;
BA_ "SigType" SG_ 2566842110 Month "RANGE";
BA_ "SPN" SG_ 2566842110 Month 963;
BA_ "SigType" SG_ 2566842110 Hours "RANGE";
BA_ "SPN" SG_ 2566842110 Hours 961;
BA_ "SigType" SG_ 2566842110 Minutes "RANGE";
BA_ "SPN" SG_ 2566842110 Minutes 960;
BA_ "SigType" SG_ 2566842110 Seconds "RANGE";
BA_ "SPN" SG_ 2566842110 Seconds 959;
BA_ "SigType" SG_ 2566821630 EngTrbWstgtActuatorCtrlAirPress "RANGE";
BA_ "SPN" SG_ 2566821630 EngTrbWstgtActuatorCtrlAirPress 1192;
BA_ "SigType" SG_ 2566821630 EngTurbo4WastegateDrive "RANGE";
BA_ "SPN" SG_ 2566821630 EngTurbo4WastegateDrive 1191;
BA_ "SigType" SG_ 2566821630 EngTurbo3WastegateDrive "RANGE";
BA_ "SPN" SG_ 2566821630 EngTurbo3WastegateDrive 1190;
BA_ "SigType" SG_ 2566821630 EngTurbo2WastegateDrive "RANGE";
BA_ "SPN" SG_ 2566821630 EngTurbo2WastegateDrive 1189;
BA_ "SigType" SG_ 2566821630 EngTurbo1WastegateDrive "RANGE";
BA_ "SPN" SG_ 2566821630 EngTurbo1WastegateDrive 1188;
BA_ "SigType" SG_ 2365484286 TachographVehicleSpeed "RANGE";
BA_ "SPN" SG_ 2365484286 TachographVehicleSpeed 1624;
BA_ "SigType" SG_ 2365484286 TachographOutputShaftSpeed "RANGE";
BA_ "SPN" SG_ 2365484286 TachographOutputShaftSpeed 1623;
BA_ "SigType" SG_ 2365484286 DirectionIndicator "DISCRETE";
BA_ "SPN" SG_ 2365484286 DirectionIndicator 1619;
BA_ "SigType" SG_ 2365484286 TachographPerformance "DISCRETE";
BA_ "SPN" SG_ 2365484286 TachographPerformance 1620;
BA_ "SigType" SG_ 2365484286 HandlingInformation "DISCRETE";
BA_ "SPN" SG_ 2365484286 HandlingInformation 1621;
BA_ "SigType" SG_ 2365484286 SystemEvent "DISCRETE";
BA_ "SPN" SG_ 2365484286 SystemEvent 1622;
BA_ "SigType" SG_ 2365484286 DriverCardDriver2 "DISCRETE";
BA_ "SPN" SG_ 2365484286 DriverCardDriver2 1616;
BA_ "SigType" SG_ 2365484286 Driver2TimeRelatedStates "DISCRETE";
BA_ "SPN" SG_ 2365484286 Driver2TimeRelatedStates 1618;
BA_ "SigType" SG_ 2365484286 Overspeed "DISCRETE";
BA_ "SPN" SG_ 2365484286 Overspeed 1614;
BA_ "SigType" SG_ 2365484286 DriverCardDriver1 "DISCRETE";
BA_ "SPN" SG_ 2365484286 DriverCardDriver1 1615;
BA_ "SigType" SG_ 2365484286 Driver1TimeRelatedStates "DISCRETE";
BA_ "SPN" SG_ 2365484286 Driver1TimeRelatedStates 1617;
BA_ "SigType" SG_ 2365484286 DriveRecognize "DISCRETE";
BA_ "SPN" SG_ 2365484286 DriveRecognize 1611;
BA_ "SigType" SG_ 2365484286 Driver2WorkingState "DISCRETE";
BA_ "SPN" SG_ 2365484286 Driver2WorkingState 1613;
BA_ "SigType" SG_ 2365484286 Driver1WorkingState "DISCRETE";
BA_ "SPN" SG_ 2365484286 Driver1WorkingState 1612;
BA_ "SigType" SG_ 2566771710 EngTurbo4CompressorOutletTemp "RANGE";
BA_ "SPN" SG_ 2566771710 EngTurbo4CompressorOutletTemp 2801;
BA_ "SigType" SG_ 2566771710 EngTurbo3CompressorOutletTemp "RANGE";
BA_ "SPN" SG_ 2566771710 EngTurbo3CompressorOutletTemp 2800;
BA_ "SigType" SG_ 2566771710 EngTurbo2CompressorOutletTemp "RANGE";
BA_ "SPN" SG_ 2566771710 EngTurbo2CompressorOutletTemp 2799;
BA_ "SigType" SG_ 2566771710 EngTurbo1CompressorOutletTemp "RANGE";
BA_ "SPN" SG_ 2566771710 EngTurbo1CompressorOutletTemp 2629;
BA_ "SigType" SG_ 2566821886 EngTurbo4TurbineOutletTemp "RANGE";
BA_ "SPN" SG_ 2566821886 EngTurbo4TurbineOutletTemp 1187;
BA_ "SigType" SG_ 2566821886 EngTurbo3TurbineOutletTemp "RANGE";
BA_ "SPN" SG_ 2566821886 EngTurbo3TurbineOutletTemp 1186;
BA_ "SigType" SG_ 2566821886 EngTurbo2TurbineOutletTemp "RANGE";
BA_ "SPN" SG_ 2566821886 EngTurbo2TurbineOutletTemp 1185;
BA_ "SigType" SG_ 2566821886 EngTurbo1TurbineOutletTemp "RANGE";
BA_ "SPN" SG_ 2566821886 EngTurbo1TurbineOutletTemp 1184;
BA_ "SigType" SG_ 2566822142 EngTurbo4TurbineInletTemp "RANGE";
BA_ "SPN" SG_ 2566822142 EngTurbo4TurbineInletTemp 1183;
BA_ "SigType" SG_ 2566822142 EngTurbo3TurbineInletTemp "RANGE";
BA_ "SPN" SG_ 2566822142 EngTurbo3TurbineInletTemp 1182;
BA_ "SigType" SG_ 2566822142 EngTurbo2TurbineInletTemp "RANGE";
BA_ "SPN" SG_ 2566822142 EngTurbo2TurbineInletTemp 1181;
BA_ "SigType" SG_ 2566822142 EngTurbo1TurbineInletTemp "RANGE";
BA_ "SPN" SG_ 2566822142 EngTurbo1TurbineInletTemp 1180;
BA_ "SigType" SG_ 2566822398 EngTurbo4CompressorInletPress "RANGE";
BA_ "SPN" SG_ 2566822398 EngTurbo4CompressorInletPress 1179;
BA_ "SigType" SG_ 2566822398 EngTurbo3CompressorInletPress "RANGE";
BA_ "SPN" SG_ 2566822398 EngTurbo3CompressorInletPress 1178;
BA_ "SigType" SG_ 2566822398 EngTurbo2CompressorInletPress "RANGE";
BA_ "SPN" SG_ 2566822398 EngTurbo2CompressorInletPress 1177;
BA_ "SigType" SG_ 2566822398 EngTurbo1CompressorInletPress "RANGE";
BA_ "SPN" SG_ 2566822398 EngTurbo1CompressorInletPress 1176;
BA_ "SigType" SG_ 2566822654 EngTurbo4CompressorInletTemp "RANGE";
BA_ "SPN" SG_ 2566822654 EngTurbo4CompressorInletTemp 1175;
BA_ "SigType" SG_ 2566822654 EngTurbo3CompressorInletTemp "RANGE";
BA_ "SPN" SG_ 2566822654 EngTurbo3CompressorInletTemp 1174;
BA_ "SigType" SG_ 2566822654 EngTurbo2CompressorInletTemp "RANGE";
BA_ "SPN" SG_ 2566822654 EngTurbo2CompressorInletTemp 1173;
BA_ "SigType" SG_ 2566822654 EngTurbo1CompressorInletTemp "RANGE";
BA_ "SPN" SG_ 2566822654 EngTurbo1CompressorInletTemp 1172;
BA_ "SigType" SG_ 2633931774 EngTurbo4Speed "RANGE";
BA_ "SPN" SG_ 2633931774 EngTurbo4Speed 1171;
BA_ "SigType" SG_ 2633931774 EngTurbo3Speed "RANGE";
BA_ "SPN" SG_ 2633931774 EngTurbo3Speed 1170;
BA_ "SigType" SG_ 2633931774 EngTurbo2Speed "RANGE";
BA_ "SPN" SG_ 2633931774 EngTurbo2Speed 1169;
BA_ "SigType" SG_ 2633931774 EngTurboLubeOilPress2 "RANGE";
BA_ "SPN" SG_ 2633931774 EngTurboLubeOilPress2 1168;
BA_ "SigType" SG_ 2566802430 TransTorqueLimit "RANGE";
BA_ "SPN" SG_ 2566802430 TransTorqueLimit 1845;
BA_ "SigType" SG_ 2566841086 TransGearRatio "RANGE";
BA_ "SPN" SG_ 2566841086 TransGearRatio 581;
BA_ "SigType" SG_ 2566841086 NumberOfForwardGearRatios "RANGE";
BA_ "SPN" SG_ 2566841086 NumberOfForwardGearRatios 957;
BA_ "SigType" SG_ 2566841086 NumberOfReverseGearRatios "RANGE";
BA_ "SPN" SG_ 2566841086 NumberOfReverseGearRatios 958;
VAL_ 2566757374 CatalystReagentType 15 "NotAvailable" 14 "ErrrDtctdWthUrRgntTypeDetection" 13 "NtAblTDtrmneCatalystReagentType" 4 "to1100ReservedForSAEAssignment" 3 "CatalystReagentIsProper" 2 "CatalystReagentIsDiesel" 1 "CatalystReagentIsWater" 0 "CatalystReagentIsUrea" ;
VAL_ 2566758654 Aftrtratment2FuelEnableActuator 3 "notAvailable" 2 "reservedForSAEAssignment" 1 "active" 0 "notActive" ;
VAL_ 2566758654 Aftrtratment2RegenerationStatus 3 "notAvailable" 2 "reservedForSAEAssignment" 1 "active" 0 "notActive" ;
VAL_ 2566758654 Aftertreatment2Ignt 3 "notAvailable" 2 "reservedForSAEAssignment" 1 "active" 0 "notActive" ;
VAL_ 2566758910 Aftrtratment1FuelEnableActuator 3 "notAvailable" 2 "reservedForSAEAssignment" 1 "active" 0 "notActive" ;
VAL_ 2566758910 Aftrtratment1RegenerationStatus 3 "notAvailable" 2 "reservedForSAEAssignment" 1 "active" 0 "notActive" ;
VAL_ 2566758910 Aftertreatment1Ignt 3 "notAvailable" 2 "reservedForSAEAssignment" 1 "active" 0 "notActive" ;
VAL_ 2566758142 Aftrtreatment2AirEnableActuator 3 "notAvailable" 2 "reservedForSAEAssignment" 1 "active" 0 "notActive" ;
VAL_ 2566758142 Aftertreatment2PurgeAirActuator 3 "notAvailable" 2 "reservedForSAEAssignment" 1 "active" 0 "notActive" ;
VAL_ 2566758142 Aftrtrtmnt2AtmzationAirActuator 3 "notAvailable" 2 "reservedForSAEAssignment" 1 "active" 0 "notActive" ;
VAL_ 2566758142 Aftertreatment2AirSystemRelay 3 "notAvailable" 2 "reservedForSAEAssignment" 1 "active" 0 "notActive" ;
VAL_ 2566758398 Aftrtreatment1AirEnableActuator 3 "notAvailable" 2 "reservedForSAEAssignment" 1 "active" 0 "notActive" ;
VAL_ 2566758398 Aftertreatment1PurgeAirActuator 3 "notAvailable" 2 "reservedForSAEAssignment" 1 "active" 0 "notActive" ;
VAL_ 2566758398 Aftrtrtmnt1AtmzationAirActuator 3 "notAvailable" 2 "reservedForSAEAssignment" 1 "active" 0 "notActive" ;
VAL_ 2566758398 Aftertreatment1AirSystemRelay 3 "notAvailable" 2 "reservedForSAEAssignment" 1 "active" 0 "notActive" ;
VAL_ 2364544766 EngCyl9CombustionStatus 3 "NotAvailable" 2 "Error" 1 "CombustionExists" 0 "NoCombustion" ;
VAL_ 2364544766 EngCyl8CombustionStatus 3 "NotAvailable" 2 "Error" 1 "CombustionExists" 0 "NoCombustion" ;
VAL_ 2364544766 EngCyl7CombustionStatus 3 "NotAvailable" 2 "Error" 1 "CombustionExists" 0 "NoCombustion" ;
VAL_ 2364544766 EngCyl6CombustionStatus 3 "NotAvailable" 2 "Error" 1 "CombustionExists" 0 "NoCombustion" ;
VAL_ 2364544766 EngCyl5CombustionStatus 1 "CombustionExists" 0 "NoCombustion" 3 "NotAvailable" 2 "Error" ;
VAL_ 2364544766 EngCyl4CombustionStatus 3 "NotAvailable" 2 "Error" 1 "CombustionExists" 0 "NoCombustion" ;
VAL_ 2364544766 EngCyl3CombustionStatus 3 "NotAvailable" 2 "Error" 1 "CombustionExists" 0 "NoCombustion" ;
VAL_ 2364544766 EngCyl2CombustionStatus 3 "NotAvailable" 2 "Error" 1 "CombustionExists" 0 "NoCombustion" ;
VAL_ 2364544766 EngCyl24CombustionStatus 3 "NotAvailable" 2 "Error" 1 "CombustionExists" 0 "NoCombustion" ;
VAL_ 2364544766 EngCyl23CombustionStatus 3 "NotAvailable" 2 "Error" 1 "CombustionExists" 0 "NoCombustion" ;
VAL_ 2364544766 EngCyl22CombustionStatus 3 "NotAvailable" 2 "Error" 1 "CombustionExists" 0 "NoCombustion" ;
VAL_ 2364544766 EngCyl21CombustionStatus 3 "NotAvailable" 2 "Error" 1 "CombustionExists" 0 "NoCombustion" ;
VAL_ 2364544766 EngCyl20CombustionStatus 3 "NotAvailable" 2 "Error" 1 "CombustionExists" 0 "NoCombustion" ;
VAL_ 2364544766 EngCyl1CombustionStatus 3 "NotAvailable" 2 "Error" 1 "CombustionExists" 0 "NoCombustion" ;
VAL_ 2364544766 EngCyl19CombustionStatus 3 "NotAvailable" 2 "Error" 1 "CombustionExists" 0 "NoCombustion" ;
VAL_ 2364544766 EngCyl18CombustionStatus 3 "NotAvailable" 2 "Error" 1 "CombustionExists" 0 "NoCombustion" ;
VAL_ 2364544766 EngCyl17CombustionStatus 3 "NotAvailable" 2 "Error" 1 "CombustionExists" 0 "NoCombustion" ;
VAL_ 2364544766 EngCyl16CombustionStatus 3 "NotAvailable" 2 "Error" 1 "CombustionExists" 0 "NoCombustion" ;
VAL_ 2364544766 EngCyl15CombustionStatus 3 "NotAvailable" 2 "Error" 1 "CombustionExists" 0 "NoCombustion" ;
VAL_ 2364544766 EngCyl14CombustionStatus 3 "NotAvailable" 2 "Error" 1 "CombustionExists" 0 "NoCombustion" ;
VAL_ 2364544766 EngCyl13CombustionStatus 3 "NotAvailable" 2 "Error" 1 "CombustionExists" 0 "NoCombustion" ;
VAL_ 2364544766 EngCyl12CombustionStatus 3 "NotAvailable" 2 "Error" 1 "CombustionExists" 0 "NoCombustion" ;
VAL_ 2364544766 EngCyl11CombustionStatus 3 "NotAvailable" 2 "Error" 1 "CombustionExists" 0 "NoCombustion" ;
VAL_ 2364544766 EngCyl10CombustionStatus 3 "NotAvailable" 2 "Error" 1 "CombustionExists" 0 "NoCombustion" ;
VAL_ 2364544510 RqGenOverallPowerFactorLagging 3 "NotAvailable" 2 "Error" 1 "Lagging" 0 "Leading" ;
VAL_ 2364544254 BladeRotationAngleFigureOfMerit 3 "AngleNotAvailable" 2 "AngleFailed" 1 "AngleDegraded" 0 "AngleFullyFunctional" ;
VAL_ 2364544254 RelBladeHeightFigureOfMerit 3 "HeightNotAvailable" 2 "HeightFailed" 1 "HeightDegraded" 0 "HeightFullyFunctional" ;
VAL_ 2349006590 VehicleType 1 "Dolly axle" 0 "Towing or towed vehicle" ;
VAL_ 2349006590 BrakeLightSwitch 1 "Switch on" 0 "Switch off" ;
VAL_ 2349006590 ASREngineControlActive 3 "NotAvailable" 2 "Reserved" 1 "ASREngineControlActive" 0 "ASREngnCntrlPassiveButInstalled" ;
VAL_ 2349006590 ASRBreakControlActive 1 "Active" 0 "Passive, but installed" ;
VAL_ 2349006590 VehicleRetarderCtrlActive 1 "Active" 0 "Passive" ;
VAL_ 2349006590 VehicleABSActive 1 "Active" 0 "Passiv, but installed" ;
VAL_ 2566834686 PneumaticControlLine 1 "Towing veh with pn ctrl line" 0 "Towing veh without pn ctrl line" ;
VAL_ 2566834686 ABSOffroadRequest 1 "ABS off-road switch on" 0 "ABS off-road switch off" ;
VAL_ 2566834686 TwoElCircuitsBrakeDemand 1 "Two el. circuit brake available" 0 "One el. circuit brake available" ;
VAL_ 2566834686 VehicleRetarderCtrlActive 1 "Active" 0 "Passive" ;
VAL_ 2550398718 SupplyLineBrakingRequest 1 "Supply line braking request" 0 "No supply line braking request" ;
VAL_ 2550398718 VDCActive 1 "Active" 0 "Passive, but installed" ;
VAL_ 2550398718 AutomTowedVehBreakActive 1 "Active" 0 "Passive" ;
VAL_ 2550398718 VehicleServiceBrakeActive 1 "Active" 0 "Passive" ;
VAL_ 2550398718 VehicleRetarderCtrlActive 1 "Active" 0 "Passive" ;
VAL_ 2550398718 VehicleABSActive 1 "Active" 0 "Passiv, but installed" ;
VAL_ 2566833406 SupplyLineBrakingRequest 1 "Supply line braking request" 0 "No supply line braking request" ;
VAL_ 2566833406 LoadingRampApproachAssist 1 "Assistance active" 0 "Assistance not active" ;
VAL_ 2566833406 SpringBrakeEngaged 1 "Vehicle spring brake is engaged" 0 "Vehicle spring brake is released" ;
VAL_ 2566833406 ElectrLoadPropFunc 1 "Vehicle with el. load proportion" 0 "Vehicle without el. load proport" ;
VAL_ 2566833406 SpringBrakeInstalled 1 "Vehicle with spring brakes" 0 "Vehicle without spring brakes" ;
VAL_ 2566833406 VehicleType 1 "Dolly axle" 0 "Towing or towed vehicle" ;
VAL_ 2566833406 ElecSupplyOfNonBrakingSys 1 "Supply switched on" 0 "Supply switched off" ;
VAL_ 2566833406 AmberWarningSignalReq 1 "Towed vehicle failure indicated" 0 "No towed vehicle failure indicat" ;
VAL_ 2566833406 RedWarningSignalRequest 1 "Towed vehicle failure indicated" 0 "No towed vehicle failure indicat" ;
VAL_ 2566833406 VehicleElectrSupplySuff 1 "Vehicle el. supply sufficient" 0 "Vehicle el. supply insufficient" ;
VAL_ 2566833406 AutomTowedVehBreakActive 1 "Active" 0 "Passive" ;
VAL_ 2566833406 VehicleServiceBrakeActive 1 "Active" 0 "Passive" ;
VAL_ 2566833406 VehicleRetarderCtrlActive 1 "Active" 0 "Passive" ;
VAL_ 2566833406 VehicleABSActive 1 "Active" 0 "Passiv, but installed" ;
VAL_ 2365507326 TyreWheelIdentTemp2 15 "Axle position 15" 14 "Axle position 14" 13 "Axle position 13" 12 "Axle position 12" 11 "Axle position 11" 10 "Axle position 10" 9 "Axle position 9" 8 "Axle position 8" 7 "Axle position 7" 6 "Axle position 6" 5 "Axle position 5" 4 "Axle position 4" 3 "Axle position 3" 2 "Axle position 2" 1 "Axle position 1" 0 "Axle position not identified" ;
VAL_ 2365507326 TyreWheelIdentTemp1 15 "Wheel position 15" 14 "Wheel position 14" 13 "Wheel position 13" 12 "Wheel position 12" 11 "Wheel position 11" 10 "Wheel position 10" 9 "Wheel position 9" 8 "Wheel position 8" 7 "Wheel position 7" 6 "Wheel position 6" 5 "Wheel position 5" 4 "Wheel position 4" 3 "Wheel position 3" 2 "Wheel position 2" 1 "Wheel position 1" 0 "Wheel position not identified" ;
VAL_ 2365507326 TyreWheelIdentPressure2 15 "Axle position 15" 14 "Axle position 14" 13 "Axle position 13" 12 "Axle position 12" 11 "Axle position 11" 10 "Axle position 10" 9 "Axle position 9" 8 "Axle position 8" 7 "Axle position 7" 6 "Axle position 6" 5 "Axle position 5" 4 "Axle position 4" 3 "Axle position 3" 2 "Axle position 2" 1 "Axle position 1" 0 "Axle position not identified" ;
VAL_ 2365507326 TyreWheelIdentPressure1 15 "Wheel position 15" 14 "Wheel position 14" 13 "Wheel position 13" 12 "Wheel position 12" 11 "Wheel position 11" 10 "Wheel position 10" 9 "Wheel position 9" 8 "Wheel position 8" 7 "Wheel position 7" 6 "Wheel position 6" 5 "Wheel position 5" 4 "Wheel position 4" 3 "Wheel position 3" 2 "Wheel position 2" 1 "Wheel position 1" 0 "Wheel position not identified" ;
VAL_ 2365507326 TyreWheelIdentLining2 15 "Axle position 15" 14 "Axle position 14" 13 "Axle position 13" 12 "Axle position 12" 11 "Axle position 11" 10 "Axle position 10" 9 "Axle position 9" 8 "Axle position 8" 7 "Axle position 7" 6 "Axle position 6" 5 "Axle position 5" 4 "Axle position 4" 3 "Axle position 3" 2 "Axle position 2" 1 "Axle position 1" 0 "Axle position not identified" ;
VAL_ 2365507326 TyreWheelIdentLining1 15 "Wheel position 15" 14 "Wheel position 14" 13 "Wheel position 13" 12 "Wheel position 12" 11 "Wheel position 11" 10 "Wheel position 10" 9 "Wheel position 9" 8 "Wheel position 8" 7 "Wheel position 7" 6 "Wheel position 6" 5 "Wheel position 5" 4 "Wheel position 4" 3 "Wheel position 3" 2 "Wheel position 2" 1 "Wheel position 1" 0 "Wheel position not identified" ;
VAL_ 2365507326 VehiclePneumSupplySuff 1 "Pneumatic supply sufficient" 0 "Pneumatic supply insufficient" ;
VAL_ 2365507326 BrakeTemperatureStatus 1 "Brake temperature normal" 0 "Brake temperature out of range" ;
VAL_ 2365507326 BrakeLiningSufficient 1 "Brake linings sufficient" 0 "Brake linings insufficient" ;
VAL_ 2365507326 TyrePressureSufficient 1 "Tyre pressure sufficient" 0 "Tyre pressure insufficient" ;
VAL_ 2565013246 ODDRequest 3 "Take no action" 1 "ODD on" 0 "ODD off" ;
VAL_ 2565013246 AntiTheftDeviceReq 3 "Take no action" 1 "Anti-theft device on" 0 "Anti-theft device off" ;
VAL_ 2565013246 VehicleType 1 "Dolly axle" 0 "Towing or towed vehicle" ;
VAL_ 2365480958 EngineTorqueMode 15 "Not available" 11 "Remote accelerator" 10 "Braking system" 9 "High speed governor" 8 "Torque limiting" 7 "ABS control" 6 "Transmission control" 5 "ASR control" 4 "Road speed governor" 3 "PTO governor" 2 "Cruise control" 1 "Accelerator pedal/operator selec" 0 "Low idle governor/no request (de" ;
VAL_ 2365480958 EngineRunning 1 "Engine running" 0 "Engine not running" ;
VAL_ 2365480958 EngineControlAllowed 1 "Engine control allowed" 0 "Engine control not allowed" ;
VAL_ 2566808062 ClutchIndptdPTOFeedback 1 "Engaged" 0 "Not engaged" ;
VAL_ 2566808062 AccelPedalLowIdleSwitch 1 "In low idle condition" 0 "Not in low idle condition" ;
VAL_ 2566808062 StarterActive 1 "Starter active" 0 "Starter not active" ;
VAL_ 2566808062 TorqueConvtOilTempWarning 2 "Warning" 1 "Prewarning" 0 "No warning" ;
VAL_ 2566808062 PTOControlAllowed 1 "PTO control allowed" 0 "PTO control not allowed" ;
VAL_ 2566808062 SecEngineMtdPTOFeedback 1 "Limits activated" 0 "Limits not activated" ;
VAL_ 2566808062 FirstEngineMtdPTOFeedback 1 "Limits activated" 0 "Limits not activated" ;
VAL_ 2566808062 SecClutchDptdPTOFeedback 1 "Engaged" 0 "Not engaged" ;
VAL_ 2566808062 FirstClutchDpdtPTOFeedback 1 "Engaged" 0 "Not engaged" ;
VAL_ 2566808574 FuelLevelWarning 1 "Fuel level warning on" 0 "Fuel level warning off" ;
VAL_ 2566808574 EngineOilPressureWarning 1 "Warning" 0 "No warning" ;
VAL_ 2566808574 EngineCoolantTempWarning 2 "Warning" 1 "Prewarning" 0 "No warning" ;
VAL_ 2564947710 VehicleType 1 "Dolly axle" 0 "Towing or towed vehicle" ;
VAL_ 2566834430 AntiTheftDeviceStatus 1 "Anti-theft device on" 0 "Anti-theft device off" ;
VAL_ 2566834430 ODDStatus 1 "ODD active" 0 "ODD inactive" ;
VAL_ 2566808318 SecEngineMtdPTOSwitch 1 "Switched on" 0 "Switched off" ;
VAL_ 2566808318 SecClutchDpdtPTOSwitch 1 "Switched on" 0 "Switched off" ;
VAL_ 2566808318 FirstClutchDpdtPTOSwitch 1 "Switched on" 0 "Switched off" ;
VAL_ 2566808318 OperatingPanelActive 1 "Operating panel active" 0 "Operating panel not active" ;
VAL_ 2566808318 RefusePackerStepSwitch 1 "Switched on" 0 "Switched off" ;
VAL_ 2566808318 EngineStopSwitch 1 "Switched on" 0 "Switched off" ;
VAL_ 2566808318 EngineStartSwitch 1 "Switched on" 0 "Switched off" ;
VAL_ 2566808318 StarterLockoutSwitch 1 "Switched on" 0 "Switched off" ;
VAL_ 2566808318 FirstEngineMtdPTOSwitch 1 "Switched on" 0 "Switched off" ;
VAL_ 2566808318 ClutchIndpdtPTOSwitch 1 "Switched on" 0 "Switched off" ;
VAL_ 2566808830 TrailerLeftSideMarkerLight 1 "Lamp(s) lit" 0 "Lamp(s) not lit" ;
VAL_ 2566808830 TrailerLeftReversingLight 1 "Lamp(s) lit" 0 "Lamp(s) not lit" ;
VAL_ 2566808830 TrailerLeftRearWidIndLight 1 "Lamp(s) lit" 0 "Lamp(s) not lit" ;
VAL_ 2566808830 TrailerLeftRearRegPltLight 1 "Lamp(s) lit" 0 "Lamp(s) not lit" ;
VAL_ 2566808830 TrailerLeftRearLight 1 "Lamp(s) lit" 0 "Lamp(s) not lit" ;
VAL_ 2566808830 TrailerLeftRearFogLight 1 "Lamp(s) lit" 0 "Lamp(s) not lit" ;
VAL_ 2566808830 TrailerLeftDirIndLight 1 "Lamp(s) lit" 0 "Lamp(s) not lit" ;
VAL_ 2566808830 TrailerLeftCrnMarkerLight 1 "Lamp(s) lit" 0 "Lamp(s) not lit" ;
VAL_ 2566808830 TrailerInteriorLight 1 "Lamp(s) lit" 0 "Lamp(s) not lit" ;
VAL_ 2566808830 TrailerWorkLamp 1 "Lamp(s) lit" 0 "Lamp(s) not lit" ;
VAL_ 2566808830 TrailerRotatingIdentLight 1 "Lamp(s) lit" 0 "Lamp(s) not lit" ;
VAL_ 2566808830 TrailerRightStopLight 1 "Lamp(s) lit" 0 "Lamp(s) not lit" ;
VAL_ 2566808830 TrailerRightSideMrkLight 1 "Lamp(s) lit" 0 "Lamp(s) not lit" ;
VAL_ 2566808830 TrailerRightReversingLight 1 "Lamp(s) lit" 0 "Lamp(s) not lit" ;
VAL_ 2566808830 TrailRightRearWidIndLight 1 "Lamp(s) lit" 0 "Lamp(s) not lit" ;
VAL_ 2566808830 TrailerRightRearRegPltLight 1 "Lamp(s) lit" 0 "Lamp(s) not lit" ;
VAL_ 2566808830 TrailerRightRearLight 1 "Lamp(s) lit" 0 "Lamp(s) not lit" ;
VAL_ 2566808830 TrailerRightRearFogLight 1 "Lamp(s) lit" 0 "Lamp(s) not lit" ;
VAL_ 2566808830 TrailerRightDirIndLight 1 "Lamp(s) lit" 0 "Lamp(s) not lit" ;
VAL_ 2566808830 TrailerRightCrnMarkerLight 1 "Lamp(s) lit" 0 "Lamp(s) not lit" ;
VAL_ 2566808830 TrailerRearWarningLight 1 "Lamp(s) lit" 0 "Lamp(s) not lit" ;
VAL_ 2566808830 TrailerLeftStopLight 1 "Lamp(s) lit" 0 "Lamp(s) not lit" ;
VAL_ 2564554494 FlowStatus 2 "Overflow" 1 "Wait " 0 "Continue To Send" ;
VAL_ 2564554494 ProtocolCtrlInformation 3 "Flow control " 2 "Consecutive frame" 1 "First frame" 0 "Single frame" ;
VAL_ 2564488958 FlowStatus 2 "Overflow" 1 "Wait " 0 "Continue To Send" ;
VAL_ 2564488958 ProtocolCtrlInformation 3 "Flow control " 2 "Consecutive frame" 1 "First frame" 0 "Single frame" ;
VAL_ 2565734142 ControlByte 6 "MFDB_CreateEntry" 5 "MFDB_SetMode" 4 "MFDB_Clear" 3 "MFDB_Delete" 2 "MFDB_Add" 1 "MFDB_Response" 0 "MFDB_Request" ;
VAL_ 2565734142 FilterMode 1 "PassSpecificPGNs" 0 "BlockSpecificPGNs" ;
VAL_ 2565144318 StopLevelChangeReq 3 "Take no action" 1 "Stop request" 0 "No stop request" ;
VAL_ 2565144318 RampLevelStorageReq 3 "Take no action" 1 "Store ramp level 2" 0 "Store ramp level 1" ;
VAL_ 2565144318 LevelControlReq 3 "Take no action" 1 "Enable level control" 0 "Disable level control" ;
VAL_ 2565144318 RampLevelReq 3 "Take no action" 1 "Ramp level 2" 0 "Ramp level 1" ;
VAL_ 2565144318 SteeringAxleLockingReq 3 "Take no action" 1 "Lock steering axle" 0 "Unlock steering axle" ;
VAL_ 2565144318 LiftAxle2PositionReq 3 "Take no action" 1 "Position up / tag axle unladen" 0 "Position down / tag axle laden" ;
VAL_ 2565144318 LiftAxle1PositionReq 3 "Don't care/take no action" 2 "Reserved" 1 "Position up / tag axle unladen" 0 "Position down / tag axle laden" ;
VAL_ 2565144318 TractionHelpReq 3 "Take no action" 1 "Traction help request" 0 "No traction help request" ;
VAL_ 2565144318 LevelChangeReqRearAxle 2 "Take no action" 1 "Vehicle body down (lowering)" 0 "Vehicle body up (lifting)" ;
VAL_ 2565144318 LevelChangeReqFrontAxle 2 "Take no action" 1 "Vehicle body down (lowering)" 0 "Vehicle body up (lifting)" ;
VAL_ 2565144318 RideHeightRequest 2 "Take no action" 1 "Normal level 2" 0 "Normal level 1" ;
VAL_ 2565209854 LevelControl 1 "Level control enabled" 0 "Level control disabled" ;
VAL_ 2565209854 RampLevel 1 "Body at requested ramp level" 0 "Body not at requested ramp level" ;
VAL_ 2565209854 NormalLevel 3 "Not available" 1 "Normal level 2" 0 "Normal level 1" ;
VAL_ 2565209854 StopLevelChangeAcknowledge 1 "Level change stopped" 0 "No stop request" ;
VAL_ 2565209854 LevelChangeRearAxle 1 "Body lifting/lowering active" 0 "Body lifting/lowering not active" ;
VAL_ 2565209854 LevelChangeFrontAxle 1 "Body lifting/lowering active" 0 "Body lifting/lowering not active" ;
VAL_ 2565209854 RampLevelStorage 1 "New ramp level stored" 0 "No new storage request" ;
VAL_ 2565209854 SteeringAxleLocking 1 "Steering axle locked" 0 "Steering axle unlocked" ;
VAL_ 2565209854 LiftAxle2Pos 3 "NotAvailable" 2 "Error" 1 "LiftAxlePosUp_TagAxleUnladen" 0 "LiftAxlePosDown_TagAxleLaden" ;
VAL_ 2565209854 LiftAxle1Pos 3 "NotAvailable" 2 "Error" 1 "LiftAxlePosUp_TagAxleUnladen" 0 "LiftAxlePosDown_TagAxleLaden" ;
VAL_ 2565209854 RampLevelPosition 3 "Not available" 1 "Ramp level 2" 0 "Ramp level 1" ;
VAL_ 2565209854 TractionHelp 1 "Traction help active" 0 "Traction help inactive" ;
VAL_ 2565209854 LevelCtrlSysRideHeightLevel 1 "Vehicle body at requested level" 0 "Vehicle body not at req. level" ;
VAL_ 2566807294 TyrePressThresholdDetect 7 "Not available" 6 "Error indicator" 5 "Not defined" 4 "Extreme under pressure" 3 "Under pressure" 2 "No warning pressure" 1 "Over pressure" 0 "Extreme over pressure" ;
VAL_ 2566807294 TyreModulePowerSupply 1 "Sufficient power supply" 0 "Insufficient power supply" ;
VAL_ 2566807294 TyreWheelIdentification2 15 "Axle position 15" 14 "Axle position 14" 13 "Axle position 13" 12 "Axle position 12" 11 "Axle position 11" 10 "Axle position 10" 9 "Axle position 9" 8 "Axle position 8" 7 "Axle position 7" 6 "Axle position 6" 5 "Axle position 5" 4 "Axle position 4" 3 "Axle position 3" 2 "Axle position 2" 1 "Axle position 1" 0 "Axle position not identified" ;
VAL_ 2566807294 TyreWheelIdentification1 15 "Wheel position 15" 14 "Wheel position 14" 13 "Wheel position 13" 12 "Wheel position 12" 11 "Wheel position 11" 10 "Wheel position 10" 9 "Wheel position 9" 8 "Wheel position 8" 7 "Wheel position 7" 6 "Wheel position 6" 5 "Wheel position 5" 4 "Wheel position 4" 3 "Wheel position 3" 2 "Wheel position 2" 1 "Wheel position 1" 0 "Wheel position not identified" ;
VAL_ 2566764798 MisfireMonitoringComplete 1 "EnabledForCycle" 0 "DisabledForRestOfCycle" ;
VAL_ 2566764798 MisfireMonitoringEnabled 1 "EnabledForCycle" 0 "DisabledForRestOfCycle" ;
VAL_ 2566764798 FuelSystemMonitoringEnabled 1 "NotCompleteCycle" 0 "CompleteCycleOrNotSupported" ;
VAL_ 2566764798 ComprehensiveComptMonComplete 1 "NotCompleteCycle" 0 "CompleteCycleOrNotSupported" ;
VAL_ 2566764798 ComprehensiveCompMonEnabled 1 "NotCompleteCycle" 0 "CompleteCycleOrNotSupported" ;
VAL_ 2566764798 SecondAirSystemMonComplete 1 "EnabledForCycle" 0 "DisabledForRestOfCycle" ;
VAL_ 2566764798 SecondAirSystemMonEnabled 1 "EnabledForCycle" 0 "DisabledForRestOfCycle" ;
VAL_ 2566764798 OxygenSensorMonComplete 1 "EnabledForCycle" 0 "DisabledForRestOfCycle" ;
VAL_ 2566764798 OxygenSensorMonEnabled 1 "NotCompleteCycle" 0 "CompleteCycleOrNotSupported" ;
VAL_ 2566764798 OxygenSensorHeaterMonComplete 1 "EnabledForCycle" 0 "DisabledForRestOfCycle" ;
VAL_ 2566764798 OxygenSensorHeaterMonEnabled 1 "NotCompleteCycle" 0 "CompleteCycleOrNotSupported" ;
VAL_ 2566764798 HeatedCatalystMonComplete 1 "EnabledForCycle" 0 "DisabledForRestOfCycle" ;
VAL_ 2566764798 HeatedCatalystMonEnabled 1 "EnabledForCycle" 0 "DisabledForRestOfCycle" ;
VAL_ 2566764798 EvaporativeSystemMonComplete 1 "NotCompleteCycle" 0 "CompleteCycleOrNotSupported" ;
VAL_ 2566764798 EvaporativeSystemMonEnabled 1 "NotCompleteCycle" 0 "CompleteCycleOrNotSupported" ;
VAL_ 2566764798 EGRSystemMonitoringComplete 1 "NotCompleteCycle" 0 "CompleteCycleOrNotSupported" ;
VAL_ 2566764798 EGRSystemMonitoringEnabled 1 "EnabledForCycle" 0 "DisabledForRestOfCycle" ;
VAL_ 2566764798 ColdStartAidSystemMonComplete 1 "EnabledForCycle" 0 "DisabledForRestOfCycle" ;
VAL_ 2566764798 ColdStartAidSystemMonEnabled 1 "EnabledForCycle" 0 "DisabledForRestOfCycle" ;
VAL_ 2566764798 CatalystMonComplete 1 "NotCompleteCycle" 0 "CompleteCycleOrNotSupported" ;
VAL_ 2566764798 CatalystMonEnabled 1 "NotCompleteCycle" 0 "CompleteCycleOrNotSupported" ;
VAL_ 2566764798 ACSystemRefrigerantMonComplete 1 "NotCompleteCycle" 0 "CompleteCycleOrNotSupported" ;
VAL_ 2566764798 ACSystemRefrigerantMonEnabled 1 "NotCompleteCycle" 0 "CompleteCycleOrNotSupported" ;
VAL_ 2566764798 FuelSystemMonitoringComplete 1 "NotCompleteCycle" 0 "CompleteCycleOrNotSupported" ;
VAL_ 2564095742 SecurityEntityType 3 "Data is Certificate" 2 "Data is Session Key" 1 "Data is Long Key" 0 "Data is Long Seed" ;
VAL_ 2349137662 XBRCtrlMode 3 "NotDefined" 2 "AcclrtnCtrlWthMxMdExctXBRAcclrt" 1 "AcclrtnCtrlWthAddtnMdAddXBRAccl" 0 "OvrrdDsbldDsblAnyExstngCtrlCmdd" ;
VAL_ 2349137662 XBRPriority 3 "LwPrrtyUsdInOvrrdDsbldXBRCtrlMd" 2 "MdmPrrtyUsdFrACCSystmsThsMdDsNt" 1 "HighPriorityNotDefined" 0 "HghstPrrtyUsdFrEmrgncySttnsEgFr" ;
VAL_ 2349137662 XBREBIMode 3 "NotDefined" 2 "EndranceBrakeIntegrationAllowed" 1 "OnlyEnduranceBrakesAllowed" 0 "NEndrnceBrakeIntegrationAllowed" ;
VAL_ 2566848510 WaterInFuelIndicator 3 "NotAvailable" 2 "Error" 1 "Yes" 0 "No" ;
VAL_ 2566809854 WinchOilPressSwitch 3 "NotAvailable" 2 "ErrrSwtchStteCannotBeDetermined" 1 "OKOilPressIsAboveMin" 0 "NOTOKOilPressIsTooLow" ;
VAL_ 2566809854 HydOilFilterRestrictionSwitch 3 "NotAvailable" 2 "Error" 1 "RestrictionExistsOnOilFitler" 0 "NoRestriction" ;
VAL_ 2565868030 SteerWheelAngleSensorType 3 "NotAvailable" 2 "Reserved" 1 "AbsMeasuringPrinciple" 0 "RelativeMeasuringPrinciple" ;
VAL_ 2566803454 YCBrakeCtrlActive 3 "DontCare_TakeNoAction" 2 "Reserved" 1 "YCBrakeCtrlActive" 0 "YCBrakeCtrlPassiveButInstalled" ;
VAL_ 2566803454 YCEngCtrlActive 3 "DontCare_TakeNoAction" 2 "Reserved" 1 "YCEngCtrlActive" 0 "YCEngCtrlPassiveButInstalled" ;
VAL_ 2566803454 ROPBrakeCtrlActive 3 "DontCare_TakeNoAction" 2 "Reserved" 1 "ROPBrakeCtrlActive" 0 "ROPBrakeCtrlPassiveButInstalled" ;
VAL_ 2566803454 ROPEngCtrlActive 3 "DontCare_TakeNoAction" 2 "Reserved" 1 "ROPEngCtrlActive" 0 "ROPEngCtrlPassiveButInstalled" ;
VAL_ 2566803454 VDCBrakeLightRq 3 "DontCare_TakeNoAction" 2 "Reserved" 1 "TurnBrakeLightOn" 0 "TurnBrakeLightNotOn" ;
VAL_ 2566803454 VDCFullyOperational 3 "DontCare_TakeNoAction" 2 "Reserved" 1 "FullyOperational" 0 "NotFullyOperational" ;
VAL_ 2566803454 VDCInformationSignal 3 "DontCare_TakeNoAction" 2 "Reserved" 1 "On" 0 "Off" ;
VAL_ 2348875518 ControlPurpose 5 "TemporaryPowerTrainControl" 4 "EngineProtection" 3 "RoadSpeedGovernor" 2 "PTOGovernor" 1 "CruiseControl" 0 "AcceleratorPedal" ;
VAL_ 2348875518 TransmissionRate 7 "UseStandardRate" 6 "25ms" 5 "50ms" 4 "100ms" 3 "250ms" 2 "500ms" 1 "750ms" 0 "1000ms" ;
VAL_ 2348875518 OverrideCtrlModePriority 3 "LowPriority" 2 "MdmPrrtyUsdFrPwrtrnCtrlOprtnsWh" 1 "HighPriority" 0 "HghstPrrtyUsdFrSttnsThtRqrImmdt" ;
VAL_ 2348875518 EngRqedSpeedCtrlConditions 2 "ThsCtrlCndtnHsBnOptmzdTMnmzRpmO" 3 "StbltyOptmzdFrDrvlnEnggdAnd_OrI" 1 "StbltyOptmzdFrDrvlnDsnggdAndNnl" 0 "ThsSpdGvrnrGnSlctnIsAdjstdTPrvd" ;
VAL_ 2348875518 EngOverrideCtrlMode 3 "Spd_TrqLmtCtrlLmtSpdAnd_OrTrqBs" 2 "TrqCtrlCntrlTrqTInclddDsrdTrqVl" 1 "SpdCtrlGvrnSpdTInclddDsrdSpdVle" 0 "OvrrdDsbldDsblAnyExstngCtrlCmdd" ;
VAL_ 2566766846 TransitRunStatus 3 "NotAvailable" 2 "ErrorCondition" 1 "On" 0 "Off" ;
VAL_ 2566766846 VehicleUseStatus 3 "NotAvailable" 2 "ErrorCondition" 1 "UnauthorizedUse" 0 "NormalUse" ;
VAL_ 2566766846 SilentAlarmStatus 3 "NotAvailable" 2 "ErrorCondition" 1 "On" 0 "Off" ;
VAL_ 2566766846 TypeOfPassengerCount 1 "BoardingPassenger" 0 "AbsPassengerCount" 4 "Exiting Passenger (second passenger stream)" 3 "Boarding Passenger (second passenger stream)" 2 "Exiting Passenger" ;
VAL_ 2566765310 FareboxAlarmIdentifier 97 "1111111AgencyDefined" 26 "1100000ReservedToBeAssigned" 25 "MaintenanceAccessOutOfService" 24 "MntnncAccssInSrvcCnsdrdAnAlrmCn" 23 "PaperCurrencyJamCleared" 22 "PaperCurrencyJam" 21 "Pass_TransferJamCleared" 20 "Pass_TransferJam" 19 "FareboxResetToAutomaticMode" 18 "FareboxSetInManualBypass" 17 "CoinDejamOperated" 16 "Card_PassBoxFull" 15 "Card_PassBoxLessThan75Full" 14 "Card_PassBox75Full" 13 "CurrencyBoxFull" 12 "CurrencyBoxLessThan75Full" 11 "CurrencyBox75Full" 10 "CoinboxFull" 9 "Coinbox75Full" 8 "InsufficientFareAccepted" 7 "CshbxOpndInSrvcCnsdrdAnAlrmCndt" 6 "CashboxDoorTimeout" 5 "CashboxRestored" 4 "CashboxRemoved" 3 "ProbeCompleted" 2 "ProbeStarted" 1 "VoltageRestored" 0 "VoltageDropout" ;
VAL_ 2566765310 FareboxEmergencyStatus 3 "NotAvailable" 2 "ErrorCondition" 1 "EmergencyCondition" 0 "NonemergencyCondition" ;
VAL_ 2566765566 TransferType 6 "11111AgencyDefined" 5 "Out" 4 "In" 3 "West" 2 "East" 1 "South" 0 "North" ;
VAL_ 2566765566 TypeOfService 2 "111AgencyDefined" 1 "ExpressService" 0 "LocalService" ;
VAL_ 2566765566 PaymentDetails 11 "1111AgencyDefined" 6 "1010ReservedForAssignment" 5 "Card" 4 "Pass" 3 "Ticket" 2 "Token" 1 "Cash" 0 "NotAnUpgrade" ;
VAL_ 2566765566 TypeOfFare 11 "1111AgencyDefined" 7 "1010ReservedForAssignment" 6 "PassB" 5 "PassA" 4 "TicketB" 3 "TicketA" 2 "TokenB" 1 "TokenA" 0 "Cash_NoDetail" ;
VAL_ 2566765566 TransactionType 12 "1111AgencyDefined" 8 "1011ReservedForAssignment" 7 "Free" 6 "Transfer" 5 "Permit" 4 "Card" 3 "Pass" 2 "Ticket" 1 "Token" 0 "Cash" ;
VAL_ 2566765822 DriversFareboxSecurityCode 1 "65535SecurityCode" 0 "Farebox is in reporting status" ;
VAL_ 2566765822 TripDirection 6 "1111AgencyDefined" 5 "Out" 4 "In" 3 "West" 2 "East" 1 "South" 0 "North" ;
VAL_ 2566765822 TripStatus 6 "LayoverEnd" 5 "LayoverStart" 2 "TripEnd" 1 "TripStart" 7 "Undefined" ;
VAL_ 2566765822 FareboxServiceStatus 3 "NotAvailable" 2 "ErrorCondition" 1 "FareboxInService" 0 "FareboxOutOfService" ;
VAL_ 2566766078 StrobeActivationCtrlStatus 3 "NotAvailable" 2 "ErrorCondition" 1 "ActivateStrobe" 0 "DeactiveStrobe" ;
VAL_ 2566766078 TransitDoorEnable 3 "NotAvailable" 2 "ErrorCondition" 1 "TrnstDrSttsWllOvrrdStrbActvtion" 0 "IgnoreTransitDoorStatus" ;
VAL_ 2566766078 PriorityOfRespSentByEmitter 15 "NotAvailable" 14 "ErrorCondition" 12 "to1101Reserved" 11 "PrrtyStByHardwareToHighPriority" 10 "PrrtyStByHrdwareToProbePriority" 9 "PrrtySetByHardwareToLowPriority" 4 "to1000Reserved" 3 "HighPriority" 2 "ProbePriority" 1 "LowPriority" 0 "Reserved" ;
VAL_ 2566766078 IntersectionPreemptionRq_Resp 3 "NotAvailable" 2 "ErrorCondition" 1 "MessageIsARespFromEmitter" 0 "MessageIsARqDirectedToEmitter" ;
VAL_ 2566766078 TransitRouteIDUsage 3 "NotAvailable" 2 "ErrorCondition" 1 "TrnstRtIDUsedForInterleavedData" 0 "TrnstRtIDNtUsdFrInterleavedData" ;
VAL_ 2566766078 RangeCodeEnable 3 "NotAvailable" 2 "ErrorCondition" 1 "RangeCodeUsedForInterleavedData" 0 "RngCdeNotUsedForInterleavedData" ;
VAL_ 2633922814 PCUSupplySolenoidStatus 3 "NotAvailable" 2 "Error" 1 "On" 0 "Off" ;
VAL_ 2633922814 PCUCtrlSolenoidStatus 3 "NotAvailable" 2 "Error" 1 "On" 0 "Off" ;
VAL_ 2633922814 PCUDeflateSolenoidStatus 3 "NotAvailable" 2 "Error" 1 "On" 0 "Off" ;
VAL_ 2633922814 TirePressSupplySwitchStatus 3 "NotAvailable" 2 "Error" 1 "On" 0 "Off" ;
VAL_ 2633922814 PCUSteerSolenoidStatus 3 "NotAvailable" 2 "Error" 1 "On" 0 "Off" ;
VAL_ 2633922814 PCUDriveSolenoidStatus 3 "NotAvailable" 2 "Error" 1 "On" 0 "Off" ;
VAL_ 2633922814 DriveChannelMode 15 "NotAvailable" 14 "ErrorCondition" 7 "1101Reserved" 6 "PressCheck" 5 "DfltWtSystmWllDfltWhnCndtnsAllw" 4 "InfltWtSystmWllInfltWhnCndtnsAl" 3 "Confirm" 2 "Deflate" 1 "Inflate" 0 "Maintain" ;
VAL_ 2633922814 Trailer_TagChannelMode 15 "NotAvailable" 14 "ErrorCondition" 7 "1101Reserved" 6 "PressCheck" 5 "DfltWtSystmWllDfltWhnCndtnsAllw" 4 "InfltWtSystmWllInfltWhnCndtnsAl" 3 "Confirm" 2 "Deflate" 1 "Inflate" 0 "Maintain" ;
VAL_ 2633922814 SteerChannelMode 15 "NotAvailable" 14 "ErrorCondition" 7 "1101Reserved" 6 "PressCheck" 5 "DfltWtSystmWllDfltWhnCndtnsAllw" 4 "InfltWtSystmWllInfltWhnCndtnsAl" 3 "Confirm" 2 "Deflate" 1 "Inflate" 0 "Maintain" ;
VAL_ 2633922814 PCUTrailerTagPushSolenoidStatus 3 "NotAvailable" 2 "Error" 1 "On" 0 "Off" ;
VAL_ 2566845694 TirePressThresholdDetection 7 "NotAvailable" 6 "ErrorIndicator" 5 "NotDefined" 4 "ExtrmUndrPrssTrPrssrIsAtALvlWhr" 3 "UndrPrssTrPrssrIsLwrThnThPrssrD" 2 "NWrnngPrssTrPrssrIsWthnThThrshl" 1 "OvrPrssTrPrssrIsHghrThnThPrssrD" 0 "ExtrmOvrPrssTrPrssrIsAtALvlWhrT" ;
VAL_ 2566845694 CTIWheelEndElectricalFault 3 "NotSupported" 2 "Error" 1 "NotDefined" 0 "Ok" ;
VAL_ 2566845694 CTITireStatus 3 "NotSupported" 2 "Error" 1 "TireLeakDetected" 0 "Ok" ;
VAL_ 2566845694 CTIWheelSensorStatus 3 "NotSupported" 2 "NotDefined" 1 "On" 0 "Off_IsolatedFromCTIPressCtrl" ;
VAL_ 2365484286 DirectionIndicator 3 "NotAvailable" 2 "Error" 1 "Reverse" 0 "Forward" ;
VAL_ 2365484286 TachographPerformance 3 "NotAvailable" 2 "Error" 1 "PerformanceAnalysis" 0 "NormalPerformance" ;
VAL_ 2365484286 HandlingInformation 3 "NotAvailable" 2 "Error" 1 "HandlingInformation" 0 "NoHandlingInformation" ;
VAL_ 2365484286 SystemEvent 3 "NotAvailable" 2 "Error" 1 "TachographEvent" 0 "NoTachographEvent" ;
VAL_ 2365484286 DriverCardDriver2 3 "NotAvailable" 2 "Error" 1 "DriverCardPresent" 0 "DriverCardNotPresent" ;
VAL_ 2365484286 Driver2TimeRelatedStates 15 "NotAvailable" 14 "Error" 13 "Other" 7 "1100Reserved" 6 "Limit616HReached" 5 "Limit515MinBefore16H" 4 "Limit49HReached" 3 "Limit315MinBefore9H" 2 "Limit24HReached" 1 "Limit115MinBefore4H" 0 "Normal_NoLimitsReached" ;
VAL_ 2365484286 Overspeed 3 "NotAvailable" 2 "Error" 1 "Overspeed" 0 "NoOverspeed" ;
VAL_ 2365484286 DriverCardDriver1 3 "NotAvailable" 2 "Error" 1 "DriverCardPresent" 0 "DriverCardNotPresent" ;
VAL_ 2365484286 Driver1TimeRelatedStates 15 "NotAvailable" 14 "Error" 13 "Other" 7 "1100Reserved" 6 "Limit616HReached" 5 "Limit515MinBefore16H" 4 "Limit49HReached" 3 "Limit315MinBefore9H" 2 "Limit24HReached" 1 "Limit115MinBefore4H" 0 "Normal_NoLimitsReached" ;
VAL_ 2365484286 DriveRecognize 3 "NotAvailable" 2 "Error" 1 "VehicleMotionDetected" 0 "VehicleMotionNotDetected" ;
VAL_ 2365484286 Driver2WorkingState 7 "NotAvailable" 6 "Error" 4 "101Reserved" 3 "DriveBehindWheel" 2 "WrkLdngUnldingWorkingInAnOffice" 1 "DriverAvailableShortBreak" 0 "RestSleeping" ;
VAL_ 2365484286 Driver1WorkingState 7 "NotAvailable" 6 "Error" 4 "101Reserved" 3 "DriveBehindWheel" 2 "WrkLdngUnldingWorkingInAnOffice" 1 "DriverAvailableShortBreak" 0 "RestSleeping" ;
